VERSION ""

NS_ :

BS_:

BU_: ETH

BO_ 1298 TRCM_alertLog: 8 Vector__XXX
 SG_ TRCM_alertID M : 0|10@1+ (1,0) [0|0] "" Vector__XXX
 SG_ TRCM_alertState : 15|1@1+ (1,0) [0|0] "" Vector__XXX
 SG_ TRCM_a003_AssertID m3 : 16|16@1+ (1,0) [0|0] "" Vector__XXX
 SG_ TRCM_a005_busID0 m5 : 16|4@1+ (1,0) [0|0] "" Vector__XXX
 SG_ TRCM_a006_busID m6 : 16|4@1+ (1,0) [0|0] "" Vector__XXX
 SG_ TRCM_a007_messageId m7 : 16|16@1+ (1,0) [0|0] "" Vector__XXX
 SG_ TRCM_a008_messageId m8 : 16|16@1+ (1,0) [0|0] "" Vector__XXX
 SG_ TRCM_a009_messageId m9 : 16|16@1+ (1,0) [0|0] "" Vector__XXX
 SG_ TRCM_a010_messageId m10 : 16|16@1+ (1,0) [0|0] "" Vector__XXX
 SG_ TRCM_a011_lockedEdrLogCount m11 : 16|8@1+ (1,0) [0|0] "" Vector__XXX
 SG_ TRCM_a012_tempData m12 : 16|16@1- (0.06897,25) [0|0] "" Vector__XXX
 SG_ TRCM_a013_LogQueueFull m13 : 16|1@1+ (1,0) [0|0] "" Vector__XXX
 SG_ TRCM_a014_tempData m14 : 16|16@1- (0.06897,25) [0|0] "" Vector__XXX
 SG_ TRCM_a015_NVMMMemOverflow m15 : 16|1@1+ (1,0) [0|0] "" Vector__XXX
 SG_ TRCM_a016_NVMMRecordID m16 : 16|16@1+ (1,0) [0|0] "" Vector__XXX
 SG_ TRCM_a017_tempData m17 : 16|16@1- (0.06897,25) [0|0] "" Vector__XXX
 SG_ TRCM_a018_tempData m18 : 16|16@1- (0.06897,25) [0|0] "" Vector__XXX
 SG_ TRCM_a019_Task500usLate m19 : 16|1@1+ (1,0) [0|0] "" Vector__XXX
 SG_ TRCM_a020_Ana2_OK m20 : 16|1@1+ (1,0) [0|0] "" Vector__XXX
 SG_ TRCM_a021_Task1msLate m21 : 16|1@1+ (1,0) [0|0] "" Vector__XXX
 SG_ TRCM_a022_TaskInitErrorCount m22 : 16|8@1+ (1,0) [0|0] "" Vector__XXX
 SG_ TRCM_a023_Rate_Ref_OK_X m23 : 16|1@1+ (1,0) [0|0] "" Vector__XXX
 SG_ TRCM_a024_XLSelfTestAuto_OK_Z m24 : 16|1@1+ (1,0) [0|0] "" Vector__XXX
 SG_ TRCM_a025_busStatus m25 : 16|2@1+ (1,0) [0|0] "" Vector__XXX
 SG_ TRCM_a026_diagnosticFaultReason m26 : 16|3@1+ (1,0) [0|0] "" Vector__XXX
 SG_ TRCM_a027_deploymentDiagnosticFaultReason m27 : 16|3@1+ (1,0) [0|0] "" Vector__XXX
 SG_ TRCM_a030_logId m30 : 16|4@1+ (1,0) [0|0] "" Vector__XXX
 SG_ TRCM_a031_uds_bytes_0 m31 : 16|8@1+ (1,0) [0|0] "" Vector__XXX
 SG_ TRCM_a032_logCrc m32 : 16|32@1+ (1,0) [0|0] "" Vector__XXX
 SG_ TRCM_a033_logCrc m33 : 16|32@1+ (1,0) [0|0] "" Vector__XXX
 SG_ TRCM_a036_collisionType m36 : 16|4@1+ (1,0) [0|0] "" Vector__XXX
 SG_ TRCM_a037_nearDeployFront m37 : 16|1@1+ (1,0) [0|0] "" Vector__XXX
 SG_ TRCM_a038_stuckLowOrOpenCircuit m38 : 16|1@1+ (1,0) [0|0] "" Vector__XXX
 SG_ TRCM_a039_stuckLowOrOpenCircuit m39 : 16|1@1+ (1,0) [0|0] "" Vector__XXX
 SG_ TRCM_a040_airbagAsicsFaultReason m40 : 16|3@1+ (1,0) [0|0] "" Vector__XXX
 SG_ TRCM_a041_CPULoadTotal m41 : 16|8@1+ (1,0) [0|0] "" Vector__XXX
 SG_ TRCM_a042_Usage1msTask m42 : 16|8@1+ (1,0) [0|0] "" Vector__XXX
 SG_ TRCM_a043_CallTrace0 m43 : 16|24@1+ (1,0) [0|0] "" Vector__XXX
 SG_ TRCM_a044_CallTrace0 m44 : 16|24@1+ (1,0) [0|0] "" Vector__XXX
 SG_ TRCM_a045_CallTrace0 m45 : 16|24@1+ (1,0) [0|0] "" Vector__XXX
 SG_ TRCM_a046_CallTrace0 m46 : 16|24@1+ (1,0) [0|0] "" Vector__XXX
 SG_ TRCM_a049_retryCount m49 : 16|4@1+ (1,0) [0|0] "" Vector__XXX
 SG_ TRCM_a051_airbagAsicStartupDiagnosticsOngoing m51 : 16|1@1+ (1,0) [0|0] "" Vector__XXX
 SG_ TRCM_a057_VEH_cpControl m57 : 16|1@1+ (1,0) [0|0] "" Vector__XXX
 SG_ TRCM_a058_voltageDrop m58 : 16|12@1+ (0.005443676098,0) [0|0] "" Vector__XXX
 SG_ TRCM_a059_voltageDrop m59 : 16|12@1+ (0.005443676098,0) [0|0] "" Vector__XXX
 SG_ TRCM_a060_lockoutDisabled m60 : 16|1@1+ (1,0) [0|0] "" Vector__XXX
 SG_ TRCM_a063_switchChannel m63 : 16|8@1+ (1,0) [0|0] "" Vector__XXX
 SG_ TRCM_a064_busBitField m64 : 16|8@1+ (1,0) [0|0] "" Vector__XXX
 SG_ TRCM_a065_vsafingFetVoltage m65 : 16|9@1+ (0.05,0) [0|0] "" Vector__XXX
 SG_ TRCM_a066_busVoltage m66 : 16|9@1+ (0.05,0) [0|0] "" Vector__XXX
 SG_ TRCM_a067_busVoltage m67 : 16|9@1+ (0.05,0) [0|0] "" Vector__XXX
 SG_ TRCM_a068_busVoltage m68 : 16|9@1+ (0.05,0) [0|0] "" Vector__XXX
 SG_ TRCM_a069_resetCause m69 : 16|4@1+ (1,0) [0|0] "" Vector__XXX
 SG_ TRCM_a070_crcOkay m70 : 16|1@1+ (1,0) [0|0] "" Vector__XXX
 SG_ TRCM_a072_crcOkay m72 : 16|1@1+ (1,0) [0|0] "" Vector__XXX
 SG_ TRCM_a074_received m74 : 16|16@1- (1,0) [0|0] "" Vector__XXX
 SG_ TRCM_a075_received m75 : 16|16@1- (1,0) [0|0] "" Vector__XXX
 SG_ TRCM_a076_received m76 : 16|16@1- (1,0) [0|0] "" Vector__XXX
 SG_ TRCM_a077_received m77 : 16|16@1- (1,0) [0|0] "" Vector__XXX
 SG_ TRCM_a078_channelIndex m78 : 16|8@1+ (1,0) [0|0] "" Vector__XXX
 SG_ TRCM_a082_RIPC_epbPrivateState m82 : 16|1@1+ (1,0) [0|0] "" Vector__XXX
 SG_ TRCM_a083_LIPC_epbPrivateState m83 : 16|1@1+ (1,0) [0|0] "" Vector__XXX
 SG_ TRCM_a084_CH_StatusC m84 : 16|1@1+ (1,0) [0|0] "" Vector__XXX
 SG_ TRCM_a085_PARTY_buttonStatus m85 : 16|1@1+ (1,0) [0|0] "" Vector__XXX
 SG_ TRCM_a086_VEH_LVBMS_statusHigh m86 : 16|1@1+ (1,0) [0|0] "" Vector__XXX
 SG_ TRCM_a087_VEH_temperature m87 : 16|1@1+ (1,0) [0|0] "" Vector__XXX
 SG_ TRCM_a088_VEH_temperature m88 : 16|1@1+ (1,0) [0|0] "" Vector__XXX
 SG_ TRCM_a089_PARTY_party1 m89 : 16|1@1+ (1,0) [0|0] "" Vector__XXX
 SG_ TRCM_a090_VEH_chNm m90 : 16|1@1+ (1,0) [0|0] "" Vector__XXX
 SG_ TRCM_a091_VEH_faultsAndExtras m91 : 16|1@1+ (1,0) [0|0] "" Vector__XXX
 SG_ TRCM_a092_VEH_restraintStatus m92 : 16|1@1+ (1,0) [0|0] "" Vector__XXX
 SG_ TRCM_a093_VEH_restraintStatus m93 : 16|1@1+ (1,0) [0|0] "" Vector__XXX
 SG_ TRCM_a094_VEH_sysStatus m94 : 16|1@1+ (1,0) [0|0] "" Vector__XXX
 SG_ TRCM_a095_PT_ptNm m95 : 16|1@1+ (1,0) [0|0] "" Vector__XXX
 SG_ TRCM_a096_VEH_status m96 : 16|1@1+ (1,0) [0|0] "" Vector__XXX
 SG_ TRCM_a097_VEH_HVStatus m97 : 16|1@1+ (1,0) [0|0] "" Vector__XXX
 SG_ TRCM_a098_CH_torque m98 : 16|1@1+ (1,0) [0|0] "" Vector__XXX
 SG_ TRCM_a099_VEH_oocStatus m99 : 16|1@1+ (1,0) [0|0] "" Vector__XXX
 SG_ TRCM_a100_VEH m100 : 16|1@1+ (1,0) [0|0] "" Vector__XXX
 SG_ TRCM_a101_VEH_state m101 : 16|1@1+ (1,0) [0|0] "" Vector__XXX
 SG_ TRCM_a102_VEH_faultsAndExtras m102 : 16|1@1+ (1,0) [0|0] "" Vector__XXX
 SG_ TRCM_a103_VEH_hvsNm m103 : 16|1@1+ (1,0) [0|0] "" Vector__XXX
 SG_ TRCM_a104_VEH_chNm m104 : 16|1@1+ (1,0) [0|0] "" Vector__XXX
 SG_ TRCM_a105_VEH_states m105 : 16|1@1+ (1,0) [0|0] "" Vector__XXX
 SG_ TRCM_a106_VEH_dcdcStatus m106 : 16|1@1+ (1,0) [0|0] "" Vector__XXX
 SG_ TRCM_a107_VEH_hvsNm m107 : 16|1@1+ (1,0) [0|0] "" Vector__XXX
 SG_ TRCM_a108_VEH_hvStatus m108 : 16|1@1+ (1,0) [0|0] "" Vector__XXX
 SG_ TRCM_a109_PARTY_status m109 : 16|1@1+ (1,0) [0|0] "" Vector__XXX
 SG_ TRCM_a110_VEH_carState m110 : 16|1@1+ (1,0) [0|0] "" Vector__XXX
 SG_ TRCM_a111_VEH_internalStatus m111 : 16|1@1+ (1,0) [0|0] "" Vector__XXX
 SG_ TRCM_a112_VEH_internalStatus m112 : 16|1@1+ (1,0) [0|0] "" Vector__XXX
 SG_ TRCM_a113_VEH_ethNm m113 : 16|1@1+ (1,0) [0|0] "" Vector__XXX
 SG_ TRCM_a114_PARTY_status m114 : 16|1@1+ (1,0) [0|0] "" Vector__XXX
 SG_ TRCM_a115_VEH_vehNm m115 : 16|1@1+ (1,0) [0|0] "" Vector__XXX
 SG_ TRCM_a116_PARTY_epbmStatus m116 : 16|1@1+ (1,0) [0|0] "" Vector__XXX
 SG_ TRCM_a117_BDY_epbmStatus m117 : 16|1@1+ (1,0) [0|0] "" Vector__XXX
 SG_ TRCM_a118_VEH_vehNm m118 : 16|1@1+ (1,0) [0|0] "" Vector__XXX
 SG_ TRCM_a119_VEH_steerAngle m119 : 16|1@1+ (1,0) [0|0] "" Vector__XXX
 SG_ TRCM_a120_PARTY_chassisCntl m120 : 16|1@1+ (1,0) [0|0] "" Vector__XXX
 SG_ TRCM_a135_crcOkay m135 : 16|1@1+ (1,0) [0|0] "" Vector__XXX
 SG_ TRCM_a137_rxFrame m137 : 16|32@1+ (1,0) [0|0] "" Vector__XXX
 SG_ TRCM_a138_rxFrame m138 : 16|32@1+ (1,0) [0|0] "" Vector__XXX
 SG_ TRCM_a145_noData m145 : 16|1@1+ (1,0) [0|0] "" Vector__XXX
 SG_ TRCM_a146_reason m146 : 16|3@1+ (1,0) [0|0] "" Vector__XXX
 SG_ TRCM_a147_shortToGround m147 : 16|1@1+ (1,0) [0|0] "" Vector__XXX
 SG_ TRCM_a148_customerSensorCode m148 : 16|12@1+ (1,0) [0|0] "" Vector__XXX
 SG_ TRCM_a149_channelIndex m149 : 16|8@1+ (1,0) [0|0] "" Vector__XXX
 SG_ TRCM_a150_noData m150 : 16|1@1+ (1,0) [0|0] "" Vector__XXX
 SG_ TRCM_a151_reason m151 : 16|3@1+ (1,0) [0|0] "" Vector__XXX
 SG_ TRCM_a152_shortToGround m152 : 16|1@1+ (1,0) [0|0] "" Vector__XXX
 SG_ TRCM_a153_customerSensorCode m153 : 16|12@1+ (1,0) [0|0] "" Vector__XXX
 SG_ TRCM_a154_channelIndex m154 : 16|8@1+ (1,0) [0|0] "" Vector__XXX
 SG_ TRCM_a155_noData m155 : 16|1@1+ (1,0) [0|0] "" Vector__XXX
 SG_ TRCM_a156_reason m156 : 16|3@1+ (1,0) [0|0] "" Vector__XXX
 SG_ TRCM_a157_shortToGround m157 : 16|1@1+ (1,0) [0|0] "" Vector__XXX
 SG_ TRCM_a158_customerSensorCode m158 : 16|12@1+ (1,0) [0|0] "" Vector__XXX
 SG_ TRCM_a159_channelIndex m159 : 16|8@1+ (1,0) [0|0] "" Vector__XXX
 SG_ TRCM_a160_noData m160 : 16|1@1+ (1,0) [0|0] "" Vector__XXX
 SG_ TRCM_a161_reason m161 : 16|3@1+ (1,0) [0|0] "" Vector__XXX
 SG_ TRCM_a162_shortToGround m162 : 16|1@1+ (1,0) [0|0] "" Vector__XXX
 SG_ TRCM_a163_customerSensorCode m163 : 16|12@1+ (1,0) [0|0] "" Vector__XXX
 SG_ TRCM_a164_channelIndex m164 : 16|8@1+ (1,0) [0|0] "" Vector__XXX
 SG_ TRCM_a165_noData m165 : 16|1@1+ (1,0) [0|0] "" Vector__XXX
 SG_ TRCM_a166_reason m166 : 16|3@1+ (1,0) [0|0] "" Vector__XXX
 SG_ TRCM_a167_shortToGround m167 : 16|1@1+ (1,0) [0|0] "" Vector__XXX
 SG_ TRCM_a168_customerSensorCode m168 : 16|12@1+ (1,0) [0|0] "" Vector__XXX
 SG_ TRCM_a169_channelIndex m169 : 16|8@1+ (1,0) [0|0] "" Vector__XXX
 SG_ TRCM_a170_noData m170 : 16|1@1+ (1,0) [0|0] "" Vector__XXX
 SG_ TRCM_a171_reason m171 : 16|3@1+ (1,0) [0|0] "" Vector__XXX
 SG_ TRCM_a172_shortToGround m172 : 16|1@1+ (1,0) [0|0] "" Vector__XXX
 SG_ TRCM_a173_customerSensorCode m173 : 16|12@1+ (1,0) [0|0] "" Vector__XXX
 SG_ TRCM_a174_channelIndex m174 : 16|8@1+ (1,0) [0|0] "" Vector__XXX
 SG_ TRCM_a175_noData m175 : 16|1@1+ (1,0) [0|0] "" Vector__XXX
 SG_ TRCM_a176_reason m176 : 16|3@1+ (1,0) [0|0] "" Vector__XXX
 SG_ TRCM_a177_shortToGround m177 : 16|1@1+ (1,0) [0|0] "" Vector__XXX
 SG_ TRCM_a178_customerSensorCode m178 : 16|12@1+ (1,0) [0|0] "" Vector__XXX
 SG_ TRCM_a179_channelIndex m179 : 16|8@1+ (1,0) [0|0] "" Vector__XXX
 SG_ TRCM_a200_noData m200 : 16|1@1+ (1,0) [0|0] "" Vector__XXX
 SG_ TRCM_a201_reason m201 : 16|3@1+ (1,0) [0|0] "" Vector__XXX
 SG_ TRCM_a202_shortToGround m202 : 16|1@1+ (1,0) [0|0] "" Vector__XXX
 SG_ TRCM_a203_customerSensorCode m203 : 16|12@1+ (1,0) [0|0] "" Vector__XXX
 SG_ TRCM_a204_channelIndex m204 : 16|8@1+ (1,0) [0|0] "" Vector__XXX
 SG_ TRCM_a205_noData m205 : 16|1@1+ (1,0) [0|0] "" Vector__XXX
 SG_ TRCM_a206_reason m206 : 16|3@1+ (1,0) [0|0] "" Vector__XXX
 SG_ TRCM_a207_shortToGround m207 : 16|1@1+ (1,0) [0|0] "" Vector__XXX
 SG_ TRCM_a208_customerSensorCode m208 : 16|12@1+ (1,0) [0|0] "" Vector__XXX
 SG_ TRCM_a209_channelIndex m209 : 16|8@1+ (1,0) [0|0] "" Vector__XXX
 SG_ TRCM_a272_Ana2_OK m272 : 16|1@1+ (1,0) [0|0] "" Vector__XXX
 SG_ TRCM_a273_Rate_Ref_OK_X m273 : 16|1@1+ (1,0) [0|0] "" Vector__XXX
 SG_ TRCM_a274_Rate_Ref_OK_Z m274 : 16|1@1+ (1,0) [0|0] "" Vector__XXX
 SG_ TRCM_a275_XLSelfTestAuto_OK_Z m275 : 16|1@1+ (1,0) [0|0] "" Vector__XXX
 SG_ TRCM_a276_watchdogBiteCount m276 : 16|8@1+ (1,0) [0|0] "" Vector__XXX
 SG_ TRCM_a332_groundLossError m332 : 16|1@1+ (1,0) [0|0] "" Vector__XXX
 SG_ TRCM_a333_groundLossError m333 : 16|1@1+ (1,0) [0|0] "" Vector__XXX
 SG_ TRCM_a334_groundLossError m334 : 16|1@1+ (1,0) [0|0] "" Vector__XXX
 SG_ TRCM_a335_groundLossError m335 : 16|1@1+ (1,0) [0|0] "" Vector__XXX
 SG_ TRCM_a336_groundLossError m336 : 16|1@1+ (1,0) [0|0] "" Vector__XXX
 SG_ TRCM_a337_groundLossError m337 : 16|1@1+ (1,0) [0|0] "" Vector__XXX
 SG_ TRCM_a340_groundLossError m340 : 16|1@1+ (1,0) [0|0] "" Vector__XXX
 SG_ TRCM_a341_groundLossError m341 : 16|1@1+ (1,0) [0|0] "" Vector__XXX
 SG_ TRCM_a342_groundLossError m342 : 16|1@1+ (1,0) [0|0] "" Vector__XXX
 SG_ TRCM_a343_groundLossError m343 : 16|1@1+ (1,0) [0|0] "" Vector__XXX
 SG_ TRCM_a344_groundLossError m344 : 16|1@1+ (1,0) [0|0] "" Vector__XXX
 SG_ TRCM_a345_groundLossError m345 : 16|1@1+ (1,0) [0|0] "" Vector__XXX
 SG_ TRCM_a346_groundLossError m346 : 16|1@1+ (1,0) [0|0] "" Vector__XXX
 SG_ TRCM_a347_groundLossError m347 : 16|1@1+ (1,0) [0|0] "" Vector__XXX
 SG_ TRCM_a348_groundLossError m348 : 16|1@1+ (1,0) [0|0] "" Vector__XXX
 SG_ TRCM_a349_groundLossError m349 : 16|1@1+ (1,0) [0|0] "" Vector__XXX
 SG_ TRCM_a350_groundLossError m350 : 16|1@1+ (1,0) [0|0] "" Vector__XXX
 SG_ TRCM_a351_groundLossError m351 : 16|1@1+ (1,0) [0|0] "" Vector__XXX
 SG_ TRCM_a352_groundLossError m352 : 16|1@1+ (1,0) [0|0] "" Vector__XXX
 SG_ TRCM_a353_groundLossError m353 : 16|1@1+ (1,0) [0|0] "" Vector__XXX
 SG_ TRCM_a354_groundLossError m354 : 16|1@1+ (1,0) [0|0] "" Vector__XXX
 SG_ TRCM_a355_groundLossError m355 : 16|1@1+ (1,0) [0|0] "" Vector__XXX
 SG_ TRCM_a387_resetSource m387 : 16|8@1+ (1,0) [0|0] "" Vector__XXX
 SG_ TRCM_a388_cpuLoadPercentage m388 : 16|20@1+ (0.0001,0) [0|0] "" Vector__XXX
 SG_ TRCM_a389_boostGroundLoss m389 : 16|1@1+ (1,0) [0|0] "" Vector__XXX
 SG_ TRCM_a390_clockStuckError m390 : 16|1@1+ (1,0) [0|0] "" Vector__XXX
 SG_ TRCM_a391_clockStuckError m391 : 16|1@1+ (1,0) [0|0] "" Vector__XXX
 SG_ TRCM_a392_clockStuckError m392 : 16|1@1+ (1,0) [0|0] "" Vector__XXX
 SG_ TRCM_a393_measurementRatio m393 : 16|7@1+ (1,0) [0|0] "" Vector__XXX
 SG_ TRCM_a394_parityIncorrect m394 : 16|1@1+ (1,0) [0|0] "" Vector__XXX
 SG_ TRCM_a396_errorType m396 : 16|2@1+ (1,0) [0|0] "" Vector__XXX
 SG_ TRCM_a397_errorType m397 : 16|3@1+ (1,0) [0|0] "" Vector__XXX
 SG_ TRCM_a398_oldAsicNvmValue m398 : 16|16@1+ (1,0) [0|0] "" Vector__XXX
 SG_ TRCM_a400_deploymentLoopNumber m400 : 16|5@1+ (1,0) [0|0] "" Vector__XXX
 SG_ TRCM_a401_deploymentLoopNumber m401 : 16|5@1+ (1,0) [0|0] "" Vector__XXX
 SG_ TRCM_a402_deploymentLoopNumber m402 : 16|5@1+ (1,0) [0|0] "" Vector__XXX
 SG_ TRCM_a403_deploymentLoopNumber m403 : 16|5@1+ (1,0) [0|0] "" Vector__XXX
 SG_ TRCM_a404_deploymentLoopNumber m404 : 16|5@1+ (1,0) [0|0] "" Vector__XXX
 SG_ TRCM_a405_deploymentLoopNumber m405 : 16|5@1+ (1,0) [0|0] "" Vector__XXX
 SG_ TRCM_a408_deploymentLoopNumber m408 : 16|5@1+ (1,0) [0|0] "" Vector__XXX
 SG_ TRCM_a409_deploymentLoopNumber m409 : 16|5@1+ (1,0) [0|0] "" Vector__XXX
 SG_ TRCM_a410_deploymentLoopNumber m410 : 16|5@1+ (1,0) [0|0] "" Vector__XXX
 SG_ TRCM_a411_deploymentLoopNumber m411 : 16|5@1+ (1,0) [0|0] "" Vector__XXX
 SG_ TRCM_a412_deploymentLoopNumber m412 : 16|5@1+ (1,0) [0|0] "" Vector__XXX
 SG_ TRCM_a413_deploymentLoopNumber m413 : 16|5@1+ (1,0) [0|0] "" Vector__XXX
 SG_ TRCM_a414_deploymentLoopNumber m414 : 16|5@1+ (1,0) [0|0] "" Vector__XXX
 SG_ TRCM_a415_deploymentLoopNumber m415 : 16|5@1+ (1,0) [0|0] "" Vector__XXX
 SG_ TRCM_a416_deploymentLoopNumber m416 : 16|5@1+ (1,0) [0|0] "" Vector__XXX
 SG_ TRCM_a417_deploymentLoopNumber m417 : 16|5@1+ (1,0) [0|0] "" Vector__XXX
 SG_ TRCM_a418_deploymentLoopNumber m418 : 16|5@1+ (1,0) [0|0] "" Vector__XXX
 SG_ TRCM_a419_deploymentLoopNumber m419 : 16|5@1+ (1,0) [0|0] "" Vector__XXX
 SG_ TRCM_a420_deploymentLoopNumber m420 : 16|5@1+ (1,0) [0|0] "" Vector__XXX
 SG_ TRCM_a421_deploymentLoopNumber m421 : 16|5@1+ (1,0) [0|0] "" Vector__XXX
 SG_ TRCM_a422_deploymentLoopNumber m422 : 16|5@1+ (1,0) [0|0] "" Vector__XXX
 SG_ TRCM_a423_deploymentLoopNumber m423 : 16|5@1+ (1,0) [0|0] "" Vector__XXX
 SG_ TRCM_a544_diodeCheck1DischargeTimeout m544 : 16|1@1+ (1,0) [0|0] "" Vector__XXX
 SG_ TRCM_a546_newChannelsFaulted m546 : 16|32@1+ (1,0) [0|0] "" Vector__XXX
 SG_ TRCM_a576_wakeDuration m576 : 16|32@1+ (0.5,0) [0|0] "" Vector__XXX
 SG_ TRCM_a577_wakeDuration m577 : 16|32@1+ (0.5,0) [0|0] "" Vector__XXX
 SG_ TRCM_a578_wakeDuration m578 : 16|32@1+ (0.5,0) [0|0] "" Vector__XXX
 SG_ TRCM_a600_powerStatusError m600 : 16|1@1+ (1,0) [0|0] "" Vector__XXX
 SG_ TRCM_a601_deploymentCounterAutoSafeVal m601 : 16|1@1+ (1,0) [0|0] "" Vector__XXX
 SG_ TRCM_a602_deploymentCounterAutoSafeVal m602 : 16|1@1+ (1,0) [0|0] "" Vector__XXX
 SG_ TRCM_a603_deploymentCounterAutoSafeVal m603 : 16|1@1+ (1,0) [0|0] "" Vector__XXX
 SG_ TRCM_a604_deploymentCounterAutoSafeVal m604 : 16|1@1+ (1,0) [0|0] "" Vector__XXX
 SG_ TRCM_a605_deploymentCounterAutoSafeVal m605 : 16|1@1+ (1,0) [0|0] "" Vector__XXX
 SG_ TRCM_a606_deploymentCounterAutoSafeVal m606 : 16|1@1+ (1,0) [0|0] "" Vector__XXX
 SG_ TRCM_a607_deploymentCounterAutoSafeVal m607 : 16|1@1+ (1,0) [0|0] "" Vector__XXX
 SG_ TRCM_a608_deploymentCounterAutoSafeVal m608 : 16|1@1+ (1,0) [0|0] "" Vector__XXX
 SG_ TRCM_a609_deploymentCounterAutoSafeVal m609 : 16|1@1+ (1,0) [0|0] "" Vector__XXX
 SG_ TRCM_a610_deploymentCounterAutoSafeVal m610 : 16|1@1+ (1,0) [0|0] "" Vector__XXX
 SG_ TRCM_a611_deploymentCounterAutoSafeVal m611 : 16|1@1+ (1,0) [0|0] "" Vector__XXX
 SG_ TRCM_a612_deploymentCounterAutoSafeVal m612 : 16|1@1+ (1,0) [0|0] "" Vector__XXX
 SG_ TRCM_a613_deploymentCounterAutoSafeVal m613 : 16|1@1+ (1,0) [0|0] "" Vector__XXX
 SG_ TRCM_a614_deploymentCounterAutoSafeVal m614 : 16|1@1+ (1,0) [0|0] "" Vector__XXX
 SG_ TRCM_a615_deploymentCounterAutoSafeVal m615 : 16|1@1+ (1,0) [0|0] "" Vector__XXX
 SG_ TRCM_a616_deploymentCounterAutoSafeVal m616 : 16|1@1+ (1,0) [0|0] "" Vector__XXX
 SG_ TRCM_a617_deploymentCounterAutoSafeVal m617 : 16|1@1+ (1,0) [0|0] "" Vector__XXX
 SG_ TRCM_a618_deploymentCounterAutoSafeVal m618 : 16|1@1+ (1,0) [0|0] "" Vector__XXX
 SG_ TRCM_a619_deploymentCounterAutoSafeVal m619 : 16|1@1+ (1,0) [0|0] "" Vector__XXX
 SG_ TRCM_a620_deploymentCounterAutoSafeVal m620 : 16|1@1+ (1,0) [0|0] "" Vector__XXX
 SG_ TRCM_a621_deploymentCounterAutoSafeVal m621 : 16|1@1+ (1,0) [0|0] "" Vector__XXX
 SG_ TRCM_a622_deploymentCounterAutoSafeVal m622 : 16|1@1+ (1,0) [0|0] "" Vector__XXX
 SG_ TRCM_a623_deploymentCounterAutoSafeVal m623 : 16|1@1+ (1,0) [0|0] "" Vector__XXX
 SG_ TRCM_a624_deploymentCounterAutoSafeVal m624 : 16|1@1+ (1,0) [0|0] "" Vector__XXX
 SG_ TRCM_a625_deploymentCounterAutoSafeVal m625 : 16|1@1+ (1,0) [0|0] "" Vector__XXX
 SG_ TRCM_a626_deploymentCounterAutoSafeVal m626 : 16|1@1+ (1,0) [0|0] "" Vector__XXX
 SG_ TRCM_a627_deploymentCounterAutoSafeVal m627 : 16|1@1+ (1,0) [0|0] "" Vector__XXX
 SG_ TRCM_a628_deploymentCounterAutoSafeVal m628 : 16|1@1+ (1,0) [0|0] "" Vector__XXX
 SG_ TRCM_a629_deploymentCounterAutoSafeVal m629 : 16|1@1+ (1,0) [0|0] "" Vector__XXX
 SG_ TRCM_a630_deploymentCounterAutoSafeVal m630 : 16|1@1+ (1,0) [0|0] "" Vector__XXX
 SG_ TRCM_a631_deploymentCounterAutoSafeVal m631 : 16|1@1+ (1,0) [0|0] "" Vector__XXX
 SG_ TRCM_a632_deploymentCounterAutoSafeVal m632 : 16|1@1+ (1,0) [0|0] "" Vector__XXX
 SG_ TRCM_a633_failureSource m633 : 16|3@1+ (1,0) [0|0] "" Vector__XXX
 SG_ TRCM_a634_failureSource m634 : 16|3@1+ (1,0) [0|0] "" Vector__XXX
 SG_ TRCM_a635_failureSource m635 : 16|2@1+ (1,0) [0|0] "" Vector__XXX
 SG_ TRCM_a636_obtainedRegisterValue m636 : 16|16@1+ (1,0) [0|0] "" Vector__XXX
 SG_ TRCM_a637_failedRegisterNumber m637 : 16|8@1+ (1,0) [0|0] "" Vector__XXX
 SG_ TRCM_a638_failureSource m638 : 16|3@1+ (1,0) [0|0] "" Vector__XXX
 SG_ TRCM_a639_failureSource m639 : 16|3@1+ (1,0) [0|0] "" Vector__XXX
 SG_ TRCM_a640_failureSource m640 : 16|3@1+ (1,0) [0|0] "" Vector__XXX
 SG_ TRCM_a641_observedOscillatorCounts m641 : 16|8@1+ (1,0) [0|0] "" Vector__XXX
 SG_ TRCM_a642_failureSource m642 : 16|3@1+ (1,0) [0|0] "" Vector__XXX
 SG_ TRCM_a643_stage m643 : 16|2@1+ (1,0) [0|0] "" Vector__XXX
 SG_ TRCM_a644_devstatCrcError m644 : 16|1@1+ (1,0) [0|0] "" Vector__XXX
 SG_ TRCM_a645_resetRetryCount m645 : 16|8@1+ (1,0) [0|0] "" Vector__XXX
 SG_ TRCM_a013_ClearQueueFull m13 : 17|1@1+ (1,0) [0|0] "" Vector__XXX
 SG_ TRCM_a015_NVMMFilesystemError m15 : 17|1@1+ (1,0) [0|0] "" Vector__XXX
 SG_ TRCM_a019_Task500usStarved m19 : 17|1@1+ (1,0) [0|0] "" Vector__XXX
 SG_ TRCM_a020_Ana1_OK m20 : 17|1@1+ (1,0) [0|0] "" Vector__XXX
 SG_ TRCM_a021_Task1msStarved m21 : 17|1@1+ (1,0) [0|0] "" Vector__XXX
 SG_ TRCM_a023_CP_OK_X m23 : 17|1@1+ (1,0) [0|0] "" Vector__XXX
 SG_ TRCM_a024_XLSelfTestAuto_OK_Y m24 : 17|1@1+ (1,0) [0|0] "" Vector__XXX
 SG_ TRCM_a037_nearDeployRear m37 : 17|1@1+ (1,0) [0|0] "" Vector__XXX
 SG_ TRCM_a038_stuckHigh m38 : 17|1@1+ (1,0) [0|0] "" Vector__XXX
 SG_ TRCM_a039_stuckHigh m39 : 17|1@1+ (1,0) [0|0] "" Vector__XXX
 SG_ TRCM_a051_erCapsCharging m51 : 17|1@1+ (1,0) [0|0] "" Vector__XXX
 SG_ TRCM_a060_resetUnlocked m60 : 17|1@1+ (1,0) [0|0] "" Vector__XXX
 SG_ TRCM_a070_S_OK_C m70 : 17|1@1+ (1,0) [0|0] "" Vector__XXX
 SG_ TRCM_a072_parityOkay m72 : 17|1@1+ (1,0) [0|0] "" Vector__XXX
 SG_ TRCM_a082_RIPC_remoteHSD m82 : 17|1@1+ (1,0) [0|0] "" Vector__XXX
 SG_ TRCM_a083_LIPC_remoteHSD m83 : 17|1@1+ (1,0) [0|0] "" Vector__XXX
 SG_ TRCM_a086_VEH_LVBMS_statusLow m86 : 17|1@1+ (1,0) [0|0] "" Vector__XXX
 SG_ TRCM_a087_VEH_thermalControl m87 : 17|1@1+ (1,0) [0|0] "" Vector__XXX
 SG_ TRCM_a088_VEH_thermalControl m88 : 17|1@1+ (1,0) [0|0] "" Vector__XXX
 SG_ TRCM_a089_PARTY_status m89 : 17|1@1+ (1,0) [0|0] "" Vector__XXX
 SG_ TRCM_a090_VEH_state m90 : 17|1@1+ (1,0) [0|0] "" Vector__XXX
 SG_ TRCM_a091_VEH_info m91 : 17|1@1+ (1,0) [0|0] "" Vector__XXX
 SG_ TRCM_a092_VEH_switchStatus m92 : 17|1@1+ (1,0) [0|0] "" Vector__XXX
 SG_ TRCM_a093_VEH_switchStatus m93 : 17|1@1+ (1,0) [0|0] "" Vector__XXX
 SG_ TRCM_a094_PARTY_sysStatus m94 : 17|1@1+ (1,0) [0|0] "" Vector__XXX
 SG_ TRCM_a095_PT_status m95 : 17|1@1+ (1,0) [0|0] "" Vector__XXX
 SG_ TRCM_a096_CH_status m96 : 17|1@1+ (1,0) [0|0] "" Vector__XXX
 SG_ TRCM_a097_VEH_state m97 : 17|1@1+ (1,0) [0|0] "" Vector__XXX
 SG_ TRCM_a098_VEH_hvStatus m98 : 17|1@1+ (1,0) [0|0] "" Vector__XXX
 SG_ TRCM_a100_PARTY m100 : 17|1@1+ (1,0) [0|0] "" Vector__XXX
 SG_ TRCM_a101_PARTY_locState m101 : 17|1@1+ (1,0) [0|0] "" Vector__XXX
 SG_ TRCM_a102_VEH_feedbackStatus m102 : 17|1@1+ (1,0) [0|0] "" Vector__XXX
 SG_ TRCM_a103_VEH_vehNm m103 : 17|1@1+ (1,0) [0|0] "" Vector__XXX
 SG_ TRCM_a104_VEH_bodyControls m104 : 17|1@1+ (1,0) [0|0] "" Vector__XXX
 SG_ TRCM_a105_VEH_chNm m105 : 17|1@1+ (1,0) [0|0] "" Vector__XXX
 SG_ TRCM_a106_VEH_thermalControl m106 : 17|1@1+ (1,0) [0|0] "" Vector__XXX
 SG_ TRCM_a107_VEH_vehNm m107 : 17|1@1+ (1,0) [0|0] "" Vector__XXX
 SG_ TRCM_a108_VEH_temperature m108 : 17|1@1+ (1,0) [0|0] "" Vector__XXX
 SG_ TRCM_a109_PARTY_inertial2 m109 : 17|1@1+ (1,0) [0|0] "" Vector__XXX
 SG_ TRCM_a110_VEH_carConfig m110 : 17|1@1+ (1,0) [0|0] "" Vector__XXX
 SG_ TRCM_a111_VEH_status m111 : 17|1@1+ (1,0) [0|0] "" Vector__XXX
 SG_ TRCM_a112_VEH_status m112 : 17|1@1+ (1,0) [0|0] "" Vector__XXX
 SG_ TRCM_a113_VEH_hvacRequest m113 : 17|1@1+ (1,0) [0|0] "" Vector__XXX
 SG_ TRCM_a114_PARTY_wheelSpeeds m114 : 17|1@1+ (1,0) [0|0] "" Vector__XXX
 SG_ TRCM_a115_VEH_authentication m115 : 17|1@1+ (1,0) [0|0] "" Vector__XXX
 SG_ TRCM_a116_VEH_vehNm m116 : 17|1@1+ (1,0) [0|0] "" Vector__XXX
 SG_ TRCM_a117_BDY_restraintStatus m117 : 17|1@1+ (1,0) [0|0] "" Vector__XXX
 SG_ TRCM_a118_VEH_lighting m118 : 17|1@1+ (1,0) [0|0] "" Vector__XXX
 SG_ TRCM_a119_VEH_leftStalk m119 : 17|1@1+ (1,0) [0|0] "" Vector__XXX
 SG_ TRCM_a120_VEH_systemStatus m120 : 17|1@1+ (1,0) [0|0] "" Vector__XXX
 SG_ TRCM_a135_S_OK_C m135 : 17|1@1+ (1,0) [0|0] "" Vector__XXX
 SG_ TRCM_a145_wrongTimeSlot m145 : 17|1@1+ (1,0) [0|0] "" Vector__XXX
 SG_ TRCM_a147_shortToBattery m147 : 17|1@1+ (1,0) [0|0] "" Vector__XXX
 SG_ TRCM_a150_wrongTimeSlot m150 : 17|1@1+ (1,0) [0|0] "" Vector__XXX
 SG_ TRCM_a152_shortToBattery m152 : 17|1@1+ (1,0) [0|0] "" Vector__XXX
 SG_ TRCM_a155_wrongTimeSlot m155 : 17|1@1+ (1,0) [0|0] "" Vector__XXX
 SG_ TRCM_a157_shortToBattery m157 : 17|1@1+ (1,0) [0|0] "" Vector__XXX
 SG_ TRCM_a160_wrongTimeSlot m160 : 17|1@1+ (1,0) [0|0] "" Vector__XXX
 SG_ TRCM_a162_shortToBattery m162 : 17|1@1+ (1,0) [0|0] "" Vector__XXX
 SG_ TRCM_a165_wrongTimeSlot m165 : 17|1@1+ (1,0) [0|0] "" Vector__XXX
 SG_ TRCM_a167_shortToBattery m167 : 17|1@1+ (1,0) [0|0] "" Vector__XXX
 SG_ TRCM_a170_wrongTimeSlot m170 : 17|1@1+ (1,0) [0|0] "" Vector__XXX
 SG_ TRCM_a172_shortToBattery m172 : 17|1@1+ (1,0) [0|0] "" Vector__XXX
 SG_ TRCM_a175_wrongTimeSlot m175 : 17|1@1+ (1,0) [0|0] "" Vector__XXX
 SG_ TRCM_a177_shortToBattery m177 : 17|1@1+ (1,0) [0|0] "" Vector__XXX
 SG_ TRCM_a200_wrongTimeSlot m200 : 17|1@1+ (1,0) [0|0] "" Vector__XXX
 SG_ TRCM_a202_shortToBattery m202 : 17|1@1+ (1,0) [0|0] "" Vector__XXX
 SG_ TRCM_a205_wrongTimeSlot m205 : 17|1@1+ (1,0) [0|0] "" Vector__XXX
 SG_ TRCM_a207_shortToBattery m207 : 17|1@1+ (1,0) [0|0] "" Vector__XXX
 SG_ TRCM_a272_Ana1_OK m272 : 17|1@1+ (1,0) [0|0] "" Vector__XXX
 SG_ TRCM_a273_CP_OK_X m273 : 17|1@1+ (1,0) [0|0] "" Vector__XXX
 SG_ TRCM_a274_CP_OK_Z m274 : 17|1@1+ (1,0) [0|0] "" Vector__XXX
 SG_ TRCM_a275_XLSelfTestAuto_OK_Y m275 : 17|1@1+ (1,0) [0|0] "" Vector__XXX
 SG_ TRCM_a332_overcurrentError m332 : 17|1@1+ (1,0) [0|0] "" Vector__XXX
 SG_ TRCM_a333_overcurrentError m333 : 17|1@1+ (1,0) [0|0] "" Vector__XXX
 SG_ TRCM_a334_overcurrentError m334 : 17|1@1+ (1,0) [0|0] "" Vector__XXX
 SG_ TRCM_a335_overcurrentError m335 : 17|1@1+ (1,0) [0|0] "" Vector__XXX
 SG_ TRCM_a336_overcurrentError m336 : 17|1@1+ (1,0) [0|0] "" Vector__XXX
 SG_ TRCM_a337_overcurrentError m337 : 17|1@1+ (1,0) [0|0] "" Vector__XXX
 SG_ TRCM_a340_overcurrentError m340 : 17|1@1+ (1,0) [0|0] "" Vector__XXX
 SG_ TRCM_a341_overcurrentError m341 : 17|1@1+ (1,0) [0|0] "" Vector__XXX
 SG_ TRCM_a342_overcurrentError m342 : 17|1@1+ (1,0) [0|0] "" Vector__XXX
 SG_ TRCM_a343_overcurrentError m343 : 17|1@1+ (1,0) [0|0] "" Vector__XXX
 SG_ TRCM_a344_overcurrentError m344 : 17|1@1+ (1,0) [0|0] "" Vector__XXX
 SG_ TRCM_a345_overcurrentError m345 : 17|1@1+ (1,0) [0|0] "" Vector__XXX
 SG_ TRCM_a346_overcurrentError m346 : 17|1@1+ (1,0) [0|0] "" Vector__XXX
 SG_ TRCM_a347_overcurrentError m347 : 17|1@1+ (1,0) [0|0] "" Vector__XXX
 SG_ TRCM_a348_overcurrentError m348 : 17|1@1+ (1,0) [0|0] "" Vector__XXX
 SG_ TRCM_a349_overcurrentError m349 : 17|1@1+ (1,0) [0|0] "" Vector__XXX
 SG_ TRCM_a350_overcurrentError m350 : 17|1@1+ (1,0) [0|0] "" Vector__XXX
 SG_ TRCM_a351_overcurrentError m351 : 17|1@1+ (1,0) [0|0] "" Vector__XXX
 SG_ TRCM_a352_overcurrentError m352 : 17|1@1+ (1,0) [0|0] "" Vector__XXX
 SG_ TRCM_a353_overcurrentError m353 : 17|1@1+ (1,0) [0|0] "" Vector__XXX
 SG_ TRCM_a354_overcurrentError m354 : 17|1@1+ (1,0) [0|0] "" Vector__XXX
 SG_ TRCM_a355_overcurrentError m355 : 17|1@1+ (1,0) [0|0] "" Vector__XXX
 SG_ TRCM_a389_sysBoostOverTemperature m389 : 17|1@1+ (1,0) [0|0] "" Vector__XXX
 SG_ TRCM_a390_frequencyErrorCode m390 : 17|2@1+ (1,0) [0|0] "" Vector__XXX
 SG_ TRCM_a391_frequencyErrorCode m391 : 17|2@1+ (1,0) [0|0] "" Vector__XXX
 SG_ TRCM_a392_FrequencyErrorCode m392 : 17|2@1+ (1,0) [0|0] "" Vector__XXX
 SG_ TRCM_a394_ERR_RID m394 : 17|1@1+ (1,0) [0|0] "" Vector__XXX
 SG_ TRCM_a544_diodeCheck1Failed m544 : 17|1@1+ (1,0) [0|0] "" Vector__XXX
 SG_ TRCM_a600_nvmDownloadError m600 : 17|1@1+ (1,0) [0|0] "" Vector__XXX
 SG_ TRCM_a601_deploymentCounterDwellTimeVal m601 : 17|1@1+ (1,0) [0|0] "" Vector__XXX
 SG_ TRCM_a602_deploymentCounterDwellTimeVal m602 : 17|1@1+ (1,0) [0|0] "" Vector__XXX
 SG_ TRCM_a603_deploymentCounterDwellTimeVal m603 : 17|1@1+ (1,0) [0|0] "" Vector__XXX
 SG_ TRCM_a604_deploymentCounterDwellTimeVal m604 : 17|1@1+ (1,0) [0|0] "" Vector__XXX
 SG_ TRCM_a605_deploymentCounterDwellTimeVal m605 : 17|1@1+ (1,0) [0|0] "" Vector__XXX
 SG_ TRCM_a606_deploymentCounterDwellTimeVal m606 : 17|1@1+ (1,0) [0|0] "" Vector__XXX
 SG_ TRCM_a607_deploymentCounterDwellTimeVal m607 : 17|1@1+ (1,0) [0|0] "" Vector__XXX
 SG_ TRCM_a608_deploymentCounterDwellTimeVal m608 : 17|1@1+ (1,0) [0|0] "" Vector__XXX
 SG_ TRCM_a609_deploymentCounterDwellTimeVal m609 : 17|1@1+ (1,0) [0|0] "" Vector__XXX
 SG_ TRCM_a610_deploymentCounterDwellTimeVal m610 : 17|1@1+ (1,0) [0|0] "" Vector__XXX
 SG_ TRCM_a611_deploymentCounterDwellTimeVal m611 : 17|1@1+ (1,0) [0|0] "" Vector__XXX
 SG_ TRCM_a612_deploymentCounterDwellTimeVal m612 : 17|1@1+ (1,0) [0|0] "" Vector__XXX
 SG_ TRCM_a613_deploymentCounterDwellTimeVal m613 : 17|1@1+ (1,0) [0|0] "" Vector__XXX
 SG_ TRCM_a614_deploymentCounterDwellTimeVal m614 : 17|1@1+ (1,0) [0|0] "" Vector__XXX
 SG_ TRCM_a615_deploymentCounterDwellTimeVal m615 : 17|1@1+ (1,0) [0|0] "" Vector__XXX
 SG_ TRCM_a616_deploymentCounterDwellTimeVal m616 : 17|1@1+ (1,0) [0|0] "" Vector__XXX
 SG_ TRCM_a617_deploymentCounterDwellTimeVal m617 : 17|1@1+ (1,0) [0|0] "" Vector__XXX
 SG_ TRCM_a618_deploymentCounterDwellTimeVal m618 : 17|1@1+ (1,0) [0|0] "" Vector__XXX
 SG_ TRCM_a619_deploymentCounterDwellTimeVal m619 : 17|1@1+ (1,0) [0|0] "" Vector__XXX
 SG_ TRCM_a620_deploymentCounterDwellTimeVal m620 : 17|1@1+ (1,0) [0|0] "" Vector__XXX
 SG_ TRCM_a621_deploymentCounterDwellTimeVal m621 : 17|1@1+ (1,0) [0|0] "" Vector__XXX
 SG_ TRCM_a622_deploymentCounterDwellTimeVal m622 : 17|1@1+ (1,0) [0|0] "" Vector__XXX
 SG_ TRCM_a623_deploymentCounterDwellTimeVal m623 : 17|1@1+ (1,0) [0|0] "" Vector__XXX
 SG_ TRCM_a624_deploymentCounterDwellTimeVal m624 : 17|1@1+ (1,0) [0|0] "" Vector__XXX
 SG_ TRCM_a625_deploymentCounterDwellTimeVal m625 : 17|1@1+ (1,0) [0|0] "" Vector__XXX
 SG_ TRCM_a626_deploymentCounterDwellTimeVal m626 : 17|1@1+ (1,0) [0|0] "" Vector__XXX
 SG_ TRCM_a627_deploymentCounterDwellTimeVal m627 : 17|1@1+ (1,0) [0|0] "" Vector__XXX
 SG_ TRCM_a628_deploymentCounterDwellTimeVal m628 : 17|1@1+ (1,0) [0|0] "" Vector__XXX
 SG_ TRCM_a629_deploymentCounterDwellTimeVal m629 : 17|1@1+ (1,0) [0|0] "" Vector__XXX
 SG_ TRCM_a630_deploymentCounterDwellTimeVal m630 : 17|1@1+ (1,0) [0|0] "" Vector__XXX
 SG_ TRCM_a631_deploymentCounterDwellTimeVal m631 : 17|1@1+ (1,0) [0|0] "" Vector__XXX
 SG_ TRCM_a632_deploymentCounterDwellTimeVal m632 : 17|1@1+ (1,0) [0|0] "" Vector__XXX
 SG_ TRCM_a644_devstatValueError m644 : 17|1@1+ (1,0) [0|0] "" Vector__XXX
 SG_ TRCM_a015_NVMMRecordIDError m15 : 18|1@1+ (1,0) [0|0] "" Vector__XXX
 SG_ TRCM_a019_Task500usMissed m19 : 18|1@1+ (1,0) [0|0] "" Vector__XXX
 SG_ TRCM_a020_NVM_FLIP_NO_ERR m20 : 18|1@1+ (1,0) [0|0] "" Vector__XXX
 SG_ TRCM_a021_Task1msMissed m21 : 18|1@1+ (1,0) [0|0] "" Vector__XXX
 SG_ TRCM_a023_DDSDistOK_X m23 : 18|1@1+ (1,0) [0|0] "" Vector__XXX
 SG_ TRCM_a024_XLSelfTestAuto_OK_X m24 : 18|1@1+ (1,0) [0|0] "" Vector__XXX
 SG_ TRCM_a037_nearDeployLeft m37 : 18|1@1+ (1,0) [0|0] "" Vector__XXX
 SG_ TRCM_a038_overCurrent m38 : 18|1@1+ (1,0) [0|0] "" Vector__XXX
 SG_ TRCM_a039_overCurrent m39 : 18|1@1+ (1,0) [0|0] "" Vector__XXX
 SG_ TRCM_a051_deploymentLoopDiagnosticsNotRun m51 : 18|1@1+ (1,0) [0|0] "" Vector__XXX
 SG_ TRCM_a070_S_OK_AZ m70 : 18|1@1+ (1,0) [0|0] "" Vector__XXX
 SG_ TRCM_a072_statusDataOkay m72 : 18|1@1+ (1,0) [0|0] "" Vector__XXX
 SG_ TRCM_a082_RIPC_railStatus m82 : 18|1@1+ (1,0) [0|0] "" Vector__XXX
 SG_ TRCM_a083_LIPC_railStatus m83 : 18|1@1+ (1,0) [0|0] "" Vector__XXX
 SG_ TRCM_a086_VEH_status m86 : 18|1@1+ (1,0) [0|0] "" Vector__XXX
 SG_ TRCM_a087_VEH_torque m87 : 18|1@1+ (1,0) [0|0] "" Vector__XXX
 SG_ TRCM_a088_VEH_torque m88 : 18|1@1+ (1,0) [0|0] "" Vector__XXX
 SG_ TRCM_a089_VEH_status m89 : 18|1@1+ (1,0) [0|0] "" Vector__XXX
 SG_ TRCM_a090_PARTY_eacMonitor m90 : 18|1@1+ (1,0) [0|0] "" Vector__XXX
 SG_ TRCM_a091_VEH_state m91 : 18|1@1+ (1,0) [0|0] "" Vector__XXX
 SG_ TRCM_a092_VEH_seatStatus2 m92 : 18|1@1+ (1,0) [0|0] "" Vector__XXX
 SG_ TRCM_a093_VEH_seatStatus2 m93 : 18|1@1+ (1,0) [0|0] "" Vector__XXX
 SG_ TRCM_a098_VEH_status m98 : 18|1@1+ (1,0) [0|0] "" Vector__XXX
 SG_ TRCM_a100_PT m100 : 18|1@1+ (1,0) [0|0] "" Vector__XXX
 SG_ TRCM_a101_LIPC_externalWatchdogHeartBeat m101 : 18|1@1+ (1,0) [0|0] "" Vector__XXX
 SG_ TRCM_a102_VEH_sensorStatus m102 : 18|1@1+ (1,0) [0|0] "" Vector__XXX
 SG_ TRCM_a103_VEH_status m103 : 18|1@1+ (1,0) [0|0] "" Vector__XXX
 SG_ TRCM_a104_VEH_bodyControls3 m104 : 18|1@1+ (1,0) [0|0] "" Vector__XXX
 SG_ TRCM_a105_VEH_dampingStates m105 : 18|1@1+ (1,0) [0|0] "" Vector__XXX
 SG_ TRCM_a106_VEH_dcdcRailStatus m106 : 18|1@1+ (1,0) [0|0] "" Vector__XXX
 SG_ TRCM_a107_VEH_status m107 : 18|1@1+ (1,0) [0|0] "" Vector__XXX
 SG_ TRCM_a108_VEH_thermalControl m108 : 18|1@1+ (1,0) [0|0] "" Vector__XXX
 SG_ TRCM_a109_PARTY_nearDeploy m109 : 18|1@1+ (1,0) [0|0] "" Vector__XXX
 SG_ TRCM_a110_VEH_time m110 : 18|1@1+ (1,0) [0|0] "" Vector__XXX
 SG_ TRCM_a111_VEH_vehNm m111 : 18|1@1+ (1,0) [0|0] "" Vector__XXX
 SG_ TRCM_a112_VEH_vehNm m112 : 18|1@1+ (1,0) [0|0] "" Vector__XXX
 SG_ TRCM_a113_VEH_chargeRequest m113 : 18|1@1+ (1,0) [0|0] "" Vector__XXX
 SG_ TRCM_a114_VEH_wheelSpeeds m114 : 18|1@1+ (1,0) [0|0] "" Vector__XXX
 SG_ TRCM_a115_VEH_BLEResetRequest m115 : 18|1@1+ (1,0) [0|0] "" Vector__XXX
 SG_ TRCM_a116_VEH_hvacRequest m116 : 18|1@1+ (1,0) [0|0] "" Vector__XXX
 SG_ TRCM_a117_VEH_prndStatus m117 : 18|1@1+ (1,0) [0|0] "" Vector__XXX
 SG_ TRCM_a118_VEH_sensors m118 : 18|1@1+ (1,0) [0|0] "" Vector__XXX
 SG_ TRCM_a119_VEH_rightStalk m119 : 18|1@1+ (1,0) [0|0] "" Vector__XXX
 SG_ TRCM_a120_CH_chassisCntl m120 : 18|1@1+ (1,0) [0|0] "" Vector__XXX
 SG_ TRCM_a135_S_OK_AZ m135 : 18|1@1+ (1,0) [0|0] "" Vector__XXX
 SG_ TRCM_a145_invalidData m145 : 18|1@1+ (1,0) [0|0] "" Vector__XXX
 SG_ TRCM_a147_openCircuit m147 : 18|1@1+ (1,0) [0|0] "" Vector__XXX
 SG_ TRCM_a150_invalidData m150 : 18|1@1+ (1,0) [0|0] "" Vector__XXX
 SG_ TRCM_a152_openCircuit m152 : 18|1@1+ (1,0) [0|0] "" Vector__XXX
 SG_ TRCM_a155_invalidData m155 : 18|1@1+ (1,0) [0|0] "" Vector__XXX
 SG_ TRCM_a157_openCircuit m157 : 18|1@1+ (1,0) [0|0] "" Vector__XXX
 SG_ TRCM_a160_invalidData m160 : 18|1@1+ (1,0) [0|0] "" Vector__XXX
 SG_ TRCM_a162_openCircuit m162 : 18|1@1+ (1,0) [0|0] "" Vector__XXX
 SG_ TRCM_a165_invalidData m165 : 18|1@1+ (1,0) [0|0] "" Vector__XXX
 SG_ TRCM_a167_openCircuit m167 : 18|1@1+ (1,0) [0|0] "" Vector__XXX
 SG_ TRCM_a170_invalidData m170 : 18|1@1+ (1,0) [0|0] "" Vector__XXX
 SG_ TRCM_a172_openCircuit m172 : 18|1@1+ (1,0) [0|0] "" Vector__XXX
 SG_ TRCM_a175_invalidData m175 : 18|1@1+ (1,0) [0|0] "" Vector__XXX
 SG_ TRCM_a177_openCircuit m177 : 18|1@1+ (1,0) [0|0] "" Vector__XXX
 SG_ TRCM_a200_invalidData m200 : 18|1@1+ (1,0) [0|0] "" Vector__XXX
 SG_ TRCM_a202_openCircuit m202 : 18|1@1+ (1,0) [0|0] "" Vector__XXX
 SG_ TRCM_a205_invalidData m205 : 18|1@1+ (1,0) [0|0] "" Vector__XXX
 SG_ TRCM_a207_openCircuit m207 : 18|1@1+ (1,0) [0|0] "" Vector__XXX
 SG_ TRCM_a272_NVM_FLIP_NO_ERR m272 : 18|1@1+ (1,0) [0|0] "" Vector__XXX
 SG_ TRCM_a273_DDSDistOK_X m273 : 18|1@1+ (1,0) [0|0] "" Vector__XXX
 SG_ TRCM_a274_DDSDistOK_Z m274 : 18|1@1+ (1,0) [0|0] "" Vector__XXX
 SG_ TRCM_a275_XLSelfTestAuto_OK_X m275 : 18|1@1+ (1,0) [0|0] "" Vector__XXX
 SG_ TRCM_a332_overvoltageError m332 : 18|1@1+ (1,0) [0|0] "" Vector__XXX
 SG_ TRCM_a333_overvoltageError m333 : 18|1@1+ (1,0) [0|0] "" Vector__XXX
 SG_ TRCM_a334_overvoltageError m334 : 18|1@1+ (1,0) [0|0] "" Vector__XXX
 SG_ TRCM_a335_overvoltageError m335 : 18|1@1+ (1,0) [0|0] "" Vector__XXX
 SG_ TRCM_a336_overvoltageError m336 : 18|1@1+ (1,0) [0|0] "" Vector__XXX
 SG_ TRCM_a337_overvoltageError m337 : 18|1@1+ (1,0) [0|0] "" Vector__XXX
 SG_ TRCM_a340_overvoltageError m340 : 18|1@1+ (1,0) [0|0] "" Vector__XXX
 SG_ TRCM_a341_overvoltageError m341 : 18|1@1+ (1,0) [0|0] "" Vector__XXX
 SG_ TRCM_a342_overvoltageError m342 : 18|1@1+ (1,0) [0|0] "" Vector__XXX
 SG_ TRCM_a343_overvoltageError m343 : 18|1@1+ (1,0) [0|0] "" Vector__XXX
 SG_ TRCM_a344_overvoltageError m344 : 18|1@1+ (1,0) [0|0] "" Vector__XXX
 SG_ TRCM_a345_overvoltageError m345 : 18|1@1+ (1,0) [0|0] "" Vector__XXX
 SG_ TRCM_a346_overvoltageError m346 : 18|1@1+ (1,0) [0|0] "" Vector__XXX
 SG_ TRCM_a347_overvoltageError m347 : 18|1@1+ (1,0) [0|0] "" Vector__XXX
 SG_ TRCM_a348_overvoltageError m348 : 18|1@1+ (1,0) [0|0] "" Vector__XXX
 SG_ TRCM_a349_overvoltageError m349 : 18|1@1+ (1,0) [0|0] "" Vector__XXX
 SG_ TRCM_a350_overvoltageError m350 : 18|1@1+ (1,0) [0|0] "" Vector__XXX
 SG_ TRCM_a351_overvoltageError m351 : 18|1@1+ (1,0) [0|0] "" Vector__XXX
 SG_ TRCM_a352_overvoltageError m352 : 18|1@1+ (1,0) [0|0] "" Vector__XXX
 SG_ TRCM_a353_overvoltageError m353 : 18|1@1+ (1,0) [0|0] "" Vector__XXX
 SG_ TRCM_a354_overvoltageError m354 : 18|1@1+ (1,0) [0|0] "" Vector__XXX
 SG_ TRCM_a355_overvoltageError m355 : 18|1@1+ (1,0) [0|0] "" Vector__XXX
 SG_ TRCM_a389_sysBoostUnderVoltage m389 : 18|1@1+ (1,0) [0|0] "" Vector__XXX
 SG_ TRCM_a394_ERR_WID m394 : 18|1@1+ (1,0) [0|0] "" Vector__XXX
 SG_ TRCM_a396_mailboxIndex m396 : 18|4@1+ (1,0) [0|0] "" Vector__XXX
 SG_ TRCM_a544_diodeCheck2SwitchChargingTimeout m544 : 18|1@1+ (1,0) [0|0] "" Vector__XXX
 SG_ TRCM_a600_nvmOutOfWritesError m600 : 18|1@1+ (1,0) [0|0] "" Vector__XXX
 SG_ TRCM_a601_deploymentCounterHighCurrentReset m601 : 18|1@1+ (1,0) [0|0] "" Vector__XXX
 SG_ TRCM_a602_deploymentCounterHighCurrentReset m602 : 18|1@1+ (1,0) [0|0] "" Vector__XXX
 SG_ TRCM_a603_deploymentCounterHighCurrentReset m603 : 18|1@1+ (1,0) [0|0] "" Vector__XXX
 SG_ TRCM_a604_deploymentCounterHighCurrentReset m604 : 18|1@1+ (1,0) [0|0] "" Vector__XXX
 SG_ TRCM_a605_deploymentCounterHighCurrentReset m605 : 18|1@1+ (1,0) [0|0] "" Vector__XXX
 SG_ TRCM_a606_deploymentCounterHighCurrentReset m606 : 18|1@1+ (1,0) [0|0] "" Vector__XXX
 SG_ TRCM_a607_deploymentCounterHighCurrentReset m607 : 18|1@1+ (1,0) [0|0] "" Vector__XXX
 SG_ TRCM_a608_deploymentCounterHighCurrentReset m608 : 18|1@1+ (1,0) [0|0] "" Vector__XXX
 SG_ TRCM_a609_deploymentCounterHighCurrentReset m609 : 18|1@1+ (1,0) [0|0] "" Vector__XXX
 SG_ TRCM_a610_deploymentCounterHighCurrentReset m610 : 18|1@1+ (1,0) [0|0] "" Vector__XXX
 SG_ TRCM_a611_deploymentCounterHighCurrentReset m611 : 18|1@1+ (1,0) [0|0] "" Vector__XXX
 SG_ TRCM_a612_deploymentCounterHighCurrentReset m612 : 18|1@1+ (1,0) [0|0] "" Vector__XXX
 SG_ TRCM_a613_deploymentCounterHighCurrentReset m613 : 18|1@1+ (1,0) [0|0] "" Vector__XXX
 SG_ TRCM_a614_deploymentCounterHighCurrentReset m614 : 18|1@1+ (1,0) [0|0] "" Vector__XXX
 SG_ TRCM_a615_deploymentCounterHighCurrentReset m615 : 18|1@1+ (1,0) [0|0] "" Vector__XXX
 SG_ TRCM_a616_deploymentCounterHighCurrentReset m616 : 18|1@1+ (1,0) [0|0] "" Vector__XXX
 SG_ TRCM_a617_deploymentCounterHighCurrentReset m617 : 18|1@1+ (1,0) [0|0] "" Vector__XXX
 SG_ TRCM_a618_deploymentCounterHighCurrentReset m618 : 18|1@1+ (1,0) [0|0] "" Vector__XXX
 SG_ TRCM_a619_deploymentCounterHighCurrentReset m619 : 18|1@1+ (1,0) [0|0] "" Vector__XXX
 SG_ TRCM_a620_deploymentCounterHighCurrentReset m620 : 18|1@1+ (1,0) [0|0] "" Vector__XXX
 SG_ TRCM_a621_deploymentCounterHighCurrentReset m621 : 18|1@1+ (1,0) [0|0] "" Vector__XXX
 SG_ TRCM_a622_deploymentCounterHighCurrentReset m622 : 18|1@1+ (1,0) [0|0] "" Vector__XXX
 SG_ TRCM_a623_deploymentCounterHighCurrentReset m623 : 18|1@1+ (1,0) [0|0] "" Vector__XXX
 SG_ TRCM_a624_deploymentCounterHighCurrentReset m624 : 18|1@1+ (1,0) [0|0] "" Vector__XXX
 SG_ TRCM_a625_deploymentCounterHighCurrentReset m625 : 18|1@1+ (1,0) [0|0] "" Vector__XXX
 SG_ TRCM_a626_deploymentCounterHighCurrentReset m626 : 18|1@1+ (1,0) [0|0] "" Vector__XXX
 SG_ TRCM_a627_deploymentCounterHighCurrentReset m627 : 18|1@1+ (1,0) [0|0] "" Vector__XXX
 SG_ TRCM_a628_deploymentCounterHighCurrentReset m628 : 18|1@1+ (1,0) [0|0] "" Vector__XXX
 SG_ TRCM_a629_deploymentCounterHighCurrentReset m629 : 18|1@1+ (1,0) [0|0] "" Vector__XXX
 SG_ TRCM_a630_deploymentCounterHighCurrentReset m630 : 18|1@1+ (1,0) [0|0] "" Vector__XXX
 SG_ TRCM_a631_deploymentCounterHighCurrentReset m631 : 18|1@1+ (1,0) [0|0] "" Vector__XXX
 SG_ TRCM_a632_deploymentCounterHighCurrentReset m632 : 18|1@1+ (1,0) [0|0] "" Vector__XXX
 SG_ TRCM_a643_failureSource m643 : 18|3@1+ (1,0) [0|0] "" Vector__XXX
 SG_ TRCM_a644_oscillatorError m644 : 18|1@1+ (1,0) [0|0] "" Vector__XXX
 SG_ TRCM_a020_REG_FLIP_NO_ERR m20 : 19|1@1+ (1,0) [0|0] "" Vector__XXX
 SG_ TRCM_a021_Task10msLate m21 : 19|1@1+ (1,0) [0|0] "" Vector__XXX
 SG_ TRCM_a023_DDSOK_X m23 : 19|1@1+ (1,0) [0|0] "" Vector__XXX
 SG_ TRCM_a024_XL_REF_OK_CHZ m24 : 19|1@1+ (1,0) [0|0] "" Vector__XXX
 SG_ TRCM_a037_nearDeployRight m37 : 19|1@1+ (1,0) [0|0] "" Vector__XXX
 SG_ TRCM_a038_driverOverTemperature m38 : 19|1@1+ (1,0) [0|0] "" Vector__XXX
 SG_ TRCM_a039_driverOverTemperature m39 : 19|1@1+ (1,0) [0|0] "" Vector__XXX
 SG_ TRCM_a040_airbagAsicsDiagnosticState m40 : 19|6@1+ (1,0) [0|0] "" Vector__XXX
 SG_ TRCM_a051_sensorsInitializing m51 : 19|1@1+ (1,0) [0|0] "" Vector__XXX
 SG_ TRCM_a070_S_OK_AY m70 : 19|1@1+ (1,0) [0|0] "" Vector__XXX
 SG_ TRCM_a082_RIPC_remoteMux m82 : 19|1@1+ (1,0) [0|0] "" Vector__XXX
 SG_ TRCM_a083_LIPC_HSDFaults m83 : 19|1@1+ (1,0) [0|0] "" Vector__XXX
 SG_ TRCM_a086_VEH_12VBatteryStatus m86 : 19|1@1+ (1,0) [0|0] "" Vector__XXX
 SG_ TRCM_a087_VEH_status m87 : 19|1@1+ (1,0) [0|0] "" Vector__XXX
 SG_ TRCM_a088_VEH_status m88 : 19|1@1+ (1,0) [0|0] "" Vector__XXX
 SG_ TRCM_a089_BDY_party1 m89 : 19|1@1+ (1,0) [0|0] "" Vector__XXX
 SG_ TRCM_a090_CH_eacMonitor m90 : 19|1@1+ (1,0) [0|0] "" Vector__XXX
 SG_ TRCM_a092_VEH_vehNm m92 : 19|1@1+ (1,0) [0|0] "" Vector__XXX
 SG_ TRCM_a093_VEH_vehNm m93 : 19|1@1+ (1,0) [0|0] "" Vector__XXX
 SG_ TRCM_a098_VEH_thermalControl m98 : 19|1@1+ (1,0) [0|0] "" Vector__XXX
 SG_ TRCM_a100_CH m100 : 19|1@1+ (1,0) [0|0] "" Vector__XXX
 SG_ TRCM_a101_VEH_locState m101 : 19|1@1+ (1,0) [0|0] "" Vector__XXX
 SG_ TRCM_a102_VEH_rods m102 : 19|1@1+ (1,0) [0|0] "" Vector__XXX
 SG_ TRCM_a103_PT_ptNm m103 : 19|1@1+ (1,0) [0|0] "" Vector__XXX
 SG_ TRCM_a104_BDY_bodyControls3 m104 : 19|1@1+ (1,0) [0|0] "" Vector__XXX
 SG_ TRCM_a106_CH_dcdcRailStatus m106 : 19|1@1+ (1,0) [0|0] "" Vector__XXX
 SG_ TRCM_a107_VEH_thermalStatus m107 : 19|1@1+ (1,0) [0|0] "" Vector__XXX
 SG_ TRCM_a108_VEH_torque m108 : 19|1@1+ (1,0) [0|0] "" Vector__XXX
 SG_ TRCM_a109_PARTY_collision m109 : 19|1@1+ (1,0) [0|0] "" Vector__XXX
 SG_ TRCM_a110_VEH_updateStatus m110 : 19|1@1+ (1,0) [0|0] "" Vector__XXX
 SG_ TRCM_a111_RIPC_LVPowerState m111 : 19|1@1+ (1,0) [0|0] "" Vector__XXX
 SG_ TRCM_a112_LIPC_LVPowerState m112 : 19|1@1+ (1,0) [0|0] "" Vector__XXX
 SG_ TRCM_a113_VEH_vehicleControl m113 : 19|1@1+ (1,0) [0|0] "" Vector__XXX
 SG_ TRCM_a114_CH_wheelSpeeds m114 : 19|1@1+ (1,0) [0|0] "" Vector__XXX
 SG_ TRCM_a115_VEH_requests m115 : 19|1@1+ (1,0) [0|0] "" Vector__XXX
 SG_ TRCM_a116_VEH_hvacStatus m116 : 19|1@1+ (1,0) [0|0] "" Vector__XXX
 SG_ TRCM_a117_PARTY_epbmStatus m117 : 19|1@1+ (1,0) [0|0] "" Vector__XXX
 SG_ TRCM_a118_VEH_status m118 : 19|1@1+ (1,0) [0|0] "" Vector__XXX
 SG_ TRCM_a119_PARTY_rightStalk m119 : 19|1@1+ (1,0) [0|0] "" Vector__XXX
 SG_ TRCM_a120_PARTY_systemStatus m120 : 19|1@1+ (1,0) [0|0] "" Vector__XXX
 SG_ TRCM_a135_S_OK_AY m135 : 19|1@1+ (1,0) [0|0] "" Vector__XXX
 SG_ TRCM_a145_overTemperature m145 : 19|1@1+ (1,0) [0|0] "" Vector__XXX
 SG_ TRCM_a150_overTemperature m150 : 19|1@1+ (1,0) [0|0] "" Vector__XXX
 SG_ TRCM_a155_overTemperature m155 : 19|1@1+ (1,0) [0|0] "" Vector__XXX
 SG_ TRCM_a160_overTemperature m160 : 19|1@1+ (1,0) [0|0] "" Vector__XXX
 SG_ TRCM_a165_overTemperature m165 : 19|1@1+ (1,0) [0|0] "" Vector__XXX
 SG_ TRCM_a170_overTemperature m170 : 19|1@1+ (1,0) [0|0] "" Vector__XXX
 SG_ TRCM_a175_overTemperature m175 : 19|1@1+ (1,0) [0|0] "" Vector__XXX
 SG_ TRCM_a200_overTemperature m200 : 19|1@1+ (1,0) [0|0] "" Vector__XXX
 SG_ TRCM_a205_overTemperature m205 : 19|1@1+ (1,0) [0|0] "" Vector__XXX
 SG_ TRCM_a272_REG_FLIP_NO_ERR m272 : 19|1@1+ (1,0) [0|0] "" Vector__XXX
 SG_ TRCM_a273_DDSOK_X m273 : 19|1@1+ (1,0) [0|0] "" Vector__XXX
 SG_ TRCM_a274_DDSOK_Z m274 : 19|1@1+ (1,0) [0|0] "" Vector__XXX
 SG_ TRCM_a275_XL_REF_OK_CHZ m275 : 19|1@1+ (1,0) [0|0] "" Vector__XXX
 SG_ TRCM_a389_sysBoostOverVoltage m389 : 19|1@1+ (1,0) [0|0] "" Vector__XXX
 SG_ TRCM_a390_fllLoopClosedBit m390 : 19|1@1+ (1,0) [0|0] "" Vector__XXX
 SG_ TRCM_a391_fllLoopClosedBit m391 : 19|1@1+ (1,0) [0|0] "" Vector__XXX
 SG_ TRCM_a392_fllLoopClosedBit m392 : 19|1@1+ (1,0) [0|0] "" Vector__XXX
 SG_ TRCM_a394_ERBST_DLOSS m394 : 19|1@1+ (1,0) [0|0] "" Vector__XXX
 SG_ TRCM_a544_diodeCheck2ChargeSwitchChargingTimeout m544 : 19|1@1+ (1,0) [0|0] "" Vector__XXX
 SG_ TRCM_a600_bistsNotCompleted m600 : 19|1@1+ (1,0) [0|0] "" Vector__XXX
 SG_ TRCM_a601_deploymentCounterLowCurrentReset m601 : 19|1@1+ (1,0) [0|0] "" Vector__XXX
 SG_ TRCM_a602_deploymentCounterLowCurrentReset m602 : 19|1@1+ (1,0) [0|0] "" Vector__XXX
 SG_ TRCM_a603_deploymentCounterLowCurrentReset m603 : 19|1@1+ (1,0) [0|0] "" Vector__XXX
 SG_ TRCM_a604_deploymentCounterLowCurrentReset m604 : 19|1@1+ (1,0) [0|0] "" Vector__XXX
 SG_ TRCM_a605_deploymentCounterLowCurrentReset m605 : 19|1@1+ (1,0) [0|0] "" Vector__XXX
 SG_ TRCM_a606_deploymentCounterLowCurrentReset m606 : 19|1@1+ (1,0) [0|0] "" Vector__XXX
 SG_ TRCM_a607_deploymentCounterLowCurrentReset m607 : 19|1@1+ (1,0) [0|0] "" Vector__XXX
 SG_ TRCM_a608_deploymentCounterLowCurrentReset m608 : 19|1@1+ (1,0) [0|0] "" Vector__XXX
 SG_ TRCM_a609_deploymentCounterLowCurrentReset m609 : 19|1@1+ (1,0) [0|0] "" Vector__XXX
 SG_ TRCM_a610_deploymentCounterLowCurrentReset m610 : 19|1@1+ (1,0) [0|0] "" Vector__XXX
 SG_ TRCM_a611_deploymentCounterLowCurrentReset m611 : 19|1@1+ (1,0) [0|0] "" Vector__XXX
 SG_ TRCM_a612_deploymentCounterLowCurrentReset m612 : 19|1@1+ (1,0) [0|0] "" Vector__XXX
 SG_ TRCM_a613_deploymentCounterLowCurrentReset m613 : 19|1@1+ (1,0) [0|0] "" Vector__XXX
 SG_ TRCM_a614_deploymentCounterLowCurrentReset m614 : 19|1@1+ (1,0) [0|0] "" Vector__XXX
 SG_ TRCM_a615_deploymentCounterLowCurrentReset m615 : 19|1@1+ (1,0) [0|0] "" Vector__XXX
 SG_ TRCM_a616_deploymentCounterLowCurrentReset m616 : 19|1@1+ (1,0) [0|0] "" Vector__XXX
 SG_ TRCM_a617_deploymentCounterLowCurrentReset m617 : 19|1@1+ (1,0) [0|0] "" Vector__XXX
 SG_ TRCM_a618_deploymentCounterLowCurrentReset m618 : 19|1@1+ (1,0) [0|0] "" Vector__XXX
 SG_ TRCM_a619_deploymentCounterLowCurrentReset m619 : 19|1@1+ (1,0) [0|0] "" Vector__XXX
 SG_ TRCM_a620_deploymentCounterLowCurrentReset m620 : 19|1@1+ (1,0) [0|0] "" Vector__XXX
 SG_ TRCM_a621_deploymentCounterLowCurrentReset m621 : 19|1@1+ (1,0) [0|0] "" Vector__XXX
 SG_ TRCM_a622_deploymentCounterLowCurrentReset m622 : 19|1@1+ (1,0) [0|0] "" Vector__XXX
 SG_ TRCM_a623_deploymentCounterLowCurrentReset m623 : 19|1@1+ (1,0) [0|0] "" Vector__XXX
 SG_ TRCM_a624_deploymentCounterLowCurrentReset m624 : 19|1@1+ (1,0) [0|0] "" Vector__XXX
 SG_ TRCM_a625_deploymentCounterLowCurrentReset m625 : 19|1@1+ (1,0) [0|0] "" Vector__XXX
 SG_ TRCM_a626_deploymentCounterLowCurrentReset m626 : 19|1@1+ (1,0) [0|0] "" Vector__XXX
 SG_ TRCM_a627_deploymentCounterLowCurrentReset m627 : 19|1@1+ (1,0) [0|0] "" Vector__XXX
 SG_ TRCM_a628_deploymentCounterLowCurrentReset m628 : 19|1@1+ (1,0) [0|0] "" Vector__XXX
 SG_ TRCM_a629_deploymentCounterLowCurrentReset m629 : 19|1@1+ (1,0) [0|0] "" Vector__XXX
 SG_ TRCM_a630_deploymentCounterLowCurrentReset m630 : 19|1@1+ (1,0) [0|0] "" Vector__XXX
 SG_ TRCM_a631_deploymentCounterLowCurrentReset m631 : 19|1@1+ (1,0) [0|0] "" Vector__XXX
 SG_ TRCM_a632_deploymentCounterLowCurrentReset m632 : 19|1@1+ (1,0) [0|0] "" Vector__XXX
 SG_ TRCM_a005_faults0 m5 : 20|12@1+ (1,0) [0|0] "" Vector__XXX
 SG_ TRCM_a006_fault m6 : 20|4@1+ (1,0) [0|0] "" Vector__XXX
 SG_ TRCM_a020_OSC_OK m20 : 20|1@1+ (1,0) [0|0] "" Vector__XXX
 SG_ TRCM_a021_Task10msStarved m21 : 20|1@1+ (1,0) [0|0] "" Vector__XXX
 SG_ TRCM_a023_Drive_Disp_OK_X m23 : 20|1@1+ (1,0) [0|0] "" Vector__XXX
 SG_ TRCM_a024_XL_REF_OK_CHY m24 : 20|1@1+ (1,0) [0|0] "" Vector__XXX
 SG_ TRCM_a036_collisionSeverity m36 : 20|2@1+ (1,0) [0|0] "" Vector__XXX
 SG_ TRCM_a037_nearDeployRoll m37 : 20|1@1+ (1,0) [0|0] "" Vector__XXX
 SG_ TRCM_a049_nvmArmState m49 : 20|1@1+ (1,0) [0|0] "" Vector__XXX
 SG_ TRCM_a069_warmResetCause m69 : 20|4@1+ (1,0) [0|0] "" Vector__XXX
 SG_ TRCM_a070_S_OK_RX m70 : 20|1@1+ (1,0) [0|0] "" Vector__XXX
 SG_ TRCM_a086_VEH_LVPowerState m86 : 20|1@1+ (1,0) [0|0] "" Vector__XXX
 SG_ TRCM_a087_PARTY_torque m87 : 20|1@1+ (1,0) [0|0] "" Vector__XXX
 SG_ TRCM_a088_PARTY_torque m88 : 20|1@1+ (1,0) [0|0] "" Vector__XXX
 SG_ TRCM_a089_BDY_status m89 : 20|1@1+ (1,0) [0|0] "" Vector__XXX
 SG_ TRCM_a098_VEH_temperature m98 : 20|1@1+ (1,0) [0|0] "" Vector__XXX
 SG_ TRCM_a100_OBD m100 : 20|1@1+ (1,0) [0|0] "" Vector__XXX
 SG_ TRCM_a101_BDY_locState m101 : 20|1@1+ (1,0) [0|0] "" Vector__XXX
 SG_ TRCM_a103_PT_status m103 : 20|1@1+ (1,0) [0|0] "" Vector__XXX
 SG_ TRCM_a104_VEH_thermalStatus m104 : 20|1@1+ (1,0) [0|0] "" Vector__XXX
 SG_ TRCM_a106_CH_alertMatrix m106 : 20|1@1+ (1,0) [0|0] "" Vector__XXX
 SG_ TRCM_a107_VEH_bmbMinMax m107 : 20|1@1+ (1,0) [0|0] "" Vector__XXX
 SG_ TRCM_a108_VEH_status m108 : 20|1@1+ (1,0) [0|0] "" Vector__XXX
 SG_ TRCM_a109_VEH_status m109 : 20|1@1+ (1,0) [0|0] "" Vector__XXX
 SG_ TRCM_a110_VEH_vehNm m110 : 20|1@1+ (1,0) [0|0] "" Vector__XXX
 SG_ TRCM_a111_RIPC_epbPrivateState m111 : 20|1@1+ (1,0) [0|0] "" Vector__XXX
 SG_ TRCM_a112_LIPC_epbPrivateState m112 : 20|1@1+ (1,0) [0|0] "" Vector__XXX
 SG_ TRCM_a113_VEH_vehicleControl2 m113 : 20|1@1+ (1,0) [0|0] "" Vector__XXX
 SG_ TRCM_a114_PARTY_party3 m114 : 20|1@1+ (1,0) [0|0] "" Vector__XXX
 SG_ TRCM_a115_VEH_requests2 m115 : 20|1@1+ (1,0) [0|0] "" Vector__XXX
 SG_ TRCM_a116_VEH_LVPowerState m116 : 20|1@1+ (1,0) [0|0] "" Vector__XXX
 SG_ TRCM_a117_VEH_vehNm m117 : 20|1@1+ (1,0) [0|0] "" Vector__XXX
 SG_ TRCM_a118_VEH_okToUseHighPwr m118 : 20|1@1+ (1,0) [0|0] "" Vector__XXX
 SG_ TRCM_a119_CH_steerAngle m119 : 20|1@1+ (1,0) [0|0] "" Vector__XXX
 SG_ TRCM_a120_PARTY_torque m120 : 20|1@1+ (1,0) [0|0] "" Vector__XXX
 SG_ TRCM_a135_S_OK_AX m135 : 20|1@1+ (1,0) [0|0] "" Vector__XXX
 SG_ TRCM_a145_currentHigh m145 : 20|1@1+ (1,0) [0|0] "" Vector__XXX
 SG_ TRCM_a150_currentHigh m150 : 20|1@1+ (1,0) [0|0] "" Vector__XXX
 SG_ TRCM_a155_currentHigh m155 : 20|1@1+ (1,0) [0|0] "" Vector__XXX
 SG_ TRCM_a160_currentHigh m160 : 20|1@1+ (1,0) [0|0] "" Vector__XXX
 SG_ TRCM_a165_currentHigh m165 : 20|1@1+ (1,0) [0|0] "" Vector__XXX
 SG_ TRCM_a170_currentHigh m170 : 20|1@1+ (1,0) [0|0] "" Vector__XXX
 SG_ TRCM_a175_currentHigh m175 : 20|1@1+ (1,0) [0|0] "" Vector__XXX
 SG_ TRCM_a200_currentHigh m200 : 20|1@1+ (1,0) [0|0] "" Vector__XXX
 SG_ TRCM_a205_currentHigh m205 : 20|1@1+ (1,0) [0|0] "" Vector__XXX
 SG_ TRCM_a272_OSC_OK m272 : 20|1@1+ (1,0) [0|0] "" Vector__XXX
 SG_ TRCM_a273_Drive_Disp_OK_X m273 : 20|1@1+ (1,0) [0|0] "" Vector__XXX
 SG_ TRCM_a274_Drive_Disp_OK_Z m274 : 20|1@1+ (1,0) [0|0] "" Vector__XXX
 SG_ TRCM_a275_XL_REF_OK_CHY m275 : 20|1@1+ (1,0) [0|0] "" Vector__XXX
 SG_ TRCM_a389_erBoostUnderVoltage m389 : 20|1@1+ (1,0) [0|0] "" Vector__XXX
 SG_ TRCM_a390_fllEnabledBit m390 : 20|1@1+ (1,0) [0|0] "" Vector__XXX
 SG_ TRCM_a391_fllEnabledBit m391 : 20|1@1+ (1,0) [0|0] "" Vector__XXX
 SG_ TRCM_a392_fllEnabledBit m392 : 20|1@1+ (1,0) [0|0] "" Vector__XXX
 SG_ TRCM_a394_SYSBST_DLOSS m394 : 20|1@1+ (1,0) [0|0] "" Vector__XXX
 SG_ TRCM_a544_diodeCheck2Failed m544 : 20|1@1+ (1,0) [0|0] "" Vector__XXX
 SG_ TRCM_a600_safetyEchoFailed m600 : 20|1@1+ (1,0) [0|0] "" Vector__XXX
 SG_ TRCM_a601_deploymentCounterHighCurrentVal m601 : 20|1@1+ (1,0) [0|0] "" Vector__XXX
 SG_ TRCM_a602_deploymentCounterHighCurrentVal m602 : 20|1@1+ (1,0) [0|0] "" Vector__XXX
 SG_ TRCM_a603_deploymentCounterHighCurrentVal m603 : 20|1@1+ (1,0) [0|0] "" Vector__XXX
 SG_ TRCM_a604_deploymentCounterHighCurrentVal m604 : 20|1@1+ (1,0) [0|0] "" Vector__XXX
 SG_ TRCM_a605_deploymentCounterHighCurrentVal m605 : 20|1@1+ (1,0) [0|0] "" Vector__XXX
 SG_ TRCM_a606_deploymentCounterHighCurrentVal m606 : 20|1@1+ (1,0) [0|0] "" Vector__XXX
 SG_ TRCM_a607_deploymentCounterHighCurrentVal m607 : 20|1@1+ (1,0) [0|0] "" Vector__XXX
 SG_ TRCM_a608_deploymentCounterHighCurrentVal m608 : 20|1@1+ (1,0) [0|0] "" Vector__XXX
 SG_ TRCM_a609_deploymentCounterHighCurrentVal m609 : 20|1@1+ (1,0) [0|0] "" Vector__XXX
 SG_ TRCM_a610_deploymentCounterHighCurrentVal m610 : 20|1@1+ (1,0) [0|0] "" Vector__XXX
 SG_ TRCM_a611_deploymentCounterHighCurrentVal m611 : 20|1@1+ (1,0) [0|0] "" Vector__XXX
 SG_ TRCM_a612_deploymentCounterHighCurrentVal m612 : 20|1@1+ (1,0) [0|0] "" Vector__XXX
 SG_ TRCM_a613_deploymentCounterHighCurrentVal m613 : 20|1@1+ (1,0) [0|0] "" Vector__XXX
 SG_ TRCM_a614_deploymentCounterHighCurrentVal m614 : 20|1@1+ (1,0) [0|0] "" Vector__XXX
 SG_ TRCM_a615_deploymentCounterHighCurrentVal m615 : 20|1@1+ (1,0) [0|0] "" Vector__XXX
 SG_ TRCM_a616_deploymentCounterHighCurrentVal m616 : 20|1@1+ (1,0) [0|0] "" Vector__XXX
 SG_ TRCM_a617_deploymentCounterHighCurrentVal m617 : 20|1@1+ (1,0) [0|0] "" Vector__XXX
 SG_ TRCM_a618_deploymentCounterHighCurrentVal m618 : 20|1@1+ (1,0) [0|0] "" Vector__XXX
 SG_ TRCM_a619_deploymentCounterHighCurrentVal m619 : 20|1@1+ (1,0) [0|0] "" Vector__XXX
 SG_ TRCM_a620_deploymentCounterHighCurrentVal m620 : 20|1@1+ (1,0) [0|0] "" Vector__XXX
 SG_ TRCM_a621_deploymentCounterHighCurrentVal m621 : 20|1@1+ (1,0) [0|0] "" Vector__XXX
 SG_ TRCM_a622_deploymentCounterHighCurrentVal m622 : 20|1@1+ (1,0) [0|0] "" Vector__XXX
 SG_ TRCM_a623_deploymentCounterHighCurrentVal m623 : 20|1@1+ (1,0) [0|0] "" Vector__XXX
 SG_ TRCM_a624_deploymentCounterHighCurrentVal m624 : 20|1@1+ (1,0) [0|0] "" Vector__XXX
 SG_ TRCM_a625_deploymentCounterHighCurrentVal m625 : 20|1@1+ (1,0) [0|0] "" Vector__XXX
 SG_ TRCM_a626_deploymentCounterHighCurrentVal m626 : 20|1@1+ (1,0) [0|0] "" Vector__XXX
 SG_ TRCM_a627_deploymentCounterHighCurrentVal m627 : 20|1@1+ (1,0) [0|0] "" Vector__XXX
 SG_ TRCM_a628_deploymentCounterHighCurrentVal m628 : 20|1@1+ (1,0) [0|0] "" Vector__XXX
 SG_ TRCM_a629_deploymentCounterHighCurrentVal m629 : 20|1@1+ (1,0) [0|0] "" Vector__XXX
 SG_ TRCM_a630_deploymentCounterHighCurrentVal m630 : 20|1@1+ (1,0) [0|0] "" Vector__XXX
 SG_ TRCM_a631_deploymentCounterHighCurrentVal m631 : 20|1@1+ (1,0) [0|0] "" Vector__XXX
 SG_ TRCM_a632_deploymentCounterHighCurrentVal m632 : 20|1@1+ (1,0) [0|0] "" Vector__XXX
 SG_ TRCM_a020_AVDD_HEADROOM_OK m20 : 21|1@1+ (1,0) [0|0] "" Vector__XXX
 SG_ TRCM_a021_Task10msMissed m21 : 21|1@1+ (1,0) [0|0] "" Vector__XXX
 SG_ TRCM_a023_Drive_Control_OK_X m23 : 21|1@1+ (1,0) [0|0] "" Vector__XXX
 SG_ TRCM_a024_SelfTestAuto_TC_OK_CHZ m24 : 21|1@1+ (1,0) [0|0] "" Vector__XXX
 SG_ TRCM_a086_VEH_lightStatus m86 : 21|1@1+ (1,0) [0|0] "" Vector__XXX
 SG_ TRCM_a087_PARTY_status m87 : 21|1@1+ (1,0) [0|0] "" Vector__XXX
 SG_ TRCM_a088_PARTY_status m88 : 21|1@1+ (1,0) [0|0] "" Vector__XXX
 SG_ TRCM_a089_CH_status m89 : 21|1@1+ (1,0) [0|0] "" Vector__XXX
 SG_ TRCM_a098_VEH_torque m98 : 21|1@1+ (1,0) [0|0] "" Vector__XXX
 SG_ TRCM_a103_VEH_evseStatus m103 : 21|1@1+ (1,0) [0|0] "" Vector__XXX
 SG_ TRCM_a104_CH_control m104 : 21|1@1+ (1,0) [0|0] "" Vector__XXX
 SG_ TRCM_a107_VEH_powerAvailable m107 : 21|1@1+ (1,0) [0|0] "" Vector__XXX
 SG_ TRCM_a108_PARTY_torque m108 : 21|1@1+ (1,0) [0|0] "" Vector__XXX
 SG_ TRCM_a109_VEH_imuOffsets m109 : 21|1@1+ (1,0) [0|0] "" Vector__XXX
 SG_ TRCM_a110_VEH_mismatchFault m110 : 21|1@1+ (1,0) [0|0] "" Vector__XXX
 SG_ TRCM_a111_RIPC_railStatus m111 : 21|1@1+ (1,0) [0|0] "" Vector__XXX
 SG_ TRCM_a112_LIPC_railStatus m112 : 21|1@1+ (1,0) [0|0] "" Vector__XXX
 SG_ TRCM_a113_VEH_peripheralPowerRequests m113 : 21|1@1+ (1,0) [0|0] "" Vector__XXX
 SG_ TRCM_a114_VEH_party3 m114 : 21|1@1+ (1,0) [0|0] "" Vector__XXX
 SG_ TRCM_a115_REM_authentication m115 : 21|1@1+ (1,0) [0|0] "" Vector__XXX
 SG_ TRCM_a116_VEH_lightStatus m116 : 21|1@1+ (1,0) [0|0] "" Vector__XXX
 SG_ TRCM_a117_VEH_hvacBlowerFdb m117 : 21|1@1+ (1,0) [0|0] "" Vector__XXX
 SG_ TRCM_a118_VEH_LVPowerState m118 : 21|1@1+ (1,0) [0|0] "" Vector__XXX
 SG_ TRCM_a119_PARTY_steerAngle m119 : 21|1@1+ (1,0) [0|0] "" Vector__XXX
 SG_ TRCM_a120_VEH_torque m120 : 21|1@1+ (1,0) [0|0] "" Vector__XXX
 SG_ TRCM_a135_S_OK_RZ m135 : 21|1@1+ (1,0) [0|0] "" Vector__XXX
 SG_ TRCM_a145_channelOff m145 : 21|1@1+ (1,0) [0|0] "" Vector__XXX
 SG_ TRCM_a150_channelOff m150 : 21|1@1+ (1,0) [0|0] "" Vector__XXX
 SG_ TRCM_a155_channelOff m155 : 21|1@1+ (1,0) [0|0] "" Vector__XXX
 SG_ TRCM_a160_channelOff m160 : 21|1@1+ (1,0) [0|0] "" Vector__XXX
 SG_ TRCM_a165_channelOff m165 : 21|1@1+ (1,0) [0|0] "" Vector__XXX
 SG_ TRCM_a170_channelOff m170 : 21|1@1+ (1,0) [0|0] "" Vector__XXX
 SG_ TRCM_a175_channelOff m175 : 21|1@1+ (1,0) [0|0] "" Vector__XXX
 SG_ TRCM_a200_channelOff m200 : 21|1@1+ (1,0) [0|0] "" Vector__XXX
 SG_ TRCM_a205_channelOff m205 : 21|1@1+ (1,0) [0|0] "" Vector__XXX
 SG_ TRCM_a272_AVDD_HEADROOM_OK m272 : 21|1@1+ (1,0) [0|0] "" Vector__XXX
 SG_ TRCM_a273_Drive_Control_OK_X m273 : 21|1@1+ (1,0) [0|0] "" Vector__XXX
 SG_ TRCM_a274_Drive_Control_OK_Z m274 : 21|1@1+ (1,0) [0|0] "" Vector__XXX
 SG_ TRCM_a275_XL_REF_OK_CHX m275 : 21|1@1+ (1,0) [0|0] "" Vector__XXX
 SG_ TRCM_a389_erBoostOverVoltage m389 : 21|1@1+ (1,0) [0|0] "" Vector__XXX
 SG_ TRCM_a390_operatingState m390 : 21|3@1+ (1,0) [0|0] "" Vector__XXX
 SG_ TRCM_a391_operatingState m391 : 21|3@1+ (1,0) [0|0] "" Vector__XXX
 SG_ TRCM_a392_operatingState m392 : 21|3@1+ (1,0) [0|0] "" Vector__XXX
 SG_ TRCM_a394_ADC_DEP_BUSY m394 : 21|1@1+ (1,0) [0|0] "" Vector__XXX
 SG_ TRCM_a544_capacitanceCheckRoutineFailed m544 : 21|1@1+ (1,0) [0|0] "" Vector__XXX
 SG_ TRCM_a600_mbistFailed m600 : 21|1@1+ (1,0) [0|0] "" Vector__XXX
 SG_ TRCM_a601_deploymentCounterLowCurrentVal m601 : 21|1@1+ (1,0) [0|0] "" Vector__XXX
 SG_ TRCM_a602_deploymentCounterLowCurrentVal m602 : 21|1@1+ (1,0) [0|0] "" Vector__XXX
 SG_ TRCM_a603_deploymentCounterLowCurrentVal m603 : 21|1@1+ (1,0) [0|0] "" Vector__XXX
 SG_ TRCM_a604_deploymentCounterLowCurrentVal m604 : 21|1@1+ (1,0) [0|0] "" Vector__XXX
 SG_ TRCM_a605_deploymentCounterLowCurrentVal m605 : 21|1@1+ (1,0) [0|0] "" Vector__XXX
 SG_ TRCM_a606_deploymentCounterLowCurrentVal m606 : 21|1@1+ (1,0) [0|0] "" Vector__XXX
 SG_ TRCM_a607_deploymentCounterLowCurrentVal m607 : 21|1@1+ (1,0) [0|0] "" Vector__XXX
 SG_ TRCM_a608_deploymentCounterLowCurrentVal m608 : 21|1@1+ (1,0) [0|0] "" Vector__XXX
 SG_ TRCM_a609_deploymentCounterLowCurrentVal m609 : 21|1@1+ (1,0) [0|0] "" Vector__XXX
 SG_ TRCM_a610_deploymentCounterLowCurrentVal m610 : 21|1@1+ (1,0) [0|0] "" Vector__XXX
 SG_ TRCM_a611_deploymentCounterLowCurrentVal m611 : 21|1@1+ (1,0) [0|0] "" Vector__XXX
 SG_ TRCM_a612_deploymentCounterLowCurrentVal m612 : 21|1@1+ (1,0) [0|0] "" Vector__XXX
 SG_ TRCM_a613_deploymentCounterLowCurrentVal m613 : 21|1@1+ (1,0) [0|0] "" Vector__XXX
 SG_ TRCM_a614_deploymentCounterLowCurrentVal m614 : 21|1@1+ (1,0) [0|0] "" Vector__XXX
 SG_ TRCM_a615_deploymentCounterLowCurrentVal m615 : 21|1@1+ (1,0) [0|0] "" Vector__XXX
 SG_ TRCM_a616_deploymentCounterLowCurrentVal m616 : 21|1@1+ (1,0) [0|0] "" Vector__XXX
 SG_ TRCM_a617_deploymentCounterLowCurrentVal m617 : 21|1@1+ (1,0) [0|0] "" Vector__XXX
 SG_ TRCM_a618_deploymentCounterLowCurrentVal m618 : 21|1@1+ (1,0) [0|0] "" Vector__XXX
 SG_ TRCM_a619_deploymentCounterLowCurrentVal m619 : 21|1@1+ (1,0) [0|0] "" Vector__XXX
 SG_ TRCM_a620_deploymentCounterLowCurrentVal m620 : 21|1@1+ (1,0) [0|0] "" Vector__XXX
 SG_ TRCM_a621_deploymentCounterLowCurrentVal m621 : 21|1@1+ (1,0) [0|0] "" Vector__XXX
 SG_ TRCM_a622_deploymentCounterLowCurrentVal m622 : 21|1@1+ (1,0) [0|0] "" Vector__XXX
 SG_ TRCM_a623_deploymentCounterLowCurrentVal m623 : 21|1@1+ (1,0) [0|0] "" Vector__XXX
 SG_ TRCM_a624_deploymentCounterLowCurrentVal m624 : 21|1@1+ (1,0) [0|0] "" Vector__XXX
 SG_ TRCM_a625_deploymentCounterLowCurrentVal m625 : 21|1@1+ (1,0) [0|0] "" Vector__XXX
 SG_ TRCM_a626_deploymentCounterLowCurrentVal m626 : 21|1@1+ (1,0) [0|0] "" Vector__XXX
 SG_ TRCM_a627_deploymentCounterLowCurrentVal m627 : 21|1@1+ (1,0) [0|0] "" Vector__XXX
 SG_ TRCM_a628_deploymentCounterLowCurrentVal m628 : 21|1@1+ (1,0) [0|0] "" Vector__XXX
 SG_ TRCM_a629_deploymentCounterLowCurrentVal m629 : 21|1@1+ (1,0) [0|0] "" Vector__XXX
 SG_ TRCM_a630_deploymentCounterLowCurrentVal m630 : 21|1@1+ (1,0) [0|0] "" Vector__XXX
 SG_ TRCM_a631_deploymentCounterLowCurrentVal m631 : 21|1@1+ (1,0) [0|0] "" Vector__XXX
 SG_ TRCM_a632_deploymentCounterLowCurrentVal m632 : 21|1@1+ (1,0) [0|0] "" Vector__XXX
 SG_ TRCM_a020_DGND_OK m20 : 22|1@1+ (1,0) [0|0] "" Vector__XXX
 SG_ TRCM_a021_Task100msLate m21 : 22|1@1+ (1,0) [0|0] "" Vector__XXX
 SG_ TRCM_a023_QCCtrlOk_X m23 : 22|1@1+ (1,0) [0|0] "" Vector__XXX
 SG_ TRCM_a024_SelfTestAuto_TC_OK_CHY m24 : 22|1@1+ (1,0) [0|0] "" Vector__XXX
 SG_ TRCM_a086_VEH_systemStatus m86 : 22|1@1+ (1,0) [0|0] "" Vector__XXX
 SG_ TRCM_a087_PARTY_temperature m87 : 22|1@1+ (1,0) [0|0] "" Vector__XXX
 SG_ TRCM_a088_PARTY_temperature m88 : 22|1@1+ (1,0) [0|0] "" Vector__XXX
 SG_ TRCM_a089_CH_party1 m89 : 22|1@1+ (1,0) [0|0] "" Vector__XXX
 SG_ TRCM_a098_PARTY_status m98 : 22|1@1+ (1,0) [0|0] "" Vector__XXX
 SG_ TRCM_a104_PARTY_control m104 : 22|1@1+ (1,0) [0|0] "" Vector__XXX
 SG_ TRCM_a107_PT_ptNm m107 : 22|1@1+ (1,0) [0|0] "" Vector__XXX
 SG_ TRCM_a108_PARTY_status m108 : 22|1@1+ (1,0) [0|0] "" Vector__XXX
 SG_ TRCM_a109_PARTY_inertial1 m109 : 22|1@1+ (1,0) [0|0] "" Vector__XXX
 SG_ TRCM_a110_VEH_vin m110 : 22|1@1+ (1,0) [0|0] "" Vector__XXX
 SG_ TRCM_a111_RIPC_remoteADC m111 : 22|1@1+ (1,0) [0|0] "" Vector__XXX
 SG_ TRCM_a112_LIPC_remoteADC m112 : 22|1@1+ (1,0) [0|0] "" Vector__XXX
 SG_ TRCM_a113_VEH_corianderVehicleControl m113 : 22|1@1+ (1,0) [0|0] "" Vector__XXX
 SG_ TRCM_a114_VEH_status m114 : 22|1@1+ (1,0) [0|0] "" Vector__XXX
 SG_ TRCM_a115_UI_corianderVehicleControl m115 : 22|1@1+ (1,0) [0|0] "" Vector__XXX
 SG_ TRCM_a116_VEH_seatStatus m116 : 22|1@1+ (1,0) [0|0] "" Vector__XXX
 SG_ TRCM_a117_VEH_LVPowerState m117 : 22|1@1+ (1,0) [0|0] "" Vector__XXX
 SG_ TRCM_a118_VEH_coolant m118 : 22|1@1+ (1,0) [0|0] "" Vector__XXX
 SG_ TRCM_a120_PARTY_locStatus m120 : 22|1@1+ (1,0) [0|0] "" Vector__XXX
 SG_ TRCM_a135_S_OK_RX m135 : 22|1@1+ (1,0) [0|0] "" Vector__XXX
 SG_ TRCM_a272_DGND_OK m272 : 22|1@1+ (1,0) [0|0] "" Vector__XXX
 SG_ TRCM_a273_QCCtrlOk_X m273 : 22|1@1+ (1,0) [0|0] "" Vector__XXX
 SG_ TRCM_a274_QCCtrlOk_Z m274 : 22|1@1+ (1,0) [0|0] "" Vector__XXX
 SG_ TRCM_a275_SelfTestAuto_TC_OK_CHZ m275 : 22|1@1+ (1,0) [0|0] "" Vector__XXX
 SG_ TRCM_a389_erBoostOverTemperature m389 : 22|1@1+ (1,0) [0|0] "" Vector__XXX
 SG_ TRCM_a394_ER_DIAG_RUNNING m394 : 22|1@1+ (1,0) [0|0] "" Vector__XXX
 SG_ TRCM_a544_capacitanceLow m544 : 22|1@1+ (1,0) [0|0] "" Vector__XXX
 SG_ TRCM_a600_lbistFailed m600 : 22|1@1+ (1,0) [0|0] "" Vector__XXX
 SG_ TRCM_a601_deploymentCounterHighCurrentCleanup m601 : 22|1@1+ (1,0) [0|0] "" Vector__XXX
 SG_ TRCM_a602_deploymentCounterHighCurrentCleanup m602 : 22|1@1+ (1,0) [0|0] "" Vector__XXX
 SG_ TRCM_a603_deploymentCounterHighCurrentCleanup m603 : 22|1@1+ (1,0) [0|0] "" Vector__XXX
 SG_ TRCM_a604_deploymentCounterHighCurrentCleanup m604 : 22|1@1+ (1,0) [0|0] "" Vector__XXX
 SG_ TRCM_a605_deploymentCounterHighCurrentCleanup m605 : 22|1@1+ (1,0) [0|0] "" Vector__XXX
 SG_ TRCM_a606_deploymentCounterHighCurrentCleanup m606 : 22|1@1+ (1,0) [0|0] "" Vector__XXX
 SG_ TRCM_a607_deploymentCounterHighCurrentCleanup m607 : 22|1@1+ (1,0) [0|0] "" Vector__XXX
 SG_ TRCM_a608_deploymentCounterHighCurrentCleanup m608 : 22|1@1+ (1,0) [0|0] "" Vector__XXX
 SG_ TRCM_a609_deploymentCounterHighCurrentCleanup m609 : 22|1@1+ (1,0) [0|0] "" Vector__XXX
 SG_ TRCM_a610_deploymentCounterHighCurrentCleanup m610 : 22|1@1+ (1,0) [0|0] "" Vector__XXX
 SG_ TRCM_a611_deploymentCounterHighCurrentCleanup m611 : 22|1@1+ (1,0) [0|0] "" Vector__XXX
 SG_ TRCM_a612_deploymentCounterHighCurrentCleanup m612 : 22|1@1+ (1,0) [0|0] "" Vector__XXX
 SG_ TRCM_a613_deploymentCounterHighCurrentCleanup m613 : 22|1@1+ (1,0) [0|0] "" Vector__XXX
 SG_ TRCM_a614_deploymentCounterHighCurrentCleanup m614 : 22|1@1+ (1,0) [0|0] "" Vector__XXX
 SG_ TRCM_a615_deploymentCounterHighCurrentCleanup m615 : 22|1@1+ (1,0) [0|0] "" Vector__XXX
 SG_ TRCM_a616_deploymentCounterHighCurrentCleanup m616 : 22|1@1+ (1,0) [0|0] "" Vector__XXX
 SG_ TRCM_a617_deploymentCounterHighCurrentCleanup m617 : 22|1@1+ (1,0) [0|0] "" Vector__XXX
 SG_ TRCM_a618_deploymentCounterHighCurrentCleanup m618 : 22|1@1+ (1,0) [0|0] "" Vector__XXX
 SG_ TRCM_a619_deploymentCounterHighCurrentCleanup m619 : 22|1@1+ (1,0) [0|0] "" Vector__XXX
 SG_ TRCM_a620_deploymentCounterHighCurrentCleanup m620 : 22|1@1+ (1,0) [0|0] "" Vector__XXX
 SG_ TRCM_a621_deploymentCounterHighCurrentCleanup m621 : 22|1@1+ (1,0) [0|0] "" Vector__XXX
 SG_ TRCM_a622_deploymentCounterHighCurrentCleanup m622 : 22|1@1+ (1,0) [0|0] "" Vector__XXX
 SG_ TRCM_a623_deploymentCounterHighCurrentCleanup m623 : 22|1@1+ (1,0) [0|0] "" Vector__XXX
 SG_ TRCM_a624_deploymentCounterHighCurrentCleanup m624 : 22|1@1+ (1,0) [0|0] "" Vector__XXX
 SG_ TRCM_a625_deploymentCounterHighCurrentCleanup m625 : 22|1@1+ (1,0) [0|0] "" Vector__XXX
 SG_ TRCM_a626_deploymentCounterHighCurrentCleanup m626 : 22|1@1+ (1,0) [0|0] "" Vector__XXX
 SG_ TRCM_a627_deploymentCounterHighCurrentCleanup m627 : 22|1@1+ (1,0) [0|0] "" Vector__XXX
 SG_ TRCM_a628_deploymentCounterHighCurrentCleanup m628 : 22|1@1+ (1,0) [0|0] "" Vector__XXX
 SG_ TRCM_a629_deploymentCounterHighCurrentCleanup m629 : 22|1@1+ (1,0) [0|0] "" Vector__XXX
 SG_ TRCM_a630_deploymentCounterHighCurrentCleanup m630 : 22|1@1+ (1,0) [0|0] "" Vector__XXX
 SG_ TRCM_a631_deploymentCounterHighCurrentCleanup m631 : 22|1@1+ (1,0) [0|0] "" Vector__XXX
 SG_ TRCM_a632_deploymentCounterHighCurrentCleanup m632 : 22|1@1+ (1,0) [0|0] "" Vector__XXX
 SG_ TRCM_a020_REG_CTRL_WR_OK_LATCH m20 : 23|1@1+ (1,0) [0|0] "" Vector__XXX
 SG_ TRCM_a021_Task100msStarved m21 : 23|1@1+ (1,0) [0|0] "" Vector__XXX
 SG_ TRCM_a023_ADC_Not_SAT_X m23 : 23|1@1+ (1,0) [0|0] "" Vector__XXX
 SG_ TRCM_a024_A2D_NSAT_OK_CHZ m24 : 23|1@1+ (1,0) [0|0] "" Vector__XXX
 SG_ TRCM_a086_VEH_thermalStatus m86 : 23|1@1+ (1,0) [0|0] "" Vector__XXX
 SG_ TRCM_a087_PARTY_thermalControl m87 : 23|1@1+ (1,0) [0|0] "" Vector__XXX
 SG_ TRCM_a088_PARTY_thermalControl m88 : 23|1@1+ (1,0) [0|0] "" Vector__XXX
 SG_ TRCM_a089_CH_party3 m89 : 23|1@1+ (1,0) [0|0] "" Vector__XXX
 SG_ TRCM_a098_PARTY_temperature m98 : 23|1@1+ (1,0) [0|0] "" Vector__XXX
 SG_ TRCM_a104_PARTY_bodyControls m104 : 23|1@1+ (1,0) [0|0] "" Vector__XXX
 SG_ TRCM_a107_PT_status m107 : 23|1@1+ (1,0) [0|0] "" Vector__XXX
 SG_ TRCM_a108_PARTY_temperature m108 : 23|1@1+ (1,0) [0|0] "" Vector__XXX
 SG_ TRCM_a109_BDY_imuOffsets m109 : 23|1@1+ (1,0) [0|0] "" Vector__XXX
 SG_ TRCM_a110_VEH_bmpDebug m110 : 23|1@1+ (1,0) [0|0] "" Vector__XXX
 SG_ TRCM_a111_RIPC_switchStatus m111 : 23|1@1+ (1,0) [0|0] "" Vector__XXX
 SG_ TRCM_a112_LIPC_switchStatus m112 : 23|1@1+ (1,0) [0|0] "" Vector__XXX
 SG_ TRCM_a113_VEH_solarData m113 : 23|1@1+ (1,0) [0|0] "" Vector__XXX
 SG_ TRCM_a114_PARTY_wheelRotation m114 : 23|1@1+ (1,0) [0|0] "" Vector__XXX
 SG_ TRCM_a115_CH_TPMSDisplay m115 : 23|1@1+ (1,0) [0|0] "" Vector__XXX
 SG_ TRCM_a116_VEH_thsStatus m116 : 23|1@1+ (1,0) [0|0] "" Vector__XXX
 SG_ TRCM_a117_VEH_restraintStatus m117 : 23|1@1+ (1,0) [0|0] "" Vector__XXX
 SG_ TRCM_a118_VEH_vehicleStatus m118 : 23|1@1+ (1,0) [0|0] "" Vector__XXX
 SG_ TRCM_a120_PARTY_speed m120 : 23|1@1+ (1,0) [0|0] "" Vector__XXX
 SG_ TRCM_a272_REG_CTRL_WR_OK_LATCH m272 : 23|1@1+ (1,0) [0|0] "" Vector__XXX
 SG_ TRCM_a273_ADC_Not_SAT_X m273 : 23|1@1+ (1,0) [0|0] "" Vector__XXX
 SG_ TRCM_a274_ADC_Not_SAT_Z m274 : 23|1@1+ (1,0) [0|0] "" Vector__XXX
 SG_ TRCM_a275_SelfTestAuto_TC_OK_CHY m275 : 23|1@1+ (1,0) [0|0] "" Vector__XXX
 SG_ TRCM_a389_erChargeSwitchOverTemperature m389 : 23|1@1+ (1,0) [0|0] "" Vector__XXX
 SG_ TRCM_a393_sf0Voltage m393 : 23|9@1+ (0.05,0) [0|0] "" Vector__XXX
 SG_ TRCM_a394_RAM_CRC_ERR m394 : 23|1@1+ (1,0) [0|0] "" Vector__XXX
 SG_ TRCM_a544_capacitanceIrrational m544 : 23|1@1+ (1,0) [0|0] "" Vector__XXX
 SG_ TRCM_a600_abistFailed m600 : 23|1@1+ (1,0) [0|0] "" Vector__XXX
 SG_ TRCM_a601_deploymentCounterLowCurrentCleanup m601 : 23|1@1+ (1,0) [0|0] "" Vector__XXX
 SG_ TRCM_a602_deploymentCounterLowCurrentCleanup m602 : 23|1@1+ (1,0) [0|0] "" Vector__XXX
 SG_ TRCM_a603_deploymentCounterLowCurrentCleanup m603 : 23|1@1+ (1,0) [0|0] "" Vector__XXX
 SG_ TRCM_a604_deploymentCounterLowCurrentCleanup m604 : 23|1@1+ (1,0) [0|0] "" Vector__XXX
 SG_ TRCM_a605_deploymentCounterLowCurrentCleanup m605 : 23|1@1+ (1,0) [0|0] "" Vector__XXX
 SG_ TRCM_a606_deploymentCounterLowCurrentCleanup m606 : 23|1@1+ (1,0) [0|0] "" Vector__XXX
 SG_ TRCM_a607_deploymentCounterLowCurrentCleanup m607 : 23|1@1+ (1,0) [0|0] "" Vector__XXX
 SG_ TRCM_a608_deploymentCounterLowCurrentCleanup m608 : 23|1@1+ (1,0) [0|0] "" Vector__XXX
 SG_ TRCM_a609_deploymentCounterLowCurrentCleanup m609 : 23|1@1+ (1,0) [0|0] "" Vector__XXX
 SG_ TRCM_a610_deploymentCounterLowCurrentCleanup m610 : 23|1@1+ (1,0) [0|0] "" Vector__XXX
 SG_ TRCM_a611_deploymentCounterLowCurrentCleanup m611 : 23|1@1+ (1,0) [0|0] "" Vector__XXX
 SG_ TRCM_a612_deploymentCounterLowCurrentCleanup m612 : 23|1@1+ (1,0) [0|0] "" Vector__XXX
 SG_ TRCM_a613_deploymentCounterLowCurrentCleanup m613 : 23|1@1+ (1,0) [0|0] "" Vector__XXX
 SG_ TRCM_a614_deploymentCounterLowCurrentCleanup m614 : 23|1@1+ (1,0) [0|0] "" Vector__XXX
 SG_ TRCM_a615_deploymentCounterLowCurrentCleanup m615 : 23|1@1+ (1,0) [0|0] "" Vector__XXX
 SG_ TRCM_a616_deploymentCounterLowCurrentCleanup m616 : 23|1@1+ (1,0) [0|0] "" Vector__XXX
 SG_ TRCM_a617_deploymentCounterLowCurrentCleanup m617 : 23|1@1+ (1,0) [0|0] "" Vector__XXX
 SG_ TRCM_a618_deploymentCounterLowCurrentCleanup m618 : 23|1@1+ (1,0) [0|0] "" Vector__XXX
 SG_ TRCM_a619_deploymentCounterLowCurrentCleanup m619 : 23|1@1+ (1,0) [0|0] "" Vector__XXX
 SG_ TRCM_a620_deploymentCounterLowCurrentCleanup m620 : 23|1@1+ (1,0) [0|0] "" Vector__XXX
 SG_ TRCM_a621_deploymentCounterLowCurrentCleanup m621 : 23|1@1+ (1,0) [0|0] "" Vector__XXX
 SG_ TRCM_a622_deploymentCounterLowCurrentCleanup m622 : 23|1@1+ (1,0) [0|0] "" Vector__XXX
 SG_ TRCM_a623_deploymentCounterLowCurrentCleanup m623 : 23|1@1+ (1,0) [0|0] "" Vector__XXX
 SG_ TRCM_a624_deploymentCounterLowCurrentCleanup m624 : 23|1@1+ (1,0) [0|0] "" Vector__XXX
 SG_ TRCM_a625_deploymentCounterLowCurrentCleanup m625 : 23|1@1+ (1,0) [0|0] "" Vector__XXX
 SG_ TRCM_a626_deploymentCounterLowCurrentCleanup m626 : 23|1@1+ (1,0) [0|0] "" Vector__XXX
 SG_ TRCM_a627_deploymentCounterLowCurrentCleanup m627 : 23|1@1+ (1,0) [0|0] "" Vector__XXX
 SG_ TRCM_a628_deploymentCounterLowCurrentCleanup m628 : 23|1@1+ (1,0) [0|0] "" Vector__XXX
 SG_ TRCM_a629_deploymentCounterLowCurrentCleanup m629 : 23|1@1+ (1,0) [0|0] "" Vector__XXX
 SG_ TRCM_a630_deploymentCounterLowCurrentCleanup m630 : 23|1@1+ (1,0) [0|0] "" Vector__XXX
 SG_ TRCM_a631_deploymentCounterLowCurrentCleanup m631 : 23|1@1+ (1,0) [0|0] "" Vector__XXX
 SG_ TRCM_a632_deploymentCounterLowCurrentCleanup m632 : 23|1@1+ (1,0) [0|0] "" Vector__XXX
 SG_ TRCM_a006_mailboxID m6 : 24|8@1+ (1,0) [0|0] "" Vector__XXX
 SG_ TRCM_a020_SelfTestAuto_EEPROM_OK_LATCH m20 : 24|1@1+ (1,0) [0|0] "" Vector__XXX
 SG_ TRCM_a021_Task100msMissed m21 : 24|1@1+ (1,0) [0|0] "" Vector__XXX
 SG_ TRCM_a022_TaskInitError0 m22 : 24|8@1+ (1,0) [0|0] "" Vector__XXX
 SG_ TRCM_a023_GyroSelfTestAuto_OK_X m23 : 24|1@1+ (1,0) [0|0] "" Vector__XXX
 SG_ TRCM_a024_A2D_NSAT_OK_CHY m24 : 24|1@1+ (1,0) [0|0] "" Vector__XXX
 SG_ TRCM_a025_rxErrCount m25 : 24|8@1+ (1,0) [0|0] "" Vector__XXX
 SG_ TRCM_a031_uds_bytes_1 m31 : 24|8@1+ (1,0) [0|0] "" Vector__XXX
 SG_ TRCM_a041_CPULoad1msTask m41 : 24|8@1+ (1,0) [0|0] "" Vector__XXX
 SG_ TRCM_a042_Usage10msTask m42 : 24|8@1+ (1,0) [0|0] "" Vector__XXX
 SG_ TRCM_a063_switchType m63 : 24|8@1+ (1,0) [0|0] "" Vector__XXX
 SG_ TRCM_a070_resetRetryCount m70 : 24|8@1+ (1,0) [0|0] "" Vector__XXX
 SG_ TRCM_a072_status0 m72 : 24|8@1+ (1,0) [0|0] "" Vector__XXX
 SG_ TRCM_a078_value m78 : 24|16@1- (1,0) [0|0] "" Vector__XXX
 SG_ TRCM_a086_VEH_vehNm m86 : 24|1@1+ (1,0) [0|0] "" Vector__XXX
 SG_ TRCM_a087_VEH_motorStatus m87 : 24|1@1+ (1,0) [0|0] "" Vector__XXX
 SG_ TRCM_a088_VEH_motorStatus m88 : 24|1@1+ (1,0) [0|0] "" Vector__XXX
 SG_ TRCM_a089_VEH_party1 m89 : 24|1@1+ (1,0) [0|0] "" Vector__XXX
 SG_ TRCM_a098_PARTY_thermalControl m98 : 24|1@1+ (1,0) [0|0] "" Vector__XXX
 SG_ TRCM_a104_PARTY_gpsAccuracies m104 : 24|1@1+ (1,0) [0|0] "" Vector__XXX
 SG_ TRCM_a107_PT_thermalStatus m107 : 24|1@1+ (1,0) [0|0] "" Vector__XXX
 SG_ TRCM_a108_PARTY_thermalControl m108 : 24|1@1+ (1,0) [0|0] "" Vector__XXX
 SG_ TRCM_a109_BDY_inertial1 m109 : 24|1@1+ (1,0) [0|0] "" Vector__XXX
 SG_ TRCM_a110_VEH_gearControl m110 : 24|1@1+ (1,0) [0|0] "" Vector__XXX
 SG_ TRCM_a111_VEH_LVPowerState m111 : 24|1@1+ (1,0) [0|0] "" Vector__XXX
 SG_ TRCM_a112_VEH_LVPowerState m112 : 24|1@1+ (1,0) [0|0] "" Vector__XXX
 SG_ TRCM_a113_VEH_ventCntlReq m113 : 24|1@1+ (1,0) [0|0] "" Vector__XXX
 SG_ TRCM_a114_CH_wheelRotation m114 : 24|1@1+ (1,0) [0|0] "" Vector__XXX
 SG_ TRCM_a116_VEH_doorStatus m116 : 24|1@1+ (1,0) [0|0] "" Vector__XXX
 SG_ TRCM_a117_VEH_lightStatus m117 : 24|1@1+ (1,0) [0|0] "" Vector__XXX
 SG_ TRCM_a118_VEH_12VBatteryStatus m118 : 24|1@1+ (1,0) [0|0] "" Vector__XXX
 SG_ TRCM_a120_VEH_speed m120 : 24|1@1+ (1,0) [0|0] "" Vector__XXX
 SG_ TRCM_a135_resetRetryCount m135 : 24|8@1+ (1,0) [0|0] "" Vector__XXX
 SG_ TRCM_a146_frameIndex m146 : 24|16@1+ (1,0) [0|0] "" Vector__XXX
 SG_ TRCM_a149_value m149 : 24|16@1- (1,0) [0|0] "" Vector__XXX
 SG_ TRCM_a151_frameIndex m151 : 24|16@1+ (1,0) [0|0] "" Vector__XXX
 SG_ TRCM_a154_value m154 : 24|16@1- (1,0) [0|0] "" Vector__XXX
 SG_ TRCM_a156_frameIndex m156 : 24|16@1+ (1,0) [0|0] "" Vector__XXX
 SG_ TRCM_a159_value m159 : 24|16@1- (1,0) [0|0] "" Vector__XXX
 SG_ TRCM_a161_frameIndex m161 : 24|16@1+ (1,0) [0|0] "" Vector__XXX
 SG_ TRCM_a164_value m164 : 24|16@1- (1,0) [0|0] "" Vector__XXX
 SG_ TRCM_a166_frameIndex m166 : 24|16@1+ (1,0) [0|0] "" Vector__XXX
 SG_ TRCM_a169_value m169 : 24|16@1- (1,0) [0|0] "" Vector__XXX
 SG_ TRCM_a171_frameIndex m171 : 24|16@1+ (1,0) [0|0] "" Vector__XXX
 SG_ TRCM_a174_value m174 : 24|16@1- (1,0) [0|0] "" Vector__XXX
 SG_ TRCM_a176_frameIndex m176 : 24|16@1+ (1,0) [0|0] "" Vector__XXX
 SG_ TRCM_a179_value m179 : 24|16@1- (1,0) [0|0] "" Vector__XXX
 SG_ TRCM_a201_frameIndex m201 : 24|16@1+ (1,0) [0|0] "" Vector__XXX
 SG_ TRCM_a204_value m204 : 24|16@1- (1,0) [0|0] "" Vector__XXX
 SG_ TRCM_a206_frameIndex m206 : 24|16@1+ (1,0) [0|0] "" Vector__XXX
 SG_ TRCM_a209_value m209 : 24|16@1- (1,0) [0|0] "" Vector__XXX
 SG_ TRCM_a272_SelfTestAuto_EEPROM_OK_LATCH m272 : 24|1@1+ (1,0) [0|0] "" Vector__XXX
 SG_ TRCM_a273_GyroSelfTestAuto_OK_X m273 : 24|1@1+ (1,0) [0|0] "" Vector__XXX
 SG_ TRCM_a274_GyroSelfTestAuto_OK_Z m274 : 24|1@1+ (1,0) [0|0] "" Vector__XXX
 SG_ TRCM_a275_SelfTestAuto_TC_OK_CHX m275 : 24|1@1+ (1,0) [0|0] "" Vector__XXX
 SG_ TRCM_a276_watchdogState m276 : 24|3@1+ (1,0) [0|0] "" Vector__XXX
 SG_ TRCM_a332_currentMonitorTimer m332 : 24|8@1+ (16,0) [0|0] "" Vector__XXX
 SG_ TRCM_a333_currentMonitorTimer m333 : 24|8@1+ (16,0) [0|0] "" Vector__XXX
 SG_ TRCM_a334_currentMonitorTimer m334 : 24|8@1+ (16,0) [0|0] "" Vector__XXX
 SG_ TRCM_a335_currentMonitorTimer m335 : 24|8@1+ (16,0) [0|0] "" Vector__XXX
 SG_ TRCM_a336_currentMonitorTimer m336 : 24|8@1+ (16,0) [0|0] "" Vector__XXX
 SG_ TRCM_a337_currentMonitorTimer m337 : 24|8@1+ (16,0) [0|0] "" Vector__XXX
 SG_ TRCM_a340_currentMonitorTimer m340 : 24|8@1+ (16,0) [0|0] "" Vector__XXX
 SG_ TRCM_a341_currentMonitorTimer m341 : 24|8@1+ (16,0) [0|0] "" Vector__XXX
 SG_ TRCM_a342_currentMonitorTimer m342 : 24|8@1+ (16,0) [0|0] "" Vector__XXX
 SG_ TRCM_a343_currentMonitorTimer m343 : 24|8@1+ (16,0) [0|0] "" Vector__XXX
 SG_ TRCM_a344_currentMonitorTimer m344 : 24|8@1+ (16,0) [0|0] "" Vector__XXX
 SG_ TRCM_a345_currentMonitorTimer m345 : 24|8@1+ (16,0) [0|0] "" Vector__XXX
 SG_ TRCM_a346_currentMonitorTimer m346 : 24|8@1+ (16,0) [0|0] "" Vector__XXX
 SG_ TRCM_a347_currentMonitorTimer m347 : 24|8@1+ (16,0) [0|0] "" Vector__XXX
 SG_ TRCM_a348_currentMonitorTimer m348 : 24|8@1+ (16,0) [0|0] "" Vector__XXX
 SG_ TRCM_a349_currentMonitorTimer m349 : 24|8@1+ (16,0) [0|0] "" Vector__XXX
 SG_ TRCM_a350_currentMonitorTimer m350 : 24|8@1+ (16,0) [0|0] "" Vector__XXX
 SG_ TRCM_a351_currentMonitorTimer m351 : 24|8@1+ (16,0) [0|0] "" Vector__XXX
 SG_ TRCM_a352_currentMonitorTimer m352 : 24|8@1+ (16,0) [0|0] "" Vector__XXX
 SG_ TRCM_a353_currentMonitorTimer m353 : 24|8@1+ (16,0) [0|0] "" Vector__XXX
 SG_ TRCM_a354_currentMonitorTimer m354 : 24|8@1+ (16,0) [0|0] "" Vector__XXX
 SG_ TRCM_a355_currentMonitorTimer m355 : 24|8@1+ (16,0) [0|0] "" Vector__XXX
 SG_ TRCM_a387_analogPorFlag m387 : 24|1@1+ (1,0) [0|0] "" Vector__XXX
 SG_ TRCM_a389_erDischargeSwitchOverCurrent m389 : 24|1@1+ (1,0) [0|0] "" Vector__XXX
 SG_ TRCM_a390_operatingStateExpected m390 : 24|3@1+ (1,0) [0|0] "" Vector__XXX
 SG_ TRCM_a391_operatingStateExpected m391 : 24|3@1+ (1,0) [0|0] "" Vector__XXX
 SG_ TRCM_a392_operatingStateExpected m392 : 24|3@1+ (1,0) [0|0] "" Vector__XXX
 SG_ TRCM_a394_MBIST_FLT m394 : 24|1@1+ (1,0) [0|0] "" Vector__XXX
 SG_ TRCM_a396_transferCount m396 : 24|8@1+ (1,0) [0|0] "" Vector__XXX
 SG_ TRCM_a400_resistance m400 : 24|8@1+ (0.05,0) [0|0] "" Vector__XXX
 SG_ TRCM_a401_resistance m401 : 24|8@1+ (0.05,0) [0|0] "" Vector__XXX
 SG_ TRCM_a402_resistance m402 : 24|8@1+ (0.05,0) [0|0] "" Vector__XXX
 SG_ TRCM_a403_resistance m403 : 24|8@1+ (0.05,0) [0|0] "" Vector__XXX
 SG_ TRCM_a404_resistance m404 : 24|8@1+ (0.05,0) [0|0] "" Vector__XXX
 SG_ TRCM_a405_resistance m405 : 24|8@1+ (0.05,0) [0|0] "" Vector__XXX
 SG_ TRCM_a408_resistance m408 : 24|8@1+ (0.05,0) [0|0] "" Vector__XXX
 SG_ TRCM_a409_resistance m409 : 24|8@1+ (0.05,0) [0|0] "" Vector__XXX
 SG_ TRCM_a410_resistance m410 : 24|8@1+ (0.05,0) [0|0] "" Vector__XXX
 SG_ TRCM_a411_resistance m411 : 24|8@1+ (0.05,0) [0|0] "" Vector__XXX
 SG_ TRCM_a412_resistance m412 : 24|8@1+ (0.05,0) [0|0] "" Vector__XXX
 SG_ TRCM_a413_resistance m413 : 24|8@1+ (0.05,0) [0|0] "" Vector__XXX
 SG_ TRCM_a414_resistance m414 : 24|8@1+ (0.05,0) [0|0] "" Vector__XXX
 SG_ TRCM_a415_resistance m415 : 24|8@1+ (0.05,0) [0|0] "" Vector__XXX
 SG_ TRCM_a416_resistance m416 : 24|8@1+ (0.05,0) [0|0] "" Vector__XXX
 SG_ TRCM_a417_resistance m417 : 24|8@1+ (0.05,0) [0|0] "" Vector__XXX
 SG_ TRCM_a418_resistance m418 : 24|8@1+ (0.05,0) [0|0] "" Vector__XXX
 SG_ TRCM_a419_resistance m419 : 24|8@1+ (0.05,0) [0|0] "" Vector__XXX
 SG_ TRCM_a420_resistance m420 : 24|8@1+ (0.05,0) [0|0] "" Vector__XXX
 SG_ TRCM_a421_resistance m421 : 24|8@1+ (0.05,0) [0|0] "" Vector__XXX
 SG_ TRCM_a422_resistance m422 : 24|8@1+ (0.05,0) [0|0] "" Vector__XXX
 SG_ TRCM_a423_resistance m423 : 24|8@1+ (0.05,0) [0|0] "" Vector__XXX
 SG_ TRCM_a544_esrHigh m544 : 24|1@1+ (1,0) [0|0] "" Vector__XXX
 SG_ TRCM_a600_depAbistFailedNoSsOv m600 : 24|1@1+ (1,0) [0|0] "" Vector__XXX
 SG_ TRCM_a601_leakageToGnd m601 : 24|1@1+ (1,0) [0|0] "" Vector__XXX
 SG_ TRCM_a602_leakageToGnd m602 : 24|1@1+ (1,0) [0|0] "" Vector__XXX
 SG_ TRCM_a603_leakageToGnd m603 : 24|1@1+ (1,0) [0|0] "" Vector__XXX
 SG_ TRCM_a604_leakageToGnd m604 : 24|1@1+ (1,0) [0|0] "" Vector__XXX
 SG_ TRCM_a605_leakageToGnd m605 : 24|1@1+ (1,0) [0|0] "" Vector__XXX
 SG_ TRCM_a606_leakageToGnd m606 : 24|1@1+ (1,0) [0|0] "" Vector__XXX
 SG_ TRCM_a607_leakageToGnd m607 : 24|1@1+ (1,0) [0|0] "" Vector__XXX
 SG_ TRCM_a608_leakageToGnd m608 : 24|1@1+ (1,0) [0|0] "" Vector__XXX
 SG_ TRCM_a609_leakageToGnd m609 : 24|1@1+ (1,0) [0|0] "" Vector__XXX
 SG_ TRCM_a610_leakageToGnd m610 : 24|1@1+ (1,0) [0|0] "" Vector__XXX
 SG_ TRCM_a611_leakageToGnd m611 : 24|1@1+ (1,0) [0|0] "" Vector__XXX
 SG_ TRCM_a612_leakageToGnd m612 : 24|1@1+ (1,0) [0|0] "" Vector__XXX
 SG_ TRCM_a613_leakageToGnd m613 : 24|1@1+ (1,0) [0|0] "" Vector__XXX
 SG_ TRCM_a614_leakageToGnd m614 : 24|1@1+ (1,0) [0|0] "" Vector__XXX
 SG_ TRCM_a615_leakageToGnd m615 : 24|1@1+ (1,0) [0|0] "" Vector__XXX
 SG_ TRCM_a616_leakageToGnd m616 : 24|1@1+ (1,0) [0|0] "" Vector__XXX
 SG_ TRCM_a617_leakageToGnd m617 : 24|1@1+ (1,0) [0|0] "" Vector__XXX
 SG_ TRCM_a618_leakageToGnd m618 : 24|1@1+ (1,0) [0|0] "" Vector__XXX
 SG_ TRCM_a619_leakageToGnd m619 : 24|1@1+ (1,0) [0|0] "" Vector__XXX
 SG_ TRCM_a620_leakageToGnd m620 : 24|1@1+ (1,0) [0|0] "" Vector__XXX
 SG_ TRCM_a621_leakageToGnd m621 : 24|1@1+ (1,0) [0|0] "" Vector__XXX
 SG_ TRCM_a622_leakageToGnd m622 : 24|1@1+ (1,0) [0|0] "" Vector__XXX
 SG_ TRCM_a623_leakageToGnd m623 : 24|1@1+ (1,0) [0|0] "" Vector__XXX
 SG_ TRCM_a624_leakageToGnd m624 : 24|1@1+ (1,0) [0|0] "" Vector__XXX
 SG_ TRCM_a625_leakageToGnd m625 : 24|1@1+ (1,0) [0|0] "" Vector__XXX
 SG_ TRCM_a626_leakageToGnd m626 : 24|1@1+ (1,0) [0|0] "" Vector__XXX
 SG_ TRCM_a627_leakageToGnd m627 : 24|1@1+ (1,0) [0|0] "" Vector__XXX
 SG_ TRCM_a628_leakageToGnd m628 : 24|1@1+ (1,0) [0|0] "" Vector__XXX
 SG_ TRCM_a629_leakageToGnd m629 : 24|1@1+ (1,0) [0|0] "" Vector__XXX
 SG_ TRCM_a630_leakageToGnd m630 : 24|1@1+ (1,0) [0|0] "" Vector__XXX
 SG_ TRCM_a631_leakageToGnd m631 : 24|1@1+ (1,0) [0|0] "" Vector__XXX
 SG_ TRCM_a632_leakageToGnd m632 : 24|1@1+ (1,0) [0|0] "" Vector__XXX
 SG_ TRCM_a633_obtainedRegisterValue m633 : 24|16@1+ (1,0) [0|0] "" Vector__XXX
 SG_ TRCM_a634_obtainedRegisterValueUnsigned m634 : 24|16@1+ (1,0) [0|0] "" Vector__XXX
 SG_ TRCM_a635_obtainedRegisterValueUnsigned m635 : 24|16@1+ (1,0) [0|0] "" Vector__XXX
 SG_ TRCM_a637_obtainedRegisterValue m637 : 24|16@1+ (1,0) [0|0] "" Vector__XXX
 SG_ TRCM_a638_obtainedValue m638 : 24|16@1- (1,0) [0|0] "" Vector__XXX
 SG_ TRCM_a639_obtainedValue m639 : 24|16@1- (1,0) [0|0] "" Vector__XXX
 SG_ TRCM_a640_obtainedValue m640 : 24|16@1- (1,0) [0|0] "" Vector__XXX
 SG_ TRCM_a641_expectedRangeMin m641 : 24|8@1+ (1,0) [0|0] "" Vector__XXX
 SG_ TRCM_a642_obtainedRegisterValue m642 : 24|16@1+ (1,0) [0|0] "" Vector__XXX
 SG_ TRCM_a643_obtainedValue m643 : 24|16@1- (1,0) [0|0] "" Vector__XXX
 SG_ TRCM_a020_SelfTestAuto_LOSSCAP2_OK_LATCH m20 : 25|1@1+ (1,0) [0|0] "" Vector__XXX
 SG_ TRCM_a021_Task1000msLate m21 : 25|1@1+ (1,0) [0|0] "" Vector__XXX
 SG_ TRCM_a023_SNS_Amp_OK_X m23 : 25|1@1+ (1,0) [0|0] "" Vector__XXX
 SG_ TRCM_a024_RotorBond_OK_ChZ m24 : 25|1@1+ (1,0) [0|0] "" Vector__XXX
 SG_ TRCM_a035_eventArmStatus m35 : 25|1@1+ (1,0) [0|0] "" Vector__XXX
 SG_ TRCM_a036_eventArmStatus m36 : 25|1@1+ (1,0) [0|0] "" Vector__XXX
 SG_ TRCM_a037_eventArmStatus m37 : 25|1@1+ (1,0) [0|0] "" Vector__XXX
 SG_ TRCM_a040_airbagAsicsRsspiState m40 : 25|4@1+ (1,0) [0|0] "" Vector__XXX
 SG_ TRCM_a081_eventArmStatus m81 : 25|1@1+ (1,0) [0|0] "" Vector__XXX
 SG_ TRCM_a089_VEH_party3 m89 : 25|1@1+ (1,0) [0|0] "" Vector__XXX
 SG_ TRCM_a098_PARTY_torque m98 : 25|1@1+ (1,0) [0|0] "" Vector__XXX
 SG_ TRCM_a104_CH_status m104 : 25|1@1+ (1,0) [0|0] "" Vector__XXX
 SG_ TRCM_a107_PT_socStatus m107 : 25|1@1+ (1,0) [0|0] "" Vector__XXX
 SG_ TRCM_a108_PT_temperature m108 : 25|1@1+ (1,0) [0|0] "" Vector__XXX
 SG_ TRCM_a109_BDY_inertial2 m109 : 25|1@1+ (1,0) [0|0] "" Vector__XXX
 SG_ TRCM_a110_VEH_canLogAvailability m110 : 25|1@1+ (1,0) [0|0] "" Vector__XXX
 SG_ TRCM_a111_VEH_seatStatus m111 : 25|1@1+ (1,0) [0|0] "" Vector__XXX
 SG_ TRCM_a112_PARTY_status m112 : 25|1@1+ (1,0) [0|0] "" Vector__XXX
 SG_ TRCM_a113_VEH_chassisControl m113 : 25|1@1+ (1,0) [0|0] "" Vector__XXX
 SG_ TRCM_a114_VEH_wheelRotation m114 : 25|1@1+ (1,0) [0|0] "" Vector__XXX
 SG_ TRCM_a116_VEH_seatHeatStatus m116 : 25|1@1+ (1,0) [0|0] "" Vector__XXX
 SG_ TRCM_a117_VEH_seatStatus m117 : 25|1@1+ (1,0) [0|0] "" Vector__XXX
 SG_ TRCM_a118_VEH_systemStatus m118 : 25|1@1+ (1,0) [0|0] "" Vector__XXX
 SG_ TRCM_a120_PARTY_status m120 : 25|1@1+ (1,0) [0|0] "" Vector__XXX
 SG_ TRCM_a272_SelfTestAuto_LOSSCAP2_OK_LATCH m272 : 25|1@1+ (1,0) [0|0] "" Vector__XXX
 SG_ TRCM_a273_SNS_Amp_OK_X m273 : 25|1@1+ (1,0) [0|0] "" Vector__XXX
 SG_ TRCM_a274_SNS_Amp_OK_Z m274 : 25|1@1+ (1,0) [0|0] "" Vector__XXX
 SG_ TRCM_a275_A2D_NSAT_OK_CHZ m275 : 25|1@1+ (1,0) [0|0] "" Vector__XXX
 SG_ TRCM_a387_wdReset m387 : 25|1@1+ (1,0) [0|0] "" Vector__XXX
 SG_ TRCM_a389_erSwitchOverTemperature m389 : 25|1@1+ (1,0) [0|0] "" Vector__XXX
 SG_ TRCM_a394_LBIST_FLT m394 : 25|1@1+ (1,0) [0|0] "" Vector__XXX
 SG_ TRCM_a544_esrIrrational m544 : 25|1@1+ (1,0) [0|0] "" Vector__XXX
 SG_ TRCM_a600_depAbistFailedNoSgLoss m600 : 25|1@1+ (1,0) [0|0] "" Vector__XXX
 SG_ TRCM_a601_leakageToBat m601 : 25|1@1+ (1,0) [0|0] "" Vector__XXX
 SG_ TRCM_a602_leakageToBat m602 : 25|1@1+ (1,0) [0|0] "" Vector__XXX
 SG_ TRCM_a603_leakageToBat m603 : 25|1@1+ (1,0) [0|0] "" Vector__XXX
 SG_ TRCM_a604_leakageToBat m604 : 25|1@1+ (1,0) [0|0] "" Vector__XXX
 SG_ TRCM_a605_leakageToBat m605 : 25|1@1+ (1,0) [0|0] "" Vector__XXX
 SG_ TRCM_a606_leakageToBat m606 : 25|1@1+ (1,0) [0|0] "" Vector__XXX
 SG_ TRCM_a607_leakageToBat m607 : 25|1@1+ (1,0) [0|0] "" Vector__XXX
 SG_ TRCM_a608_leakageToBat m608 : 25|1@1+ (1,0) [0|0] "" Vector__XXX
 SG_ TRCM_a609_leakageToBat m609 : 25|1@1+ (1,0) [0|0] "" Vector__XXX
 SG_ TRCM_a610_leakageToBat m610 : 25|1@1+ (1,0) [0|0] "" Vector__XXX
 SG_ TRCM_a611_leakageToBat m611 : 25|1@1+ (1,0) [0|0] "" Vector__XXX
 SG_ TRCM_a612_leakageToBat m612 : 25|1@1+ (1,0) [0|0] "" Vector__XXX
 SG_ TRCM_a613_leakageToBat m613 : 25|1@1+ (1,0) [0|0] "" Vector__XXX
 SG_ TRCM_a614_leakageToBat m614 : 25|1@1+ (1,0) [0|0] "" Vector__XXX
 SG_ TRCM_a615_leakageToBat m615 : 25|1@1+ (1,0) [0|0] "" Vector__XXX
 SG_ TRCM_a616_leakageToBat m616 : 25|1@1+ (1,0) [0|0] "" Vector__XXX
 SG_ TRCM_a617_leakageToBat m617 : 25|1@1+ (1,0) [0|0] "" Vector__XXX
 SG_ TRCM_a618_leakageToBat m618 : 25|1@1+ (1,0) [0|0] "" Vector__XXX
 SG_ TRCM_a619_leakageToBat m619 : 25|1@1+ (1,0) [0|0] "" Vector__XXX
 SG_ TRCM_a620_leakageToBat m620 : 25|1@1+ (1,0) [0|0] "" Vector__XXX
 SG_ TRCM_a621_leakageToBat m621 : 25|1@1+ (1,0) [0|0] "" Vector__XXX
 SG_ TRCM_a622_leakageToBat m622 : 25|1@1+ (1,0) [0|0] "" Vector__XXX
 SG_ TRCM_a623_leakageToBat m623 : 25|1@1+ (1,0) [0|0] "" Vector__XXX
 SG_ TRCM_a624_leakageToBat m624 : 25|1@1+ (1,0) [0|0] "" Vector__XXX
 SG_ TRCM_a625_leakageToBat m625 : 25|1@1+ (1,0) [0|0] "" Vector__XXX
 SG_ TRCM_a626_leakageToBat m626 : 25|1@1+ (1,0) [0|0] "" Vector__XXX
 SG_ TRCM_a627_leakageToBat m627 : 25|1@1+ (1,0) [0|0] "" Vector__XXX
 SG_ TRCM_a628_leakageToBat m628 : 25|1@1+ (1,0) [0|0] "" Vector__XXX
 SG_ TRCM_a629_leakageToBat m629 : 25|1@1+ (1,0) [0|0] "" Vector__XXX
 SG_ TRCM_a630_leakageToBat m630 : 25|1@1+ (1,0) [0|0] "" Vector__XXX
 SG_ TRCM_a631_leakageToBat m631 : 25|1@1+ (1,0) [0|0] "" Vector__XXX
 SG_ TRCM_a632_leakageToBat m632 : 25|1@1+ (1,0) [0|0] "" Vector__XXX
 SG_ TRCM_a020_SelfTestAuto_LOSSCAP1_OK_LATCH m20 : 26|1@1+ (1,0) [0|0] "" Vector__XXX
 SG_ TRCM_a021_Task1000msStarved m21 : 26|1@1+ (1,0) [0|0] "" Vector__XXX
 SG_ TRCM_a023_QC_Amp_OK_X m23 : 26|1@1+ (1,0) [0|0] "" Vector__XXX
 SG_ TRCM_a024_RotorBond_OK_ChY m24 : 26|1@1+ (1,0) [0|0] "" Vector__XXX
 SG_ TRCM_a098_PT_thermalControl m98 : 26|1@1+ (1,0) [0|0] "" Vector__XXX
 SG_ TRCM_a104_PARTY_status m104 : 26|1@1+ (1,0) [0|0] "" Vector__XXX
 SG_ TRCM_a107_VEH_socStatus m107 : 26|1@1+ (1,0) [0|0] "" Vector__XXX
 SG_ TRCM_a108_PT_thermalControl m108 : 26|1@1+ (1,0) [0|0] "" Vector__XXX
 SG_ TRCM_a109_BDY_status m109 : 26|1@1+ (1,0) [0|0] "" Vector__XXX
 SG_ TRCM_a110_CH_airbagCutoffStatus m110 : 26|1@1+ (1,0) [0|0] "" Vector__XXX
 SG_ TRCM_a111_PARTY_status m111 : 26|1@1+ (1,0) [0|0] "" Vector__XXX
 SG_ TRCM_a112_CH_status m112 : 26|1@1+ (1,0) [0|0] "" Vector__XXX
 SG_ TRCM_a113_VEH_trackModeSettings m113 : 26|1@1+ (1,0) [0|0] "" Vector__XXX
 SG_ TRCM_a114_PARTY_brakeTorque m114 : 26|1@1+ (1,0) [0|0] "" Vector__XXX
 SG_ TRCM_a116_VEH_restraintStatus m116 : 26|1@1+ (1,0) [0|0] "" Vector__XXX
 SG_ TRCM_a117_BDY_falconSwitchStatus m117 : 26|1@1+ (1,0) [0|0] "" Vector__XXX
 SG_ TRCM_a118_PARTY_LVPowerState m118 : 26|1@1+ (1,0) [0|0] "" Vector__XXX
 SG_ TRCM_a120_PT_speed m120 : 26|1@1+ (1,0) [0|0] "" Vector__XXX
 SG_ TRCM_a272_SelfTestAuto_LOSSCAP1_OK_LATCH m272 : 26|1@1+ (1,0) [0|0] "" Vector__XXX
 SG_ TRCM_a273_QC_Amp_OK_X m273 : 26|1@1+ (1,0) [0|0] "" Vector__XXX
 SG_ TRCM_a274_QC_Amp_OK_Z m274 : 26|1@1+ (1,0) [0|0] "" Vector__XXX
 SG_ TRCM_a275_A2D_NSAT_OK_CHY m275 : 26|1@1+ (1,0) [0|0] "" Vector__XXX
 SG_ TRCM_a387_mcuRstFlag m387 : 26|1@1+ (1,0) [0|0] "" Vector__XXX
 SG_ TRCM_a389_erBoostPulseSkipping m389 : 26|1@1+ (1,0) [0|0] "" Vector__XXX
 SG_ TRCM_a394_POWERFLT m394 : 26|1@1+ (1,0) [0|0] "" Vector__XXX
 SG_ TRCM_a544_runtimeEstimateLow m544 : 26|1@1+ (1,0) [0|0] "" Vector__XXX
 SG_ TRCM_a600_depAbistFailedNoError m600 : 26|1@1+ (1,0) [0|0] "" Vector__XXX
 SG_ TRCM_a601_currentSourceTestFailed m601 : 26|1@1+ (1,0) [0|0] "" Vector__XXX
 SG_ TRCM_a602_currentSourceTestFailed m602 : 26|1@1+ (1,0) [0|0] "" Vector__XXX
 SG_ TRCM_a603_currentSourceTestFailed m603 : 26|1@1+ (1,0) [0|0] "" Vector__XXX
 SG_ TRCM_a604_currentSourceTestFailed m604 : 26|1@1+ (1,0) [0|0] "" Vector__XXX
 SG_ TRCM_a605_currentSourceTestFailed m605 : 26|1@1+ (1,0) [0|0] "" Vector__XXX
 SG_ TRCM_a606_currentSourceTestFailed m606 : 26|1@1+ (1,0) [0|0] "" Vector__XXX
 SG_ TRCM_a607_currentSourceTestFailed m607 : 26|1@1+ (1,0) [0|0] "" Vector__XXX
 SG_ TRCM_a608_currentSourceTestFailed m608 : 26|1@1+ (1,0) [0|0] "" Vector__XXX
 SG_ TRCM_a609_currentSourceTestFailed m609 : 26|1@1+ (1,0) [0|0] "" Vector__XXX
 SG_ TRCM_a610_currentSourceTestFailed m610 : 26|1@1+ (1,0) [0|0] "" Vector__XXX
 SG_ TRCM_a611_currentSourceTestFailed m611 : 26|1@1+ (1,0) [0|0] "" Vector__XXX
 SG_ TRCM_a612_currentSourceTestFailed m612 : 26|1@1+ (1,0) [0|0] "" Vector__XXX
 SG_ TRCM_a613_currentSourceTestFailed m613 : 26|1@1+ (1,0) [0|0] "" Vector__XXX
 SG_ TRCM_a614_currentSourceTestFailed m614 : 26|1@1+ (1,0) [0|0] "" Vector__XXX
 SG_ TRCM_a615_currentSourceTestFailed m615 : 26|1@1+ (1,0) [0|0] "" Vector__XXX
 SG_ TRCM_a616_currentSourceTestFailed m616 : 26|1@1+ (1,0) [0|0] "" Vector__XXX
 SG_ TRCM_a617_currentSourceTestFailed m617 : 26|1@1+ (1,0) [0|0] "" Vector__XXX
 SG_ TRCM_a618_currentSourceTestFailed m618 : 26|1@1+ (1,0) [0|0] "" Vector__XXX
 SG_ TRCM_a619_currentSourceTestFailed m619 : 26|1@1+ (1,0) [0|0] "" Vector__XXX
 SG_ TRCM_a620_currentSourceTestFailed m620 : 26|1@1+ (1,0) [0|0] "" Vector__XXX
 SG_ TRCM_a621_currentSourceTestFailed m621 : 26|1@1+ (1,0) [0|0] "" Vector__XXX
 SG_ TRCM_a622_currentSourceTestFailed m622 : 26|1@1+ (1,0) [0|0] "" Vector__XXX
 SG_ TRCM_a623_currentSourceTestFailed m623 : 26|1@1+ (1,0) [0|0] "" Vector__XXX
 SG_ TRCM_a624_currentSourceTestFailed m624 : 26|1@1+ (1,0) [0|0] "" Vector__XXX
 SG_ TRCM_a625_currentSourceTestFailed m625 : 26|1@1+ (1,0) [0|0] "" Vector__XXX
 SG_ TRCM_a626_currentSourceTestFailed m626 : 26|1@1+ (1,0) [0|0] "" Vector__XXX
 SG_ TRCM_a627_currentSourceTestFailed m627 : 26|1@1+ (1,0) [0|0] "" Vector__XXX
 SG_ TRCM_a628_currentSourceTestFailed m628 : 26|1@1+ (1,0) [0|0] "" Vector__XXX
 SG_ TRCM_a629_currentSourceTestFailed m629 : 26|1@1+ (1,0) [0|0] "" Vector__XXX
 SG_ TRCM_a630_currentSourceTestFailed m630 : 26|1@1+ (1,0) [0|0] "" Vector__XXX
 SG_ TRCM_a631_currentSourceTestFailed m631 : 26|1@1+ (1,0) [0|0] "" Vector__XXX
 SG_ TRCM_a632_currentSourceTestFailed m632 : 26|1@1+ (1,0) [0|0] "" Vector__XXX
 SG_ TRCM_a020_SPI_No_Err m20 : 27|1@1+ (1,0) [0|0] "" Vector__XXX
 SG_ TRCM_a021_Task1000msMissed m21 : 27|1@1+ (1,0) [0|0] "" Vector__XXX
 SG_ TRCM_a023_Rate_Not_Sat_X m23 : 27|1@1+ (1,0) [0|0] "" Vector__XXX
 SG_ TRCM_a098_PT_temperature m98 : 27|1@1+ (1,0) [0|0] "" Vector__XXX
 SG_ TRCM_a104_PARTY_steeringControl m104 : 27|1@1+ (1,0) [0|0] "" Vector__XXX
 SG_ TRCM_a107_VEH_packConfig m107 : 27|1@1+ (1,0) [0|0] "" Vector__XXX
 SG_ TRCM_a108_PARTY_motorStatus m108 : 27|1@1+ (1,0) [0|0] "" Vector__XXX
 SG_ TRCM_a109_VEH_inertial1 m109 : 27|1@1+ (1,0) [0|0] "" Vector__XXX
 SG_ TRCM_a110_CH_carConfig m110 : 27|1@1+ (1,0) [0|0] "" Vector__XXX
 SG_ TRCM_a111_CH_status m111 : 27|1@1+ (1,0) [0|0] "" Vector__XXX
 SG_ TRCM_a113_VEH_powertrainControl m113 : 27|1@1+ (1,0) [0|0] "" Vector__XXX
 SG_ TRCM_a114_PARTY_offsets m114 : 27|1@1+ (1,0) [0|0] "" Vector__XXX
 SG_ TRCM_a116_VEH_switchStatus m116 : 27|1@1+ (1,0) [0|0] "" Vector__XXX
 SG_ TRCM_a117_VEH_doorStatus m117 : 27|1@1+ (1,0) [0|0] "" Vector__XXX
 SG_ TRCM_a118_PARTY_outputPowerStatus m118 : 27|1@1+ (1,0) [0|0] "" Vector__XXX
 SG_ TRCM_a120_PT_systemStatus m120 : 27|1@1+ (1,0) [0|0] "" Vector__XXX
 SG_ TRCM_a272_SPI_No_Err m272 : 27|1@1+ (1,0) [0|0] "" Vector__XXX
 SG_ TRCM_a273_Rate_Not_Sat_X m273 : 27|1@1+ (1,0) [0|0] "" Vector__XXX
 SG_ TRCM_a274_Rate_Not_Sat_Z m274 : 27|1@1+ (1,0) [0|0] "" Vector__XXX
 SG_ TRCM_a275_A2D_NSAT_OK_CHX m275 : 27|1@1+ (1,0) [0|0] "" Vector__XXX
 SG_ TRCM_a276_watchdogLockoutLatched m276 : 27|1@1+ (1,0) [0|0] "" Vector__XXX
 SG_ TRCM_a387_clockStuckError m387 : 27|1@1+ (1,0) [0|0] "" Vector__XXX
 SG_ TRCM_a389_powerGroundLoss m389 : 27|1@1+ (1,0) [0|0] "" Vector__XXX
 SG_ TRCM_a394_ERSTATE m394 : 27|1@1+ (1,0) [0|0] "" Vector__XXX
 SG_ TRCM_a544_switchChargeTimeout m544 : 27|1@1+ (1,0) [0|0] "" Vector__XXX
 SG_ TRCM_a600_depAbistFailedSsOv m600 : 27|1@1+ (1,0) [0|0] "" Vector__XXX
 SG_ TRCM_a601_vrcmCurrentSourceTestSfxBroken m601 : 27|1@1+ (1,0) [0|0] "" Vector__XXX
 SG_ TRCM_a602_vrcmCurrentSourceTestSfxBroken m602 : 27|1@1+ (1,0) [0|0] "" Vector__XXX
 SG_ TRCM_a603_vrcmCurrentSourceTestSfxBroken m603 : 27|1@1+ (1,0) [0|0] "" Vector__XXX
 SG_ TRCM_a604_vrcmCurrentSourceTestSfxBroken m604 : 27|1@1+ (1,0) [0|0] "" Vector__XXX
 SG_ TRCM_a605_vrcmCurrentSourceTestSfxBroken m605 : 27|1@1+ (1,0) [0|0] "" Vector__XXX
 SG_ TRCM_a606_vrcmCurrentSourceTestSfxBroken m606 : 27|1@1+ (1,0) [0|0] "" Vector__XXX
 SG_ TRCM_a607_vrcmCurrentSourceTestSfxBroken m607 : 27|1@1+ (1,0) [0|0] "" Vector__XXX
 SG_ TRCM_a608_vrcmCurrentSourceTestSfxBroken m608 : 27|1@1+ (1,0) [0|0] "" Vector__XXX
 SG_ TRCM_a609_vrcmCurrentSourceTestSfxBroken m609 : 27|1@1+ (1,0) [0|0] "" Vector__XXX
 SG_ TRCM_a610_vrcmCurrentSourceTestSfxBroken m610 : 27|1@1+ (1,0) [0|0] "" Vector__XXX
 SG_ TRCM_a611_vrcmCurrentSourceTestSfxBroken m611 : 27|1@1+ (1,0) [0|0] "" Vector__XXX
 SG_ TRCM_a612_vrcmCurrentSourceTestSfxBroken m612 : 27|1@1+ (1,0) [0|0] "" Vector__XXX
 SG_ TRCM_a613_vrcmCurrentSourceTestSfxBroken m613 : 27|1@1+ (1,0) [0|0] "" Vector__XXX
 SG_ TRCM_a614_vrcmCurrentSourceTestSfxBroken m614 : 27|1@1+ (1,0) [0|0] "" Vector__XXX
 SG_ TRCM_a615_vrcmCurrentSourceTestSfxBroken m615 : 27|1@1+ (1,0) [0|0] "" Vector__XXX
 SG_ TRCM_a616_vrcmCurrentSourceTestSfxBroken m616 : 27|1@1+ (1,0) [0|0] "" Vector__XXX
 SG_ TRCM_a617_vrcmCurrentSourceTestSfxBroken m617 : 27|1@1+ (1,0) [0|0] "" Vector__XXX
 SG_ TRCM_a618_vrcmCurrentSourceTestSfxBroken m618 : 27|1@1+ (1,0) [0|0] "" Vector__XXX
 SG_ TRCM_a619_vrcmCurrentSourceTestSfxBroken m619 : 27|1@1+ (1,0) [0|0] "" Vector__XXX
 SG_ TRCM_a620_vrcmCurrentSourceTestSfxBroken m620 : 27|1@1+ (1,0) [0|0] "" Vector__XXX
 SG_ TRCM_a621_vrcmCurrentSourceTestSfxBroken m621 : 27|1@1+ (1,0) [0|0] "" Vector__XXX
 SG_ TRCM_a622_vrcmCurrentSourceTestSfxBroken m622 : 27|1@1+ (1,0) [0|0] "" Vector__XXX
 SG_ TRCM_a623_vrcmCurrentSourceTestSfxBroken m623 : 27|1@1+ (1,0) [0|0] "" Vector__XXX
 SG_ TRCM_a624_vrcmCurrentSourceTestSfxBroken m624 : 27|1@1+ (1,0) [0|0] "" Vector__XXX
 SG_ TRCM_a625_vrcmCurrentSourceTestSfxBroken m625 : 27|1@1+ (1,0) [0|0] "" Vector__XXX
 SG_ TRCM_a626_vrcmCurrentSourceTestSfxBroken m626 : 27|1@1+ (1,0) [0|0] "" Vector__XXX
 SG_ TRCM_a627_vrcmCurrentSourceTestSfxBroken m627 : 27|1@1+ (1,0) [0|0] "" Vector__XXX
 SG_ TRCM_a628_vrcmCurrentSourceTestSfxBroken m628 : 27|1@1+ (1,0) [0|0] "" Vector__XXX
 SG_ TRCM_a629_vrcmCurrentSourceTestSfxBroken m629 : 27|1@1+ (1,0) [0|0] "" Vector__XXX
 SG_ TRCM_a630_vrcmCurrentSourceTestSfxBroken m630 : 27|1@1+ (1,0) [0|0] "" Vector__XXX
 SG_ TRCM_a631_vrcmCurrentSourceTestSfxBroken m631 : 27|1@1+ (1,0) [0|0] "" Vector__XXX
 SG_ TRCM_a632_vrcmCurrentSourceTestSfxBroken m632 : 27|1@1+ (1,0) [0|0] "" Vector__XXX
 SG_ TRCM_a020_TS_OK m20 : 28|1@1+ (1,0) [0|0] "" Vector__XXX
 SG_ TRCM_a023_Start_OK_X m23 : 28|1@1+ (1,0) [0|0] "" Vector__XXX
 SG_ TRCM_a058_current m58 : 28|11@1+ (0.1,0) [0|0] "" Vector__XXX
 SG_ TRCM_a059_resistanceEstimate m59 : 28|12@1+ (0.00244,0) [0|0] "" Vector__XXX
 SG_ TRCM_a098_PARTY_motorStatus m98 : 28|1@1+ (1,0) [0|0] "" Vector__XXX
 SG_ TRCM_a104_CH_steeringControl m104 : 28|1@1+ (1,0) [0|0] "" Vector__XXX
 SG_ TRCM_a107_VEH_energyStatus m107 : 28|1@1+ (1,0) [0|0] "" Vector__XXX
 SG_ TRCM_a108_VEH_motorStatus m108 : 28|1@1+ (1,0) [0|0] "" Vector__XXX
 SG_ TRCM_a109_VEH_inertial2 m109 : 28|1@1+ (1,0) [0|0] "" Vector__XXX
 SG_ TRCM_a110_CH_carState m110 : 28|1@1+ (1,0) [0|0] "" Vector__XXX
 SG_ TRCM_a113_VEH_vehicleModes m113 : 28|1@1+ (1,0) [0|0] "" Vector__XXX
 SG_ TRCM_a114_BDY_offsets m114 : 28|1@1+ (1,0) [0|0] "" Vector__XXX
 SG_ TRCM_a116_VEH_logging1Hz m116 : 28|1@1+ (1,0) [0|0] "" Vector__XXX
 SG_ TRCM_a117_VEH_doorStatus2 m117 : 28|1@1+ (1,0) [0|0] "" Vector__XXX
 SG_ TRCM_a118_PARTY_vehicleTime m118 : 28|1@1+ (1,0) [0|0] "" Vector__XXX
 SG_ TRCM_a120_PARTY_vehicleEstimates m120 : 28|1@1+ (1,0) [0|0] "" Vector__XXX
 SG_ TRCM_a148_manufacturerSensorCode m148 : 28|8@1+ (1,0) [0|0] "" Vector__XXX
 SG_ TRCM_a153_manufacturerSensorCode m153 : 28|8@1+ (1,0) [0|0] "" Vector__XXX
 SG_ TRCM_a158_manufacturerSensorCode m158 : 28|8@1+ (1,0) [0|0] "" Vector__XXX
 SG_ TRCM_a163_manufacturerSensorCode m163 : 28|8@1+ (1,0) [0|0] "" Vector__XXX
 SG_ TRCM_a168_manufacturerSensorCode m168 : 28|8@1+ (1,0) [0|0] "" Vector__XXX
 SG_ TRCM_a173_manufacturerSensorCode m173 : 28|8@1+ (1,0) [0|0] "" Vector__XXX
 SG_ TRCM_a178_manufacturerSensorCode m178 : 28|8@1+ (1,0) [0|0] "" Vector__XXX
 SG_ TRCM_a203_manufacturerSensorCode m203 : 28|8@1+ (1,0) [0|0] "" Vector__XXX
 SG_ TRCM_a208_manufacturerSensorCode m208 : 28|8@1+ (1,0) [0|0] "" Vector__XXX
 SG_ TRCM_a272_TS_OK m272 : 28|1@1+ (1,0) [0|0] "" Vector__XXX
 SG_ TRCM_a273_Start_OK_X m273 : 28|1@1+ (1,0) [0|0] "" Vector__XXX
 SG_ TRCM_a274_Start_OK_Z m274 : 28|1@1+ (1,0) [0|0] "" Vector__XXX
 SG_ TRCM_a275_RotorBond_OK_ChZ m275 : 28|1@1+ (1,0) [0|0] "" Vector__XXX
 SG_ TRCM_a276_watchdogResetLatched m276 : 28|1@1+ (1,0) [0|0] "" Vector__XXX
 SG_ TRCM_a387_frequencyErrorCode m387 : 28|2@1+ (1,0) [0|0] "" Vector__XXX
 SG_ TRCM_a389_satBuckGroundLoss m389 : 28|1@1+ (1,0) [0|0] "" Vector__XXX
 SG_ TRCM_a394_TM_PIN m394 : 28|1@1+ (1,0) [0|0] "" Vector__XXX
 SG_ TRCM_a544_chargeSwitchChargingTimeout m544 : 28|1@1+ (1,0) [0|0] "" Vector__XXX
 SG_ TRCM_a600_depAbistFailedSgLoss m600 : 28|1@1+ (1,0) [0|0] "" Vector__XXX
 SG_ TRCM_a601_vrcmCurrentSourceTestSrxBroken m601 : 28|1@1+ (1,0) [0|0] "" Vector__XXX
 SG_ TRCM_a602_vrcmCurrentSourceTestSrxBroken m602 : 28|1@1+ (1,0) [0|0] "" Vector__XXX
 SG_ TRCM_a603_vrcmCurrentSourceTestSrxBroken m603 : 28|1@1+ (1,0) [0|0] "" Vector__XXX
 SG_ TRCM_a604_vrcmCurrentSourceTestSrxBroken m604 : 28|1@1+ (1,0) [0|0] "" Vector__XXX
 SG_ TRCM_a605_vrcmCurrentSourceTestSrxBroken m605 : 28|1@1+ (1,0) [0|0] "" Vector__XXX
 SG_ TRCM_a606_vrcmCurrentSourceTestSrxBroken m606 : 28|1@1+ (1,0) [0|0] "" Vector__XXX
 SG_ TRCM_a607_vrcmCurrentSourceTestSrxBroken m607 : 28|1@1+ (1,0) [0|0] "" Vector__XXX
 SG_ TRCM_a608_vrcmCurrentSourceTestSrxBroken m608 : 28|1@1+ (1,0) [0|0] "" Vector__XXX
 SG_ TRCM_a609_vrcmCurrentSourceTestSrxBroken m609 : 28|1@1+ (1,0) [0|0] "" Vector__XXX
 SG_ TRCM_a610_vrcmCurrentSourceTestSrxBroken m610 : 28|1@1+ (1,0) [0|0] "" Vector__XXX
 SG_ TRCM_a611_vrcmCurrentSourceTestSrxBroken m611 : 28|1@1+ (1,0) [0|0] "" Vector__XXX
 SG_ TRCM_a612_vrcmCurrentSourceTestSrxBroken m612 : 28|1@1+ (1,0) [0|0] "" Vector__XXX
 SG_ TRCM_a613_vrcmCurrentSourceTestSrxBroken m613 : 28|1@1+ (1,0) [0|0] "" Vector__XXX
 SG_ TRCM_a614_vrcmCurrentSourceTestSrxBroken m614 : 28|1@1+ (1,0) [0|0] "" Vector__XXX
 SG_ TRCM_a615_vrcmCurrentSourceTestSrxBroken m615 : 28|1@1+ (1,0) [0|0] "" Vector__XXX
 SG_ TRCM_a616_vrcmCurrentSourceTestSrxBroken m616 : 28|1@1+ (1,0) [0|0] "" Vector__XXX
 SG_ TRCM_a617_vrcmCurrentSourceTestSrxBroken m617 : 28|1@1+ (1,0) [0|0] "" Vector__XXX
 SG_ TRCM_a618_vrcmCurrentSourceTestSrxBroken m618 : 28|1@1+ (1,0) [0|0] "" Vector__XXX
 SG_ TRCM_a619_vrcmCurrentSourceTestSrxBroken m619 : 28|1@1+ (1,0) [0|0] "" Vector__XXX
 SG_ TRCM_a620_vrcmCurrentSourceTestSrxBroken m620 : 28|1@1+ (1,0) [0|0] "" Vector__XXX
 SG_ TRCM_a621_vrcmCurrentSourceTestSrxBroken m621 : 28|1@1+ (1,0) [0|0] "" Vector__XXX
 SG_ TRCM_a622_vrcmCurrentSourceTestSrxBroken m622 : 28|1@1+ (1,0) [0|0] "" Vector__XXX
 SG_ TRCM_a623_vrcmCurrentSourceTestSrxBroken m623 : 28|1@1+ (1,0) [0|0] "" Vector__XXX
 SG_ TRCM_a624_vrcmCurrentSourceTestSrxBroken m624 : 28|1@1+ (1,0) [0|0] "" Vector__XXX
 SG_ TRCM_a625_vrcmCurrentSourceTestSrxBroken m625 : 28|1@1+ (1,0) [0|0] "" Vector__XXX
 SG_ TRCM_a626_vrcmCurrentSourceTestSrxBroken m626 : 28|1@1+ (1,0) [0|0] "" Vector__XXX
 SG_ TRCM_a627_vrcmCurrentSourceTestSrxBroken m627 : 28|1@1+ (1,0) [0|0] "" Vector__XXX
 SG_ TRCM_a628_vrcmCurrentSourceTestSrxBroken m628 : 28|1@1+ (1,0) [0|0] "" Vector__XXX
 SG_ TRCM_a629_vrcmCurrentSourceTestSrxBroken m629 : 28|1@1+ (1,0) [0|0] "" Vector__XXX
 SG_ TRCM_a630_vrcmCurrentSourceTestSrxBroken m630 : 28|1@1+ (1,0) [0|0] "" Vector__XXX
 SG_ TRCM_a631_vrcmCurrentSourceTestSrxBroken m631 : 28|1@1+ (1,0) [0|0] "" Vector__XXX
 SG_ TRCM_a632_vrcmCurrentSourceTestSrxBroken m632 : 28|1@1+ (1,0) [0|0] "" Vector__XXX
 SG_ TRCM_a020_BG2_OK m20 : 29|1@1+ (1,0) [0|0] "" Vector__XXX
 SG_ TRCM_a023_Rotor_OK_X m23 : 29|1@1+ (1,0) [0|0] "" Vector__XXX
 SG_ TRCM_a040_ais2120State m40 : 29|4@1+ (1,0) [0|0] "" Vector__XXX
 SG_ TRCM_a098_VEH_motorStatus m98 : 29|1@1+ (1,0) [0|0] "" Vector__XXX
 SG_ TRCM_a104_VEH_steeringControl m104 : 29|1@1+ (1,0) [0|0] "" Vector__XXX
 SG_ TRCM_a107_VEH_chargeInfo m107 : 29|1@1+ (1,0) [0|0] "" Vector__XXX
 SG_ TRCM_a108_CH_torque m108 : 29|1@1+ (1,0) [0|0] "" Vector__XXX
 SG_ TRCM_a109_CH_inertial1 m109 : 29|1@1+ (1,0) [0|0] "" Vector__XXX
 SG_ TRCM_a110_CH_vin m110 : 29|1@1+ (1,0) [0|0] "" Vector__XXX
 SG_ TRCM_a113_VEH_driverProfileRecall m113 : 29|1@1+ (1,0) [0|0] "" Vector__XXX
 SG_ TRCM_a114_BDY_party3 m114 : 29|1@1+ (1,0) [0|0] "" Vector__XXX
 SG_ TRCM_a116_VEH_seatStatus2 m116 : 29|1@1+ (1,0) [0|0] "" Vector__XXX
 SG_ TRCM_a117_VEH_windowStatus m117 : 29|1@1+ (1,0) [0|0] "" Vector__XXX
 SG_ TRCM_a118_VEH_thermalCommand m118 : 29|1@1+ (1,0) [0|0] "" Vector__XXX
 SG_ TRCM_a120_VEH_aggregatedAxleSpeed m120 : 29|1@1+ (1,0) [0|0] "" Vector__XXX
 SG_ TRCM_a272_BG2_OK m272 : 29|1@1+ (1,0) [0|0] "" Vector__XXX
 SG_ TRCM_a273_Rotor_OK_X m273 : 29|1@1+ (1,0) [0|0] "" Vector__XXX
 SG_ TRCM_a274_Rotor_OK_Z m274 : 29|1@1+ (1,0) [0|0] "" Vector__XXX
 SG_ TRCM_a275_RotorBond_OK_ChY m275 : 29|1@1+ (1,0) [0|0] "" Vector__XXX
 SG_ TRCM_a389_satBuckUnderVoltage m389 : 29|1@1+ (1,0) [0|0] "" Vector__XXX
 SG_ TRCM_a394_BKG_MON_ERR m394 : 29|1@1+ (1,0) [0|0] "" Vector__XXX
 SG_ TRCM_a544_autarkyCurrentPathFailed m544 : 29|1@1+ (1,0) [0|0] "" Vector__XXX
 SG_ TRCM_a600_depAbistFailedError m600 : 29|1@1+ (1,0) [0|0] "" Vector__XXX
 SG_ TRCM_a601_vrcmCurrentSourceTestSfxStg m601 : 29|1@1+ (1,0) [0|0] "" Vector__XXX
 SG_ TRCM_a602_vrcmCurrentSourceTestSfxStg m602 : 29|1@1+ (1,0) [0|0] "" Vector__XXX
 SG_ TRCM_a603_vrcmCurrentSourceTestSfxStg m603 : 29|1@1+ (1,0) [0|0] "" Vector__XXX
 SG_ TRCM_a604_vrcmCurrentSourceTestSfxStg m604 : 29|1@1+ (1,0) [0|0] "" Vector__XXX
 SG_ TRCM_a605_vrcmCurrentSourceTestSfxStg m605 : 29|1@1+ (1,0) [0|0] "" Vector__XXX
 SG_ TRCM_a606_vrcmCurrentSourceTestSfxStg m606 : 29|1@1+ (1,0) [0|0] "" Vector__XXX
 SG_ TRCM_a607_vrcmCurrentSourceTestSfxStg m607 : 29|1@1+ (1,0) [0|0] "" Vector__XXX
 SG_ TRCM_a608_vrcmCurrentSourceTestSfxStg m608 : 29|1@1+ (1,0) [0|0] "" Vector__XXX
 SG_ TRCM_a609_vrcmCurrentSourceTestSfxStg m609 : 29|1@1+ (1,0) [0|0] "" Vector__XXX
 SG_ TRCM_a610_vrcmCurrentSourceTestSfxStg m610 : 29|1@1+ (1,0) [0|0] "" Vector__XXX
 SG_ TRCM_a611_vrcmCurrentSourceTestSfxStg m611 : 29|1@1+ (1,0) [0|0] "" Vector__XXX
 SG_ TRCM_a612_vrcmCurrentSourceTestSfxStg m612 : 29|1@1+ (1,0) [0|0] "" Vector__XXX
 SG_ TRCM_a613_vrcmCurrentSourceTestSfxStg m613 : 29|1@1+ (1,0) [0|0] "" Vector__XXX
 SG_ TRCM_a614_vrcmCurrentSourceTestSfxStg m614 : 29|1@1+ (1,0) [0|0] "" Vector__XXX
 SG_ TRCM_a615_vrcmCurrentSourceTestSfxStg m615 : 29|1@1+ (1,0) [0|0] "" Vector__XXX
 SG_ TRCM_a616_vrcmCurrentSourceTestSfxStg m616 : 29|1@1+ (1,0) [0|0] "" Vector__XXX
 SG_ TRCM_a617_vrcmCurrentSourceTestSfxStg m617 : 29|1@1+ (1,0) [0|0] "" Vector__XXX
 SG_ TRCM_a618_vrcmCurrentSourceTestSfxStg m618 : 29|1@1+ (1,0) [0|0] "" Vector__XXX
 SG_ TRCM_a619_vrcmCurrentSourceTestSfxStg m619 : 29|1@1+ (1,0) [0|0] "" Vector__XXX
 SG_ TRCM_a620_vrcmCurrentSourceTestSfxStg m620 : 29|1@1+ (1,0) [0|0] "" Vector__XXX
 SG_ TRCM_a621_vrcmCurrentSourceTestSfxStg m621 : 29|1@1+ (1,0) [0|0] "" Vector__XXX
 SG_ TRCM_a622_vrcmCurrentSourceTestSfxStg m622 : 29|1@1+ (1,0) [0|0] "" Vector__XXX
 SG_ TRCM_a623_vrcmCurrentSourceTestSfxStg m623 : 29|1@1+ (1,0) [0|0] "" Vector__XXX
 SG_ TRCM_a624_vrcmCurrentSourceTestSfxStg m624 : 29|1@1+ (1,0) [0|0] "" Vector__XXX
 SG_ TRCM_a625_vrcmCurrentSourceTestSfxStg m625 : 29|1@1+ (1,0) [0|0] "" Vector__XXX
 SG_ TRCM_a626_vrcmCurrentSourceTestSfxStg m626 : 29|1@1+ (1,0) [0|0] "" Vector__XXX
 SG_ TRCM_a627_vrcmCurrentSourceTestSfxStg m627 : 29|1@1+ (1,0) [0|0] "" Vector__XXX
 SG_ TRCM_a628_vrcmCurrentSourceTestSfxStg m628 : 29|1@1+ (1,0) [0|0] "" Vector__XXX
 SG_ TRCM_a629_vrcmCurrentSourceTestSfxStg m629 : 29|1@1+ (1,0) [0|0] "" Vector__XXX
 SG_ TRCM_a630_vrcmCurrentSourceTestSfxStg m630 : 29|1@1+ (1,0) [0|0] "" Vector__XXX
 SG_ TRCM_a631_vrcmCurrentSourceTestSfxStg m631 : 29|1@1+ (1,0) [0|0] "" Vector__XXX
 SG_ TRCM_a632_vrcmCurrentSourceTestSfxStg m632 : 29|1@1+ (1,0) [0|0] "" Vector__XXX
 SG_ TRCM_a020_Not_TestMode m20 : 30|1@1+ (1,0) [0|0] "" Vector__XXX
 SG_ TRCM_a023_SelfTestAuto_Rate_TC_OK_X m23 : 30|1@1+ (1,0) [0|0] "" Vector__XXX
 SG_ TRCM_a035_eventFrontLeftSeatbelt m35 : 30|1@1+ (1,0) [0|0] "" Vector__XXX
 SG_ TRCM_a036_eventFrontLeftSeatbelt m36 : 30|1@1+ (1,0) [0|0] "" Vector__XXX
 SG_ TRCM_a037_eventFrontLeftSeatbelt m37 : 30|1@1+ (1,0) [0|0] "" Vector__XXX
 SG_ TRCM_a081_eventFrontLeftSeatbelt m81 : 30|1@1+ (1,0) [0|0] "" Vector__XXX
 SG_ TRCM_a104_PARTY_integratedSafetyFront m104 : 30|1@1+ (1,0) [0|0] "" Vector__XXX
 SG_ TRCM_a109_CH_inertial2 m109 : 30|1@1+ (1,0) [0|0] "" Vector__XXX
 SG_ TRCM_a110_CH_chNm m110 : 30|1@1+ (1,0) [0|0] "" Vector__XXX
 SG_ TRCM_a113_VEH_driverProfileRecall2 m113 : 30|1@1+ (1,0) [0|0] "" Vector__XXX
 SG_ TRCM_a114_BDY_status m114 : 30|1@1+ (1,0) [0|0] "" Vector__XXX
 SG_ TRCM_a116_VEH_status m116 : 30|1@1+ (1,0) [0|0] "" Vector__XXX
 SG_ TRCM_a117_VEH_switchStatus m117 : 30|1@1+ (1,0) [0|0] "" Vector__XXX
 SG_ TRCM_a118_CH_LVPowerState m118 : 30|1@1+ (1,0) [0|0] "" Vector__XXX
 SG_ TRCM_a120_PARTY_aggregatedAxleSpeed m120 : 30|1@1+ (1,0) [0|0] "" Vector__XXX
 SG_ TRCM_a272_Not_TestMode m272 : 30|1@1+ (1,0) [0|0] "" Vector__XXX
 SG_ TRCM_a273_SelfTestAuto_Rate_TC_OK_X m273 : 30|1@1+ (1,0) [0|0] "" Vector__XXX
 SG_ TRCM_a274_SelfTestAuto_Rate_TC_OK_Z m274 : 30|1@1+ (1,0) [0|0] "" Vector__XXX
 SG_ TRCM_a275_RotorBond_OK_ChX m275 : 30|1@1+ (1,0) [0|0] "" Vector__XXX
 SG_ TRCM_a387_vccBuckOverVoltage m387 : 30|1@1+ (1,0) [0|0] "" Vector__XXX
 SG_ TRCM_a389_satBuckOverTemperature m389 : 30|1@1+ (1,0) [0|0] "" Vector__XXX
 SG_ TRCM_a394_NVM_ERR m394 : 30|1@1+ (1,0) [0|0] "" Vector__XXX
 SG_ TRCM_a544_erCapUnableToReachFullyChargedState m544 : 30|1@1+ (1,0) [0|0] "" Vector__XXX
 SG_ TRCM_a600_wdTestFailure m600 : 30|1@1+ (1,0) [0|0] "" Vector__XXX
 SG_ TRCM_a601_vrcmCurrentSourceTestSrxStb m601 : 30|1@1+ (1,0) [0|0] "" Vector__XXX
 SG_ TRCM_a602_vrcmCurrentSourceTestSrxStb m602 : 30|1@1+ (1,0) [0|0] "" Vector__XXX
 SG_ TRCM_a603_vrcmCurrentSourceTestSrxStb m603 : 30|1@1+ (1,0) [0|0] "" Vector__XXX
 SG_ TRCM_a604_vrcmCurrentSourceTestSrxStb m604 : 30|1@1+ (1,0) [0|0] "" Vector__XXX
 SG_ TRCM_a605_vrcmCurrentSourceTestSrxStb m605 : 30|1@1+ (1,0) [0|0] "" Vector__XXX
 SG_ TRCM_a606_vrcmCurrentSourceTestSrxStb m606 : 30|1@1+ (1,0) [0|0] "" Vector__XXX
 SG_ TRCM_a607_vrcmCurrentSourceTestSrxStb m607 : 30|1@1+ (1,0) [0|0] "" Vector__XXX
 SG_ TRCM_a608_vrcmCurrentSourceTestSrxStb m608 : 30|1@1+ (1,0) [0|0] "" Vector__XXX
 SG_ TRCM_a609_vrcmCurrentSourceTestSrxStb m609 : 30|1@1+ (1,0) [0|0] "" Vector__XXX
 SG_ TRCM_a610_vrcmCurrentSourceTestSrxStb m610 : 30|1@1+ (1,0) [0|0] "" Vector__XXX
 SG_ TRCM_a611_vrcmCurrentSourceTestSrxStb m611 : 30|1@1+ (1,0) [0|0] "" Vector__XXX
 SG_ TRCM_a612_vrcmCurrentSourceTestSrxStb m612 : 30|1@1+ (1,0) [0|0] "" Vector__XXX
 SG_ TRCM_a613_vrcmCurrentSourceTestSrxStb m613 : 30|1@1+ (1,0) [0|0] "" Vector__XXX
 SG_ TRCM_a614_vrcmCurrentSourceTestSrxStb m614 : 30|1@1+ (1,0) [0|0] "" Vector__XXX
 SG_ TRCM_a615_vrcmCurrentSourceTestSrxStb m615 : 30|1@1+ (1,0) [0|0] "" Vector__XXX
 SG_ TRCM_a616_vrcmCurrentSourceTestSrxStb m616 : 30|1@1+ (1,0) [0|0] "" Vector__XXX
 SG_ TRCM_a617_vrcmCurrentSourceTestSrxStb m617 : 30|1@1+ (1,0) [0|0] "" Vector__XXX
 SG_ TRCM_a618_vrcmCurrentSourceTestSrxStb m618 : 30|1@1+ (1,0) [0|0] "" Vector__XXX
 SG_ TRCM_a619_vrcmCurrentSourceTestSrxStb m619 : 30|1@1+ (1,0) [0|0] "" Vector__XXX
 SG_ TRCM_a620_vrcmCurrentSourceTestSrxStb m620 : 30|1@1+ (1,0) [0|0] "" Vector__XXX
 SG_ TRCM_a621_vrcmCurrentSourceTestSrxStb m621 : 30|1@1+ (1,0) [0|0] "" Vector__XXX
 SG_ TRCM_a622_vrcmCurrentSourceTestSrxStb m622 : 30|1@1+ (1,0) [0|0] "" Vector__XXX
 SG_ TRCM_a623_vrcmCurrentSourceTestSrxStb m623 : 30|1@1+ (1,0) [0|0] "" Vector__XXX
 SG_ TRCM_a624_vrcmCurrentSourceTestSrxStb m624 : 30|1@1+ (1,0) [0|0] "" Vector__XXX
 SG_ TRCM_a625_vrcmCurrentSourceTestSrxStb m625 : 30|1@1+ (1,0) [0|0] "" Vector__XXX
 SG_ TRCM_a626_vrcmCurrentSourceTestSrxStb m626 : 30|1@1+ (1,0) [0|0] "" Vector__XXX
 SG_ TRCM_a627_vrcmCurrentSourceTestSrxStb m627 : 30|1@1+ (1,0) [0|0] "" Vector__XXX
 SG_ TRCM_a628_vrcmCurrentSourceTestSrxStb m628 : 30|1@1+ (1,0) [0|0] "" Vector__XXX
 SG_ TRCM_a629_vrcmCurrentSourceTestSrxStb m629 : 30|1@1+ (1,0) [0|0] "" Vector__XXX
 SG_ TRCM_a630_vrcmCurrentSourceTestSrxStb m630 : 30|1@1+ (1,0) [0|0] "" Vector__XXX
 SG_ TRCM_a631_vrcmCurrentSourceTestSrxStb m631 : 30|1@1+ (1,0) [0|0] "" Vector__XXX
 SG_ TRCM_a632_vrcmCurrentSourceTestSrxStb m632 : 30|1@1+ (1,0) [0|0] "" Vector__XXX
 SG_ TRCM_a020_SelfTestAuto_SA_RBist_OK m20 : 31|1@1+ (1,0) [0|0] "" Vector__XXX
 SG_ TRCM_a023_Drive_Read_Chain_OK_X m23 : 31|1@1+ (1,0) [0|0] "" Vector__XXX
 SG_ TRCM_a035_eventFrontRightSeatbelt m35 : 31|1@1+ (1,0) [0|0] "" Vector__XXX
 SG_ TRCM_a036_eventFrontRightSeatbelt m36 : 31|1@1+ (1,0) [0|0] "" Vector__XXX
 SG_ TRCM_a037_eventFrontRightSeatbelt m37 : 31|1@1+ (1,0) [0|0] "" Vector__XXX
 SG_ TRCM_a081_eventFrontRightSeatbelt m81 : 31|1@1+ (1,0) [0|0] "" Vector__XXX
 SG_ TRCM_a104_PARTY_matrixBendAngleRequest m104 : 31|1@1+ (1,0) [0|0] "" Vector__XXX
 SG_ TRCM_a109_CH_status m109 : 31|1@1+ (1,0) [0|0] "" Vector__XXX
 SG_ TRCM_a110_CH_epochTimeGtw m110 : 31|1@1+ (1,0) [0|0] "" Vector__XXX
 SG_ TRCM_a113_VEH_ventCntlReg m113 : 31|1@1+ (1,0) [0|0] "" Vector__XXX
 SG_ TRCM_a114_BDY_wheelRotation m114 : 31|1@1+ (1,0) [0|0] "" Vector__XXX
 SG_ TRCM_a116_VEH_thermalCommand m116 : 31|1@1+ (1,0) [0|0] "" Vector__XXX
 SG_ TRCM_a117_VEH_intrusionSensorStatus m117 : 31|1@1+ (1,0) [0|0] "" Vector__XXX
 SG_ TRCM_a118_PARTY_sensors m118 : 31|1@1+ (1,0) [0|0] "" Vector__XXX
 SG_ TRCM_a120_VEH_systemPower m120 : 31|1@1+ (1,0) [0|0] "" Vector__XXX
 SG_ TRCM_a272_TS_Repeat_OK m272 : 31|1@1+ (1,0) [0|0] "" Vector__XXX
 SG_ TRCM_a273_Drive_Read_Chain_OK_X m273 : 31|1@1+ (1,0) [0|0] "" Vector__XXX
 SG_ TRCM_a274_Drive_Read_Chain_OK_Z m274 : 31|1@1+ (1,0) [0|0] "" Vector__XXX
 SG_ TRCM_a387_vccBuckUnderVoltageLow m387 : 31|1@1+ (1,0) [0|0] "" Vector__XXX
 SG_ TRCM_a389_vccBuckOverVoltage m389 : 31|1@1+ (1,0) [0|0] "" Vector__XXX
 SG_ TRCM_a394_SPIFLT m394 : 31|1@1+ (1,0) [0|0] "" Vector__XXX
 SG_ TRCM_a544_sysBoostAbnormalAfterAutarkyTest m544 : 31|1@1+ (1,0) [0|0] "" Vector__XXX
 SG_ TRCM_a600_wdDidNotStart m600 : 31|1@1+ (1,0) [0|0] "" Vector__XXX
 SG_ TRCM_a601_hsFetTestFailed m601 : 31|1@1+ (1,0) [0|0] "" Vector__XXX
 SG_ TRCM_a602_hsFetTestFailed m602 : 31|1@1+ (1,0) [0|0] "" Vector__XXX
 SG_ TRCM_a603_hsFetTestFailed m603 : 31|1@1+ (1,0) [0|0] "" Vector__XXX
 SG_ TRCM_a604_hsFetTestFailed m604 : 31|1@1+ (1,0) [0|0] "" Vector__XXX
 SG_ TRCM_a605_hsFetTestFailed m605 : 31|1@1+ (1,0) [0|0] "" Vector__XXX
 SG_ TRCM_a606_hsFetTestFailed m606 : 31|1@1+ (1,0) [0|0] "" Vector__XXX
 SG_ TRCM_a607_hsFetTestFailed m607 : 31|1@1+ (1,0) [0|0] "" Vector__XXX
 SG_ TRCM_a608_hsFetTestFailed m608 : 31|1@1+ (1,0) [0|0] "" Vector__XXX
 SG_ TRCM_a609_hsFetTestFailed m609 : 31|1@1+ (1,0) [0|0] "" Vector__XXX
 SG_ TRCM_a610_hsFetTestFailed m610 : 31|1@1+ (1,0) [0|0] "" Vector__XXX
 SG_ TRCM_a611_hsFetTestFailed m611 : 31|1@1+ (1,0) [0|0] "" Vector__XXX
 SG_ TRCM_a612_hsFetTestFailed m612 : 31|1@1+ (1,0) [0|0] "" Vector__XXX
 SG_ TRCM_a613_hsFetTestFailed m613 : 31|1@1+ (1,0) [0|0] "" Vector__XXX
 SG_ TRCM_a614_hsFetTestFailed m614 : 31|1@1+ (1,0) [0|0] "" Vector__XXX
 SG_ TRCM_a615_hsFetTestFailed m615 : 31|1@1+ (1,0) [0|0] "" Vector__XXX
 SG_ TRCM_a616_hsFetTestFailed m616 : 31|1@1+ (1,0) [0|0] "" Vector__XXX
 SG_ TRCM_a617_hsFetTestFailed m617 : 31|1@1+ (1,0) [0|0] "" Vector__XXX
 SG_ TRCM_a618_hsFetTestFailed m618 : 31|1@1+ (1,0) [0|0] "" Vector__XXX
 SG_ TRCM_a619_hsFetTestFailed m619 : 31|1@1+ (1,0) [0|0] "" Vector__XXX
 SG_ TRCM_a620_hsFetTestFailed m620 : 31|1@1+ (1,0) [0|0] "" Vector__XXX
 SG_ TRCM_a621_hsFetTestFailed m621 : 31|1@1+ (1,0) [0|0] "" Vector__XXX
 SG_ TRCM_a622_hsFetTestFailed m622 : 31|1@1+ (1,0) [0|0] "" Vector__XXX
 SG_ TRCM_a623_hsFetTestFailed m623 : 31|1@1+ (1,0) [0|0] "" Vector__XXX
 SG_ TRCM_a624_hsFetTestFailed m624 : 31|1@1+ (1,0) [0|0] "" Vector__XXX
 SG_ TRCM_a625_hsFetTestFailed m625 : 31|1@1+ (1,0) [0|0] "" Vector__XXX
 SG_ TRCM_a626_hsFetTestFailed m626 : 31|1@1+ (1,0) [0|0] "" Vector__XXX
 SG_ TRCM_a627_hsFetTestFailed m627 : 31|1@1+ (1,0) [0|0] "" Vector__XXX
 SG_ TRCM_a628_hsFetTestFailed m628 : 31|1@1+ (1,0) [0|0] "" Vector__XXX
 SG_ TRCM_a629_hsFetTestFailed m629 : 31|1@1+ (1,0) [0|0] "" Vector__XXX
 SG_ TRCM_a630_hsFetTestFailed m630 : 31|1@1+ (1,0) [0|0] "" Vector__XXX
 SG_ TRCM_a631_hsFetTestFailed m631 : 31|1@1+ (1,0) [0|0] "" Vector__XXX
 SG_ TRCM_a632_hsFetTestFailed m632 : 31|1@1+ (1,0) [0|0] "" Vector__XXX
 SG_ TRCM_a003_LineNumber m3 : 32|16@1+ (1,0) [0|0] "" Vector__XXX
 SG_ TRCM_a005_busID1 m5 : 32|4@1+ (1,0) [0|0] "" Vector__XXX
 SG_ TRCM_a006_messageID m6 : 32|29@1+ (1,0) [0|0] "" Vector__XXX
 SG_ TRCM_a007_expectedChecksum m7 : 32|16@1+ (1,0) [0|0] "" Vector__XXX
 SG_ TRCM_a008_expectedCounter m8 : 32|16@1+ (1,0) [0|0] "" Vector__XXX
 SG_ TRCM_a009_expectedChecksum m9 : 32|16@1+ (1,0) [0|0] "" Vector__XXX
 SG_ TRCM_a010_expectedCounter m10 : 32|16@1+ (1,0) [0|0] "" Vector__XXX
 SG_ TRCM_a016_NVMMRecordNotFound m16 : 32|1@1+ (1,0) [0|0] "" Vector__XXX
 SG_ TRCM_a020_VREGD_OK m20 : 32|1@1+ (1,0) [0|0] "" Vector__XXX
 SG_ TRCM_a022_TaskInitError1 m22 : 32|8@1+ (1,0) [0|0] "" Vector__XXX
 SG_ TRCM_a025_txErrCount m25 : 32|8@1+ (1,0) [0|0] "" Vector__XXX
 SG_ TRCM_a031_uds_bytes_2 m31 : 32|8@1+ (1,0) [0|0] "" Vector__XXX
 SG_ TRCM_a035_eventVehicleSpeed m35 : 32|12@1+ (0.08,-40) [0|0] "" Vector__XXX
 SG_ TRCM_a036_eventVehicleSpeed m36 : 32|12@1+ (0.08,-40) [0|0] "" Vector__XXX
 SG_ TRCM_a037_eventVehicleSpeed m37 : 32|12@1+ (0.08,-40) [0|0] "" Vector__XXX
 SG_ TRCM_a041_CPULoad10msTask m41 : 32|8@1+ (1,0) [0|0] "" Vector__XXX
 SG_ TRCM_a042_Usage100msTask m42 : 32|8@1+ (1,0) [0|0] "" Vector__XXX
 SG_ TRCM_a063_ADCVoltage m63 : 32|8@1+ (0.025,0) [0|0] "" Vector__XXX
 SG_ TRCM_a072_status1 m72 : 32|8@1+ (1,0) [0|0] "" Vector__XXX
 SG_ TRCM_a074_expected m74 : 32|16@1- (1,0) [0|0] "" Vector__XXX
 SG_ TRCM_a075_expected m75 : 32|16@1- (1,0) [0|0] "" Vector__XXX
 SG_ TRCM_a076_expected m76 : 32|16@1- (1,0) [0|0] "" Vector__XXX
 SG_ TRCM_a077_expected m77 : 32|16@1- (1,0) [0|0] "" Vector__XXX
 SG_ TRCM_a081_eventVehicleSpeed m81 : 32|12@1+ (0.08,-40) [0|0] "" Vector__XXX
 SG_ TRCM_a104_VEH_matrixHighBeamRequest m104 : 32|1@1+ (1,0) [0|0] "" Vector__XXX
 SG_ TRCM_a110_PARTY_carConfig m110 : 32|1@1+ (1,0) [0|0] "" Vector__XXX
 SG_ TRCM_a113_VEH_debugECU m113 : 32|1@1+ (1,0) [0|0] "" Vector__XXX
 SG_ TRCM_a114_BDY_wheelSpeeds m114 : 32|1@1+ (1,0) [0|0] "" Vector__XXX
 SG_ TRCM_a116_VEH_windowStatus m116 : 32|1@1+ (1,0) [0|0] "" Vector__XXX
 SG_ TRCM_a117_VEH_liftgateStatus m117 : 32|1@1+ (1,0) [0|0] "" Vector__XXX
 SG_ TRCM_a118_CH_sensors m118 : 32|1@1+ (1,0) [0|0] "" Vector__XXX
 SG_ TRCM_a120_PARTY_autonomyHealth m120 : 32|1@1+ (1,0) [0|0] "" Vector__XXX
 SG_ TRCM_a272_SelfTestAuto_SA_RBist_OK m272 : 32|1@1+ (1,0) [0|0] "" Vector__XXX
 SG_ TRCM_a387_vccBuckUnderVoltageHigh m387 : 32|1@1+ (1,0) [0|0] "" Vector__XXX
 SG_ TRCM_a389_vccBuckUnderVoltageLow m389 : 32|1@1+ (1,0) [0|0] "" Vector__XXX
 SG_ TRCM_a393_vrcmVoltage m393 : 32|9@1+ (0.05,0) [0|0] "" Vector__XXX
 SG_ TRCM_a394_firstErrorFrame m394 : 32|32@1+ (1,0) [0|0] "" Vector__XXX
 SG_ TRCM_a396_firstFrame m396 : 32|32@1+ (1,0) [0|0] "" Vector__XXX
 SG_ TRCM_a398_newAsicNvmValue m398 : 32|16@1+ (1,0) [0|0] "" Vector__XXX
 SG_ TRCM_a400_shortToGround m400 : 32|1@1+ (1,0) [0|0] "" Vector__XXX
 SG_ TRCM_a401_shortToGround m401 : 32|1@1+ (1,0) [0|0] "" Vector__XXX
 SG_ TRCM_a402_shortToGround m402 : 32|1@1+ (1,0) [0|0] "" Vector__XXX
 SG_ TRCM_a403_shortToGround m403 : 32|1@1+ (1,0) [0|0] "" Vector__XXX
 SG_ TRCM_a404_shortToGround m404 : 32|1@1+ (1,0) [0|0] "" Vector__XXX
 SG_ TRCM_a405_shortToGround m405 : 32|1@1+ (1,0) [0|0] "" Vector__XXX
 SG_ TRCM_a408_shortToGround m408 : 32|1@1+ (1,0) [0|0] "" Vector__XXX
 SG_ TRCM_a409_shortToGround m409 : 32|1@1+ (1,0) [0|0] "" Vector__XXX
 SG_ TRCM_a410_shortToGround m410 : 32|1@1+ (1,0) [0|0] "" Vector__XXX
 SG_ TRCM_a411_shortToGround m411 : 32|1@1+ (1,0) [0|0] "" Vector__XXX
 SG_ TRCM_a412_shortToGround m412 : 32|1@1+ (1,0) [0|0] "" Vector__XXX
 SG_ TRCM_a413_shortToGround m413 : 32|1@1+ (1,0) [0|0] "" Vector__XXX
 SG_ TRCM_a414_shortToGround m414 : 32|1@1+ (1,0) [0|0] "" Vector__XXX
 SG_ TRCM_a415_shortToGround m415 : 32|1@1+ (1,0) [0|0] "" Vector__XXX
 SG_ TRCM_a416_shortToGround m416 : 32|1@1+ (1,0) [0|0] "" Vector__XXX
 SG_ TRCM_a417_shortToGround m417 : 32|1@1+ (1,0) [0|0] "" Vector__XXX
 SG_ TRCM_a418_shortToGround m418 : 32|1@1+ (1,0) [0|0] "" Vector__XXX
 SG_ TRCM_a419_shortToGround m419 : 32|1@1+ (1,0) [0|0] "" Vector__XXX
 SG_ TRCM_a420_shortToGround m420 : 32|1@1+ (1,0) [0|0] "" Vector__XXX
 SG_ TRCM_a421_shortToGround m421 : 32|1@1+ (1,0) [0|0] "" Vector__XXX
 SG_ TRCM_a422_shortToGround m422 : 32|1@1+ (1,0) [0|0] "" Vector__XXX
 SG_ TRCM_a423_shortToGround m423 : 32|1@1+ (1,0) [0|0] "" Vector__XXX
 SG_ TRCM_a544_stateMachineFaulted m544 : 32|1@1+ (1,0) [0|0] "" Vector__XXX
 SG_ TRCM_a600_clockCtrlError m600 : 32|1@1+ (1,0) [0|0] "" Vector__XXX
 SG_ TRCM_a601_hsFetTestAborted m601 : 32|1@1+ (1,0) [0|0] "" Vector__XXX
 SG_ TRCM_a602_hsFetTestAborted m602 : 32|1@1+ (1,0) [0|0] "" Vector__XXX
 SG_ TRCM_a603_hsFetTestAborted m603 : 32|1@1+ (1,0) [0|0] "" Vector__XXX
 SG_ TRCM_a604_hsFetTestAborted m604 : 32|1@1+ (1,0) [0|0] "" Vector__XXX
 SG_ TRCM_a605_hsFetTestAborted m605 : 32|1@1+ (1,0) [0|0] "" Vector__XXX
 SG_ TRCM_a606_hsFetTestAborted m606 : 32|1@1+ (1,0) [0|0] "" Vector__XXX
 SG_ TRCM_a607_hsFetTestAborted m607 : 32|1@1+ (1,0) [0|0] "" Vector__XXX
 SG_ TRCM_a608_hsFetTestAborted m608 : 32|1@1+ (1,0) [0|0] "" Vector__XXX
 SG_ TRCM_a609_hsFetTestAborted m609 : 32|1@1+ (1,0) [0|0] "" Vector__XXX
 SG_ TRCM_a610_hsFetTestAborted m610 : 32|1@1+ (1,0) [0|0] "" Vector__XXX
 SG_ TRCM_a611_hsFetTestAborted m611 : 32|1@1+ (1,0) [0|0] "" Vector__XXX
 SG_ TRCM_a612_hsFetTestAborted m612 : 32|1@1+ (1,0) [0|0] "" Vector__XXX
 SG_ TRCM_a613_hsFetTestAborted m613 : 32|1@1+ (1,0) [0|0] "" Vector__XXX
 SG_ TRCM_a614_hsFetTestAborted m614 : 32|1@1+ (1,0) [0|0] "" Vector__XXX
 SG_ TRCM_a615_hsFetTestAborted m615 : 32|1@1+ (1,0) [0|0] "" Vector__XXX
 SG_ TRCM_a616_hsFetTestAborted m616 : 32|1@1+ (1,0) [0|0] "" Vector__XXX
 SG_ TRCM_a617_hsFetTestAborted m617 : 32|1@1+ (1,0) [0|0] "" Vector__XXX
 SG_ TRCM_a618_hsFetTestAborted m618 : 32|1@1+ (1,0) [0|0] "" Vector__XXX
 SG_ TRCM_a619_hsFetTestAborted m619 : 32|1@1+ (1,0) [0|0] "" Vector__XXX
 SG_ TRCM_a620_hsFetTestAborted m620 : 32|1@1+ (1,0) [0|0] "" Vector__XXX
 SG_ TRCM_a621_hsFetTestAborted m621 : 32|1@1+ (1,0) [0|0] "" Vector__XXX
 SG_ TRCM_a622_hsFetTestAborted m622 : 32|1@1+ (1,0) [0|0] "" Vector__XXX
 SG_ TRCM_a623_hsFetTestAborted m623 : 32|1@1+ (1,0) [0|0] "" Vector__XXX
 SG_ TRCM_a624_hsFetTestAborted m624 : 32|1@1+ (1,0) [0|0] "" Vector__XXX
 SG_ TRCM_a625_hsFetTestAborted m625 : 32|1@1+ (1,0) [0|0] "" Vector__XXX
 SG_ TRCM_a626_hsFetTestAborted m626 : 32|1@1+ (1,0) [0|0] "" Vector__XXX
 SG_ TRCM_a627_hsFetTestAborted m627 : 32|1@1+ (1,0) [0|0] "" Vector__XXX
 SG_ TRCM_a628_hsFetTestAborted m628 : 32|1@1+ (1,0) [0|0] "" Vector__XXX
 SG_ TRCM_a629_hsFetTestAborted m629 : 32|1@1+ (1,0) [0|0] "" Vector__XXX
 SG_ TRCM_a630_hsFetTestAborted m630 : 32|1@1+ (1,0) [0|0] "" Vector__XXX
 SG_ TRCM_a631_hsFetTestAborted m631 : 32|1@1+ (1,0) [0|0] "" Vector__XXX
 SG_ TRCM_a632_hsFetTestAborted m632 : 32|1@1+ (1,0) [0|0] "" Vector__XXX
 SG_ TRCM_a636_expectedRegisterValue m636 : 32|16@1+ (1,0) [0|0] "" Vector__XXX
 SG_ TRCM_a641_expectedRangeMax m641 : 32|8@1+ (1,0) [0|0] "" Vector__XXX
 SG_ TRCM_a016_NVMMCRCMismatch m16 : 33|1@1+ (1,0) [0|0] "" Vector__XXX
 SG_ TRCM_a020_VREGD_HIGH_OK m20 : 33|1@1+ (1,0) [0|0] "" Vector__XXX
 SG_ TRCM_a040_asm3State m40 : 33|4@1+ (1,0) [0|0] "" Vector__XXX
 SG_ TRCM_a104_VEH_summonCommand m104 : 33|1@1+ (1,0) [0|0] "" Vector__XXX
 SG_ TRCM_a113_VEH_status m113 : 33|1@1+ (1,0) [0|0] "" Vector__XXX
 SG_ TRCM_a114_CH_party1 m114 : 33|1@1+ (1,0) [0|0] "" Vector__XXX
 SG_ TRCM_a116_PARTY_restraintStatus m116 : 33|1@1+ (1,0) [0|0] "" Vector__XXX
 SG_ TRCM_a117_VEH_seatStatus2 m117 : 33|1@1+ (1,0) [0|0] "" Vector__XXX
 SG_ TRCM_a118_VEH_interNodeResistance m118 : 33|1@1+ (1,0) [0|0] "" Vector__XXX
 SG_ TRCM_a120_VEH_autonomyHealth m120 : 33|1@1+ (1,0) [0|0] "" Vector__XXX
 SG_ TRCM_a272_VREGD_OK m272 : 33|1@1+ (1,0) [0|0] "" Vector__XXX
 SG_ TRCM_a389_vccBuckUnderVoltageHigh m389 : 33|1@1+ (1,0) [0|0] "" Vector__XXX
 SG_ TRCM_a400_shortToBattery m400 : 33|1@1+ (1,0) [0|0] "" Vector__XXX
 SG_ TRCM_a401_shortToBattery m401 : 33|1@1+ (1,0) [0|0] "" Vector__XXX
 SG_ TRCM_a402_shortToBattery m402 : 33|1@1+ (1,0) [0|0] "" Vector__XXX
 SG_ TRCM_a403_shortToBattery m403 : 33|1@1+ (1,0) [0|0] "" Vector__XXX
 SG_ TRCM_a404_shortToBattery m404 : 33|1@1+ (1,0) [0|0] "" Vector__XXX
 SG_ TRCM_a405_shortToBattery m405 : 33|1@1+ (1,0) [0|0] "" Vector__XXX
 SG_ TRCM_a408_shortToBattery m408 : 33|1@1+ (1,0) [0|0] "" Vector__XXX
 SG_ TRCM_a409_shortToBattery m409 : 33|1@1+ (1,0) [0|0] "" Vector__XXX
 SG_ TRCM_a410_shortToBattery m410 : 33|1@1+ (1,0) [0|0] "" Vector__XXX
 SG_ TRCM_a411_shortToBattery m411 : 33|1@1+ (1,0) [0|0] "" Vector__XXX
 SG_ TRCM_a412_shortToBattery m412 : 33|1@1+ (1,0) [0|0] "" Vector__XXX
 SG_ TRCM_a413_shortToBattery m413 : 33|1@1+ (1,0) [0|0] "" Vector__XXX
 SG_ TRCM_a414_shortToBattery m414 : 33|1@1+ (1,0) [0|0] "" Vector__XXX
 SG_ TRCM_a415_shortToBattery m415 : 33|1@1+ (1,0) [0|0] "" Vector__XXX
 SG_ TRCM_a416_shortToBattery m416 : 33|1@1+ (1,0) [0|0] "" Vector__XXX
 SG_ TRCM_a417_shortToBattery m417 : 33|1@1+ (1,0) [0|0] "" Vector__XXX
 SG_ TRCM_a418_shortToBattery m418 : 33|1@1+ (1,0) [0|0] "" Vector__XXX
 SG_ TRCM_a419_shortToBattery m419 : 33|1@1+ (1,0) [0|0] "" Vector__XXX
 SG_ TRCM_a420_shortToBattery m420 : 33|1@1+ (1,0) [0|0] "" Vector__XXX
 SG_ TRCM_a421_shortToBattery m421 : 33|1@1+ (1,0) [0|0] "" Vector__XXX
 SG_ TRCM_a422_shortToBattery m422 : 33|1@1+ (1,0) [0|0] "" Vector__XXX
 SG_ TRCM_a423_shortToBattery m423 : 33|1@1+ (1,0) [0|0] "" Vector__XXX
 SG_ TRCM_a544_diagnosticFailureIsCritical m544 : 33|1@1+ (1,0) [0|0] "" Vector__XXX
 SG_ TRCM_a600_fllTimeoutError m600 : 33|1@1+ (1,0) [0|0] "" Vector__XXX
 SG_ TRCM_a601_lsFetTestFailed m601 : 33|1@1+ (1,0) [0|0] "" Vector__XXX
 SG_ TRCM_a602_lsFetTestFailed m602 : 33|1@1+ (1,0) [0|0] "" Vector__XXX
 SG_ TRCM_a603_lsFetTestFailed m603 : 33|1@1+ (1,0) [0|0] "" Vector__XXX
 SG_ TRCM_a604_lsFetTestFailed m604 : 33|1@1+ (1,0) [0|0] "" Vector__XXX
 SG_ TRCM_a605_lsFetTestFailed m605 : 33|1@1+ (1,0) [0|0] "" Vector__XXX
 SG_ TRCM_a606_lsFetTestFailed m606 : 33|1@1+ (1,0) [0|0] "" Vector__XXX
 SG_ TRCM_a607_lsFetTestFailed m607 : 33|1@1+ (1,0) [0|0] "" Vector__XXX
 SG_ TRCM_a608_lsFetTestFailed m608 : 33|1@1+ (1,0) [0|0] "" Vector__XXX
 SG_ TRCM_a609_lsFetTestFailed m609 : 33|1@1+ (1,0) [0|0] "" Vector__XXX
 SG_ TRCM_a610_lsFetTestFailed m610 : 33|1@1+ (1,0) [0|0] "" Vector__XXX
 SG_ TRCM_a611_lsFetTestFailed m611 : 33|1@1+ (1,0) [0|0] "" Vector__XXX
 SG_ TRCM_a612_lsFetTestFailed m612 : 33|1@1+ (1,0) [0|0] "" Vector__XXX
 SG_ TRCM_a613_lsFetTestFailed m613 : 33|1@1+ (1,0) [0|0] "" Vector__XXX
 SG_ TRCM_a614_lsFetTestFailed m614 : 33|1@1+ (1,0) [0|0] "" Vector__XXX
 SG_ TRCM_a615_lsFetTestFailed m615 : 33|1@1+ (1,0) [0|0] "" Vector__XXX
 SG_ TRCM_a616_lsFetTestFailed m616 : 33|1@1+ (1,0) [0|0] "" Vector__XXX
 SG_ TRCM_a617_lsFetTestFailed m617 : 33|1@1+ (1,0) [0|0] "" Vector__XXX
 SG_ TRCM_a618_lsFetTestFailed m618 : 33|1@1+ (1,0) [0|0] "" Vector__XXX
 SG_ TRCM_a619_lsFetTestFailed m619 : 33|1@1+ (1,0) [0|0] "" Vector__XXX
 SG_ TRCM_a620_lsFetTestFailed m620 : 33|1@1+ (1,0) [0|0] "" Vector__XXX
 SG_ TRCM_a621_lsFetTestFailed m621 : 33|1@1+ (1,0) [0|0] "" Vector__XXX
 SG_ TRCM_a622_lsFetTestFailed m622 : 33|1@1+ (1,0) [0|0] "" Vector__XXX
 SG_ TRCM_a623_lsFetTestFailed m623 : 33|1@1+ (1,0) [0|0] "" Vector__XXX
 SG_ TRCM_a624_lsFetTestFailed m624 : 33|1@1+ (1,0) [0|0] "" Vector__XXX
 SG_ TRCM_a625_lsFetTestFailed m625 : 33|1@1+ (1,0) [0|0] "" Vector__XXX
 SG_ TRCM_a626_lsFetTestFailed m626 : 33|1@1+ (1,0) [0|0] "" Vector__XXX
 SG_ TRCM_a627_lsFetTestFailed m627 : 33|1@1+ (1,0) [0|0] "" Vector__XXX
 SG_ TRCM_a628_lsFetTestFailed m628 : 33|1@1+ (1,0) [0|0] "" Vector__XXX
 SG_ TRCM_a629_lsFetTestFailed m629 : 33|1@1+ (1,0) [0|0] "" Vector__XXX
 SG_ TRCM_a630_lsFetTestFailed m630 : 33|1@1+ (1,0) [0|0] "" Vector__XXX
 SG_ TRCM_a631_lsFetTestFailed m631 : 33|1@1+ (1,0) [0|0] "" Vector__XXX
 SG_ TRCM_a632_lsFetTestFailed m632 : 33|1@1+ (1,0) [0|0] "" Vector__XXX
 SG_ TRCM_a016_NVMMVersionMismatch m16 : 34|1@1+ (1,0) [0|0] "" Vector__XXX
 SG_ TRCM_a020_VREGA_OK m20 : 34|1@1+ (1,0) [0|0] "" Vector__XXX
 SG_ TRCM_a104_VEH_status m104 : 34|1@1+ (1,0) [0|0] "" Vector__XXX
 SG_ TRCM_a113_VEH_elevationStatus m113 : 34|1@1+ (1,0) [0|0] "" Vector__XXX
 SG_ TRCM_a114_CH_party3 m114 : 34|1@1+ (1,0) [0|0] "" Vector__XXX
 SG_ TRCM_a116_PARTY_doorStatus m116 : 34|1@1+ (1,0) [0|0] "" Vector__XXX
 SG_ TRCM_a117_PARTY_restraintStatus m117 : 34|1@1+ (1,0) [0|0] "" Vector__XXX
 SG_ TRCM_a118_CH_lighting m118 : 34|1@1+ (1,0) [0|0] "" Vector__XXX
 SG_ TRCM_a120_PT_systemPower m120 : 34|1@1+ (1,0) [0|0] "" Vector__XXX
 SG_ TRCM_a272_VREGD_HIGH_OK m272 : 34|1@1+ (1,0) [0|0] "" Vector__XXX
 SG_ TRCM_a389_vccBuckGroundLoss m389 : 34|1@1+ (1,0) [0|0] "" Vector__XXX
 SG_ TRCM_a400_shortToSelf m400 : 34|1@1+ (1,0) [0|0] "" Vector__XXX
 SG_ TRCM_a401_shortToSelf m401 : 34|1@1+ (1,0) [0|0] "" Vector__XXX
 SG_ TRCM_a402_shortToSelf m402 : 34|1@1+ (1,0) [0|0] "" Vector__XXX
 SG_ TRCM_a403_shortToSelf m403 : 34|1@1+ (1,0) [0|0] "" Vector__XXX
 SG_ TRCM_a404_shortToSelf m404 : 34|1@1+ (1,0) [0|0] "" Vector__XXX
 SG_ TRCM_a405_shortToSelf m405 : 34|1@1+ (1,0) [0|0] "" Vector__XXX
 SG_ TRCM_a408_shortToSelf m408 : 34|1@1+ (1,0) [0|0] "" Vector__XXX
 SG_ TRCM_a409_shortToSelf m409 : 34|1@1+ (1,0) [0|0] "" Vector__XXX
 SG_ TRCM_a410_shortToSelf m410 : 34|1@1+ (1,0) [0|0] "" Vector__XXX
 SG_ TRCM_a411_shortToSelf m411 : 34|1@1+ (1,0) [0|0] "" Vector__XXX
 SG_ TRCM_a412_shortToSelf m412 : 34|1@1+ (1,0) [0|0] "" Vector__XXX
 SG_ TRCM_a413_shortToSelf m413 : 34|1@1+ (1,0) [0|0] "" Vector__XXX
 SG_ TRCM_a414_shortToSelf m414 : 34|1@1+ (1,0) [0|0] "" Vector__XXX
 SG_ TRCM_a415_shortToSelf m415 : 34|1@1+ (1,0) [0|0] "" Vector__XXX
 SG_ TRCM_a416_shortToSelf m416 : 34|1@1+ (1,0) [0|0] "" Vector__XXX
 SG_ TRCM_a417_shortToSelf m417 : 34|1@1+ (1,0) [0|0] "" Vector__XXX
 SG_ TRCM_a418_shortToSelf m418 : 34|1@1+ (1,0) [0|0] "" Vector__XXX
 SG_ TRCM_a419_shortToSelf m419 : 34|1@1+ (1,0) [0|0] "" Vector__XXX
 SG_ TRCM_a420_shortToSelf m420 : 34|1@1+ (1,0) [0|0] "" Vector__XXX
 SG_ TRCM_a421_shortToSelf m421 : 34|1@1+ (1,0) [0|0] "" Vector__XXX
 SG_ TRCM_a422_shortToSelf m422 : 34|1@1+ (1,0) [0|0] "" Vector__XXX
 SG_ TRCM_a423_shortToSelf m423 : 34|1@1+ (1,0) [0|0] "" Vector__XXX
 SG_ TRCM_a600_depCmdTestFailed m600 : 34|1@1+ (1,0) [0|0] "" Vector__XXX
 SG_ TRCM_a601_lsFetTestAborted m601 : 34|1@1+ (1,0) [0|0] "" Vector__XXX
 SG_ TRCM_a602_lsFetTestAborted m602 : 34|1@1+ (1,0) [0|0] "" Vector__XXX
 SG_ TRCM_a603_lsFetTestAborted m603 : 34|1@1+ (1,0) [0|0] "" Vector__XXX
 SG_ TRCM_a604_lsFetTestAborted m604 : 34|1@1+ (1,0) [0|0] "" Vector__XXX
 SG_ TRCM_a605_lsFetTestAborted m605 : 34|1@1+ (1,0) [0|0] "" Vector__XXX
 SG_ TRCM_a606_lsFetTestAborted m606 : 34|1@1+ (1,0) [0|0] "" Vector__XXX
 SG_ TRCM_a607_lsFetTestAborted m607 : 34|1@1+ (1,0) [0|0] "" Vector__XXX
 SG_ TRCM_a608_lsFetTestAborted m608 : 34|1@1+ (1,0) [0|0] "" Vector__XXX
 SG_ TRCM_a609_lsFetTestAborted m609 : 34|1@1+ (1,0) [0|0] "" Vector__XXX
 SG_ TRCM_a610_lsFetTestAborted m610 : 34|1@1+ (1,0) [0|0] "" Vector__XXX
 SG_ TRCM_a611_lsFetTestAborted m611 : 34|1@1+ (1,0) [0|0] "" Vector__XXX
 SG_ TRCM_a612_lsFetTestAborted m612 : 34|1@1+ (1,0) [0|0] "" Vector__XXX
 SG_ TRCM_a613_lsFetTestAborted m613 : 34|1@1+ (1,0) [0|0] "" Vector__XXX
 SG_ TRCM_a614_lsFetTestAborted m614 : 34|1@1+ (1,0) [0|0] "" Vector__XXX
 SG_ TRCM_a615_lsFetTestAborted m615 : 34|1@1+ (1,0) [0|0] "" Vector__XXX
 SG_ TRCM_a616_lsFetTestAborted m616 : 34|1@1+ (1,0) [0|0] "" Vector__XXX
 SG_ TRCM_a617_lsFetTestAborted m617 : 34|1@1+ (1,0) [0|0] "" Vector__XXX
 SG_ TRCM_a618_lsFetTestAborted m618 : 34|1@1+ (1,0) [0|0] "" Vector__XXX
 SG_ TRCM_a619_lsFetTestAborted m619 : 34|1@1+ (1,0) [0|0] "" Vector__XXX
 SG_ TRCM_a620_lsFetTestAborted m620 : 34|1@1+ (1,0) [0|0] "" Vector__XXX
 SG_ TRCM_a621_lsFetTestAborted m621 : 34|1@1+ (1,0) [0|0] "" Vector__XXX
 SG_ TRCM_a622_lsFetTestAborted m622 : 34|1@1+ (1,0) [0|0] "" Vector__XXX
 SG_ TRCM_a623_lsFetTestAborted m623 : 34|1@1+ (1,0) [0|0] "" Vector__XXX
 SG_ TRCM_a624_lsFetTestAborted m624 : 34|1@1+ (1,0) [0|0] "" Vector__XXX
 SG_ TRCM_a625_lsFetTestAborted m625 : 34|1@1+ (1,0) [0|0] "" Vector__XXX
 SG_ TRCM_a626_lsFetTestAborted m626 : 34|1@1+ (1,0) [0|0] "" Vector__XXX
 SG_ TRCM_a627_lsFetTestAborted m627 : 34|1@1+ (1,0) [0|0] "" Vector__XXX
 SG_ TRCM_a628_lsFetTestAborted m628 : 34|1@1+ (1,0) [0|0] "" Vector__XXX
 SG_ TRCM_a629_lsFetTestAborted m629 : 34|1@1+ (1,0) [0|0] "" Vector__XXX
 SG_ TRCM_a630_lsFetTestAborted m630 : 34|1@1+ (1,0) [0|0] "" Vector__XXX
 SG_ TRCM_a631_lsFetTestAborted m631 : 34|1@1+ (1,0) [0|0] "" Vector__XXX
 SG_ TRCM_a632_lsFetTestAborted m632 : 34|1@1+ (1,0) [0|0] "" Vector__XXX
 SG_ TRCM_a016_NVMMRecordUpgraded m16 : 35|1@1+ (1,0) [0|0] "" Vector__XXX
 SG_ TRCM_a020_VREGA_HIGH_OK m20 : 35|1@1+ (1,0) [0|0] "" Vector__XXX
 SG_ TRCM_a104_CH_pscControl m104 : 35|1@1+ (1,0) [0|0] "" Vector__XXX
 SG_ TRCM_a113_VEH_LVControl m113 : 35|1@1+ (1,0) [0|0] "" Vector__XXX
 SG_ TRCM_a114_CH_status m114 : 35|1@1+ (1,0) [0|0] "" Vector__XXX
 SG_ TRCM_a116_BDY_epbmStatus m116 : 35|1@1+ (1,0) [0|0] "" Vector__XXX
 SG_ TRCM_a117_VEH_thermalStatus m117 : 35|1@1+ (1,0) [0|0] "" Vector__XXX
 SG_ TRCM_a118_VEH_lightStatus m118 : 35|1@1+ (1,0) [0|0] "" Vector__XXX
 SG_ TRCM_a120_PARTY_stalklessInterfaces m120 : 35|1@1+ (1,0) [0|0] "" Vector__XXX
 SG_ TRCM_a272_VREGA_OK m272 : 35|1@1+ (1,0) [0|0] "" Vector__XXX
 SG_ TRCM_a389_vccBuckOverTemperature m389 : 35|1@1+ (1,0) [0|0] "" Vector__XXX
 SG_ TRCM_a400_openCircuit m400 : 35|1@1+ (1,0) [0|0] "" Vector__XXX
 SG_ TRCM_a401_openCircuit m401 : 35|1@1+ (1,0) [0|0] "" Vector__XXX
 SG_ TRCM_a402_openCircuit m402 : 35|1@1+ (1,0) [0|0] "" Vector__XXX
 SG_ TRCM_a403_openCircuit m403 : 35|1@1+ (1,0) [0|0] "" Vector__XXX
 SG_ TRCM_a404_openCircuit m404 : 35|1@1+ (1,0) [0|0] "" Vector__XXX
 SG_ TRCM_a405_openCircuit m405 : 35|1@1+ (1,0) [0|0] "" Vector__XXX
 SG_ TRCM_a408_openCircuit m408 : 35|1@1+ (1,0) [0|0] "" Vector__XXX
 SG_ TRCM_a409_openCircuit m409 : 35|1@1+ (1,0) [0|0] "" Vector__XXX
 SG_ TRCM_a410_openCircuit m410 : 35|1@1+ (1,0) [0|0] "" Vector__XXX
 SG_ TRCM_a411_openCircuit m411 : 35|1@1+ (1,0) [0|0] "" Vector__XXX
 SG_ TRCM_a412_openCircuit m412 : 35|1@1+ (1,0) [0|0] "" Vector__XXX
 SG_ TRCM_a413_openCircuit m413 : 35|1@1+ (1,0) [0|0] "" Vector__XXX
 SG_ TRCM_a414_openCircuit m414 : 35|1@1+ (1,0) [0|0] "" Vector__XXX
 SG_ TRCM_a415_openCircuit m415 : 35|1@1+ (1,0) [0|0] "" Vector__XXX
 SG_ TRCM_a416_openCircuit m416 : 35|1@1+ (1,0) [0|0] "" Vector__XXX
 SG_ TRCM_a417_openCircuit m417 : 35|1@1+ (1,0) [0|0] "" Vector__XXX
 SG_ TRCM_a418_openCircuit m418 : 35|1@1+ (1,0) [0|0] "" Vector__XXX
 SG_ TRCM_a419_openCircuit m419 : 35|1@1+ (1,0) [0|0] "" Vector__XXX
 SG_ TRCM_a420_openCircuit m420 : 35|1@1+ (1,0) [0|0] "" Vector__XXX
 SG_ TRCM_a421_openCircuit m421 : 35|1@1+ (1,0) [0|0] "" Vector__XXX
 SG_ TRCM_a422_openCircuit m422 : 35|1@1+ (1,0) [0|0] "" Vector__XXX
 SG_ TRCM_a423_openCircuit m423 : 35|1@1+ (1,0) [0|0] "" Vector__XXX
 SG_ TRCM_a600_depCmdNTestFailed m600 : 35|1@1+ (1,0) [0|0] "" Vector__XXX
 SG_ TRCM_a601_safingFetOffSsVoltageLow m601 : 35|1@1+ (1,0) [0|0] "" Vector__XXX
 SG_ TRCM_a602_safingFetOffSsVoltageLow m602 : 35|1@1+ (1,0) [0|0] "" Vector__XXX
 SG_ TRCM_a603_safingFetOffSsVoltageLow m603 : 35|1@1+ (1,0) [0|0] "" Vector__XXX
 SG_ TRCM_a604_safingFetOffSsVoltageLow m604 : 35|1@1+ (1,0) [0|0] "" Vector__XXX
 SG_ TRCM_a605_safingFetOffSsVoltageLow m605 : 35|1@1+ (1,0) [0|0] "" Vector__XXX
 SG_ TRCM_a606_safingFetOffSsVoltageLow m606 : 35|1@1+ (1,0) [0|0] "" Vector__XXX
 SG_ TRCM_a607_safingFetOffSsVoltageLow m607 : 35|1@1+ (1,0) [0|0] "" Vector__XXX
 SG_ TRCM_a608_safingFetOffSsVoltageLow m608 : 35|1@1+ (1,0) [0|0] "" Vector__XXX
 SG_ TRCM_a609_safingFetOffSsVoltageLow m609 : 35|1@1+ (1,0) [0|0] "" Vector__XXX
 SG_ TRCM_a610_safingFetOffSsVoltageLow m610 : 35|1@1+ (1,0) [0|0] "" Vector__XXX
 SG_ TRCM_a611_safingFetOffSsVoltageLow m611 : 35|1@1+ (1,0) [0|0] "" Vector__XXX
 SG_ TRCM_a612_safingFetOffSsVoltageLow m612 : 35|1@1+ (1,0) [0|0] "" Vector__XXX
 SG_ TRCM_a613_safingFetOffSsVoltageLow m613 : 35|1@1+ (1,0) [0|0] "" Vector__XXX
 SG_ TRCM_a614_safingFetOffSsVoltageLow m614 : 35|1@1+ (1,0) [0|0] "" Vector__XXX
 SG_ TRCM_a615_safingFetOffSsVoltageLow m615 : 35|1@1+ (1,0) [0|0] "" Vector__XXX
 SG_ TRCM_a616_safingFetOffSsVoltageLow m616 : 35|1@1+ (1,0) [0|0] "" Vector__XXX
 SG_ TRCM_a617_safingFetOffSsVoltageLow m617 : 35|1@1+ (1,0) [0|0] "" Vector__XXX
 SG_ TRCM_a618_safingFetOffSsVoltageLow m618 : 35|1@1+ (1,0) [0|0] "" Vector__XXX
 SG_ TRCM_a619_safingFetOffSsVoltageLow m619 : 35|1@1+ (1,0) [0|0] "" Vector__XXX
 SG_ TRCM_a620_safingFetOffSsVoltageLow m620 : 35|1@1+ (1,0) [0|0] "" Vector__XXX
 SG_ TRCM_a621_safingFetOffSsVoltageLow m621 : 35|1@1+ (1,0) [0|0] "" Vector__XXX
 SG_ TRCM_a622_safingFetOffSsVoltageLow m622 : 35|1@1+ (1,0) [0|0] "" Vector__XXX
 SG_ TRCM_a623_safingFetOffSsVoltageLow m623 : 35|1@1+ (1,0) [0|0] "" Vector__XXX
 SG_ TRCM_a624_safingFetOffSsVoltageLow m624 : 35|1@1+ (1,0) [0|0] "" Vector__XXX
 SG_ TRCM_a625_safingFetOffSsVoltageLow m625 : 35|1@1+ (1,0) [0|0] "" Vector__XXX
 SG_ TRCM_a626_safingFetOffSsVoltageLow m626 : 35|1@1+ (1,0) [0|0] "" Vector__XXX
 SG_ TRCM_a627_safingFetOffSsVoltageLow m627 : 35|1@1+ (1,0) [0|0] "" Vector__XXX
 SG_ TRCM_a628_safingFetOffSsVoltageLow m628 : 35|1@1+ (1,0) [0|0] "" Vector__XXX
 SG_ TRCM_a629_safingFetOffSsVoltageLow m629 : 35|1@1+ (1,0) [0|0] "" Vector__XXX
 SG_ TRCM_a630_safingFetOffSsVoltageLow m630 : 35|1@1+ (1,0) [0|0] "" Vector__XXX
 SG_ TRCM_a631_safingFetOffSsVoltageLow m631 : 35|1@1+ (1,0) [0|0] "" Vector__XXX
 SG_ TRCM_a632_safingFetOffSsVoltageLow m632 : 35|1@1+ (1,0) [0|0] "" Vector__XXX
 SG_ TRCM_a005_faults1 m5 : 36|12@1+ (1,0) [0|0] "" Vector__XXX
 SG_ TRCM_a016_NVMMMemOverflow m16 : 36|1@1+ (1,0) [0|0] "" Vector__XXX
 SG_ TRCM_a020_AVDD_OK m20 : 36|1@1+ (1,0) [0|0] "" Vector__XXX
 SG_ TRCM_a104_BDY_gpsAccuracies m104 : 36|1@1+ (1,0) [0|0] "" Vector__XXX
 SG_ TRCM_a113_CH_chassisControl m113 : 36|1@1+ (1,0) [0|0] "" Vector__XXX
 SG_ TRCM_a116_BDY_restraintStatus m116 : 36|1@1+ (1,0) [0|0] "" Vector__XXX
 SG_ TRCM_a117_PARTY_doorStatus m117 : 36|1@1+ (1,0) [0|0] "" Vector__XXX
 SG_ TRCM_a118_PARTY_vehNm m118 : 36|1@1+ (1,0) [0|0] "" Vector__XXX
 SG_ TRCM_a120_CH_speed m120 : 36|1@1+ (1,0) [0|0] "" Vector__XXX
 SG_ TRCM_a148_sensorParams m148 : 36|8@1+ (1,0) [0|0] "" Vector__XXX
 SG_ TRCM_a153_sensorParams m153 : 36|8@1+ (1,0) [0|0] "" Vector__XXX
 SG_ TRCM_a158_sensorParams m158 : 36|8@1+ (1,0) [0|0] "" Vector__XXX
 SG_ TRCM_a163_sensorParams m163 : 36|8@1+ (1,0) [0|0] "" Vector__XXX
 SG_ TRCM_a168_sensorParams m168 : 36|8@1+ (1,0) [0|0] "" Vector__XXX
 SG_ TRCM_a173_sensorParams m173 : 36|8@1+ (1,0) [0|0] "" Vector__XXX
 SG_ TRCM_a178_sensorParams m178 : 36|8@1+ (1,0) [0|0] "" Vector__XXX
 SG_ TRCM_a203_sensorParams m203 : 36|8@1+ (1,0) [0|0] "" Vector__XXX
 SG_ TRCM_a208_sensorParams m208 : 36|8@1+ (1,0) [0|0] "" Vector__XXX
 SG_ TRCM_a272_VREGA_HIGH_OK m272 : 36|1@1+ (1,0) [0|0] "" Vector__XXX
 SG_ TRCM_a389_vcoreOverVoltage m389 : 36|1@1+ (1,0) [0|0] "" Vector__XXX
 SG_ TRCM_a400_crossCoupled m400 : 36|1@1+ (1,0) [0|0] "" Vector__XXX
 SG_ TRCM_a401_crossCoupled m401 : 36|1@1+ (1,0) [0|0] "" Vector__XXX
 SG_ TRCM_a402_crossCoupled m402 : 36|1@1+ (1,0) [0|0] "" Vector__XXX
 SG_ TRCM_a403_crossCoupled m403 : 36|1@1+ (1,0) [0|0] "" Vector__XXX
 SG_ TRCM_a404_crossCoupled m404 : 36|1@1+ (1,0) [0|0] "" Vector__XXX
 SG_ TRCM_a405_crossCoupled m405 : 36|1@1+ (1,0) [0|0] "" Vector__XXX
 SG_ TRCM_a408_crossCoupled m408 : 36|1@1+ (1,0) [0|0] "" Vector__XXX
 SG_ TRCM_a409_crossCoupled m409 : 36|1@1+ (1,0) [0|0] "" Vector__XXX
 SG_ TRCM_a410_crossCoupled m410 : 36|1@1+ (1,0) [0|0] "" Vector__XXX
 SG_ TRCM_a411_crossCoupled m411 : 36|1@1+ (1,0) [0|0] "" Vector__XXX
 SG_ TRCM_a412_crossCoupled m412 : 36|1@1+ (1,0) [0|0] "" Vector__XXX
 SG_ TRCM_a413_crossCoupled m413 : 36|1@1+ (1,0) [0|0] "" Vector__XXX
 SG_ TRCM_a414_crossCoupled m414 : 36|1@1+ (1,0) [0|0] "" Vector__XXX
 SG_ TRCM_a415_crossCoupled m415 : 36|1@1+ (1,0) [0|0] "" Vector__XXX
 SG_ TRCM_a416_crossCoupled m416 : 36|1@1+ (1,0) [0|0] "" Vector__XXX
 SG_ TRCM_a417_crossCoupled m417 : 36|1@1+ (1,0) [0|0] "" Vector__XXX
 SG_ TRCM_a418_crossCoupled m418 : 36|1@1+ (1,0) [0|0] "" Vector__XXX
 SG_ TRCM_a419_crossCoupled m419 : 36|1@1+ (1,0) [0|0] "" Vector__XXX
 SG_ TRCM_a420_crossCoupled m420 : 36|1@1+ (1,0) [0|0] "" Vector__XXX
 SG_ TRCM_a421_crossCoupled m421 : 36|1@1+ (1,0) [0|0] "" Vector__XXX
 SG_ TRCM_a422_crossCoupled m422 : 36|1@1+ (1,0) [0|0] "" Vector__XXX
 SG_ TRCM_a423_crossCoupled m423 : 36|1@1+ (1,0) [0|0] "" Vector__XXX
 SG_ TRCM_a600_vrcmComparatorTestLeakDiagStg m600 : 36|1@1+ (1,0) [0|0] "" Vector__XXX
 SG_ TRCM_a601_safingFetOnSsVoltageLow m601 : 36|1@1+ (1,0) [0|0] "" Vector__XXX
 SG_ TRCM_a602_safingFetOnSsVoltageLow m602 : 36|1@1+ (1,0) [0|0] "" Vector__XXX
 SG_ TRCM_a603_safingFetOnSsVoltageLow m603 : 36|1@1+ (1,0) [0|0] "" Vector__XXX
 SG_ TRCM_a604_safingFetOnSsVoltageLow m604 : 36|1@1+ (1,0) [0|0] "" Vector__XXX
 SG_ TRCM_a605_safingFetOnSsVoltageLow m605 : 36|1@1+ (1,0) [0|0] "" Vector__XXX
 SG_ TRCM_a606_safingFetOnSsVoltageLow m606 : 36|1@1+ (1,0) [0|0] "" Vector__XXX
 SG_ TRCM_a607_safingFetOnSsVoltageLow m607 : 36|1@1+ (1,0) [0|0] "" Vector__XXX
 SG_ TRCM_a608_safingFetOnSsVoltageLow m608 : 36|1@1+ (1,0) [0|0] "" Vector__XXX
 SG_ TRCM_a609_safingFetOnSsVoltageLow m609 : 36|1@1+ (1,0) [0|0] "" Vector__XXX
 SG_ TRCM_a610_safingFetOnSsVoltageLow m610 : 36|1@1+ (1,0) [0|0] "" Vector__XXX
 SG_ TRCM_a611_safingFetOnSsVoltageLow m611 : 36|1@1+ (1,0) [0|0] "" Vector__XXX
 SG_ TRCM_a612_safingFetOnSsVoltageLow m612 : 36|1@1+ (1,0) [0|0] "" Vector__XXX
 SG_ TRCM_a613_safingFetOnSsVoltageLow m613 : 36|1@1+ (1,0) [0|0] "" Vector__XXX
 SG_ TRCM_a614_safingFetOnSsVoltageLow m614 : 36|1@1+ (1,0) [0|0] "" Vector__XXX
 SG_ TRCM_a615_safingFetOnSsVoltageLow m615 : 36|1@1+ (1,0) [0|0] "" Vector__XXX
 SG_ TRCM_a616_safingFetOnSsVoltageLow m616 : 36|1@1+ (1,0) [0|0] "" Vector__XXX
 SG_ TRCM_a617_safingFetOnSsVoltageLow m617 : 36|1@1+ (1,0) [0|0] "" Vector__XXX
 SG_ TRCM_a618_safingFetOnSsVoltageLow m618 : 36|1@1+ (1,0) [0|0] "" Vector__XXX
 SG_ TRCM_a619_safingFetOnSsVoltageLow m619 : 36|1@1+ (1,0) [0|0] "" Vector__XXX
 SG_ TRCM_a620_safingFetOnSsVoltageLow m620 : 36|1@1+ (1,0) [0|0] "" Vector__XXX
 SG_ TRCM_a621_safingFetOnSsVoltageLow m621 : 36|1@1+ (1,0) [0|0] "" Vector__XXX
 SG_ TRCM_a622_safingFetOnSsVoltageLow m622 : 36|1@1+ (1,0) [0|0] "" Vector__XXX
 SG_ TRCM_a623_safingFetOnSsVoltageLow m623 : 36|1@1+ (1,0) [0|0] "" Vector__XXX
 SG_ TRCM_a624_safingFetOnSsVoltageLow m624 : 36|1@1+ (1,0) [0|0] "" Vector__XXX
 SG_ TRCM_a625_safingFetOnSsVoltageLow m625 : 36|1@1+ (1,0) [0|0] "" Vector__XXX
 SG_ TRCM_a626_safingFetOnSsVoltageLow m626 : 36|1@1+ (1,0) [0|0] "" Vector__XXX
 SG_ TRCM_a627_safingFetOnSsVoltageLow m627 : 36|1@1+ (1,0) [0|0] "" Vector__XXX
 SG_ TRCM_a628_safingFetOnSsVoltageLow m628 : 36|1@1+ (1,0) [0|0] "" Vector__XXX
 SG_ TRCM_a629_safingFetOnSsVoltageLow m629 : 36|1@1+ (1,0) [0|0] "" Vector__XXX
 SG_ TRCM_a630_safingFetOnSsVoltageLow m630 : 36|1@1+ (1,0) [0|0] "" Vector__XXX
 SG_ TRCM_a631_safingFetOnSsVoltageLow m631 : 36|1@1+ (1,0) [0|0] "" Vector__XXX
 SG_ TRCM_a632_safingFetOnSsVoltageLow m632 : 36|1@1+ (1,0) [0|0] "" Vector__XXX
 SG_ TRCM_a016_NVMMWriteFailed m16 : 37|1@1+ (1,0) [0|0] "" Vector__XXX
 SG_ TRCM_a020_AVDD_HIGH_OK m20 : 37|1@1+ (1,0) [0|0] "" Vector__XXX
 SG_ TRCM_a040_asm5State m40 : 37|4@1+ (1,0) [0|0] "" Vector__XXX
 SG_ TRCM_a104_BDY_control m104 : 37|1@1+ (1,0) [0|0] "" Vector__XXX
 SG_ TRCM_a113_CH_powertrainControl m113 : 37|1@1+ (1,0) [0|0] "" Vector__XXX
 SG_ TRCM_a116_BDY_switchStatus m116 : 37|1@1+ (1,0) [0|0] "" Vector__XXX
 SG_ TRCM_a117_VEH_status m117 : 37|1@1+ (1,0) [0|0] "" Vector__XXX
 SG_ TRCM_a118_CH_12VBatteryStatus m118 : 37|1@1+ (1,0) [0|0] "" Vector__XXX
 SG_ TRCM_a120_VEH_estimatedBrakeTemp m120 : 37|1@1+ (1,0) [0|0] "" Vector__XXX
 SG_ TRCM_a272_AVDD_OK m272 : 37|1@1+ (1,0) [0|0] "" Vector__XXX
 SG_ TRCM_a389_vcoreUnderVoltage m389 : 37|1@1+ (1,0) [0|0] "" Vector__XXX
 SG_ TRCM_a400_resistanceOutOfSpec m400 : 37|1@1+ (1,0) [0|0] "" Vector__XXX
 SG_ TRCM_a401_resistanceOutOfSpec m401 : 37|1@1+ (1,0) [0|0] "" Vector__XXX
 SG_ TRCM_a402_resistanceOutOfSpec m402 : 37|1@1+ (1,0) [0|0] "" Vector__XXX
 SG_ TRCM_a403_resistanceOutOfSpec m403 : 37|1@1+ (1,0) [0|0] "" Vector__XXX
 SG_ TRCM_a404_resistanceOutOfSpec m404 : 37|1@1+ (1,0) [0|0] "" Vector__XXX
 SG_ TRCM_a405_resistanceOutOfSpec m405 : 37|1@1+ (1,0) [0|0] "" Vector__XXX
 SG_ TRCM_a408_resistanceOutOfSpec m408 : 37|1@1+ (1,0) [0|0] "" Vector__XXX
 SG_ TRCM_a409_resistanceOutOfSpec m409 : 37|1@1+ (1,0) [0|0] "" Vector__XXX
 SG_ TRCM_a410_resistanceOutOfSpec m410 : 37|1@1+ (1,0) [0|0] "" Vector__XXX
 SG_ TRCM_a411_resistanceOutOfSpec m411 : 37|1@1+ (1,0) [0|0] "" Vector__XXX
 SG_ TRCM_a412_resistanceOutOfSpec m412 : 37|1@1+ (1,0) [0|0] "" Vector__XXX
 SG_ TRCM_a413_resistanceOutOfSpec m413 : 37|1@1+ (1,0) [0|0] "" Vector__XXX
 SG_ TRCM_a414_resistanceOutOfSpec m414 : 37|1@1+ (1,0) [0|0] "" Vector__XXX
 SG_ TRCM_a415_resistanceOutOfSpec m415 : 37|1@1+ (1,0) [0|0] "" Vector__XXX
 SG_ TRCM_a416_resistanceOutOfSpec m416 : 37|1@1+ (1,0) [0|0] "" Vector__XXX
 SG_ TRCM_a417_resistanceOutOfSpec m417 : 37|1@1+ (1,0) [0|0] "" Vector__XXX
 SG_ TRCM_a418_resistanceOutOfSpec m418 : 37|1@1+ (1,0) [0|0] "" Vector__XXX
 SG_ TRCM_a419_resistanceOutOfSpec m419 : 37|1@1+ (1,0) [0|0] "" Vector__XXX
 SG_ TRCM_a420_resistanceOutOfSpec m420 : 37|1@1+ (1,0) [0|0] "" Vector__XXX
 SG_ TRCM_a421_resistanceOutOfSpec m421 : 37|1@1+ (1,0) [0|0] "" Vector__XXX
 SG_ TRCM_a422_resistanceOutOfSpec m422 : 37|1@1+ (1,0) [0|0] "" Vector__XXX
 SG_ TRCM_a423_resistanceOutOfSpec m423 : 37|1@1+ (1,0) [0|0] "" Vector__XXX
 SG_ TRCM_a600_vrcmComparatorTestLeakDiagStb m600 : 37|1@1+ (1,0) [0|0] "" Vector__XXX
 SG_ TRCM_a601_ssPinDisconnected m601 : 37|1@1+ (1,0) [0|0] "" Vector__XXX
 SG_ TRCM_a602_ssPinDisconnected m602 : 37|1@1+ (1,0) [0|0] "" Vector__XXX
 SG_ TRCM_a603_ssPinDisconnected m603 : 37|1@1+ (1,0) [0|0] "" Vector__XXX
 SG_ TRCM_a604_ssPinDisconnected m604 : 37|1@1+ (1,0) [0|0] "" Vector__XXX
 SG_ TRCM_a605_ssPinDisconnected m605 : 37|1@1+ (1,0) [0|0] "" Vector__XXX
 SG_ TRCM_a606_ssPinDisconnected m606 : 37|1@1+ (1,0) [0|0] "" Vector__XXX
 SG_ TRCM_a607_ssPinDisconnected m607 : 37|1@1+ (1,0) [0|0] "" Vector__XXX
 SG_ TRCM_a608_ssPinDisconnected m608 : 37|1@1+ (1,0) [0|0] "" Vector__XXX
 SG_ TRCM_a609_ssPinDisconnected m609 : 37|1@1+ (1,0) [0|0] "" Vector__XXX
 SG_ TRCM_a610_ssPinDisconnected m610 : 37|1@1+ (1,0) [0|0] "" Vector__XXX
 SG_ TRCM_a611_ssPinDisconnected m611 : 37|1@1+ (1,0) [0|0] "" Vector__XXX
 SG_ TRCM_a612_ssPinDisconnected m612 : 37|1@1+ (1,0) [0|0] "" Vector__XXX
 SG_ TRCM_a613_ssPinDisconnected m613 : 37|1@1+ (1,0) [0|0] "" Vector__XXX
 SG_ TRCM_a614_ssPinDisconnected m614 : 37|1@1+ (1,0) [0|0] "" Vector__XXX
 SG_ TRCM_a615_ssPinDisconnected m615 : 37|1@1+ (1,0) [0|0] "" Vector__XXX
 SG_ TRCM_a616_ssPinDisconnected m616 : 37|1@1+ (1,0) [0|0] "" Vector__XXX
 SG_ TRCM_a617_ssPinDisconnected m617 : 37|1@1+ (1,0) [0|0] "" Vector__XXX
 SG_ TRCM_a618_ssPinDisconnected m618 : 37|1@1+ (1,0) [0|0] "" Vector__XXX
 SG_ TRCM_a619_ssPinDisconnected m619 : 37|1@1+ (1,0) [0|0] "" Vector__XXX
 SG_ TRCM_a620_ssPinDisconnected m620 : 37|1@1+ (1,0) [0|0] "" Vector__XXX
 SG_ TRCM_a621_ssPinDisconnected m621 : 37|1@1+ (1,0) [0|0] "" Vector__XXX
 SG_ TRCM_a622_ssPinDisconnected m622 : 37|1@1+ (1,0) [0|0] "" Vector__XXX
 SG_ TRCM_a623_ssPinDisconnected m623 : 37|1@1+ (1,0) [0|0] "" Vector__XXX
 SG_ TRCM_a624_ssPinDisconnected m624 : 37|1@1+ (1,0) [0|0] "" Vector__XXX
 SG_ TRCM_a625_ssPinDisconnected m625 : 37|1@1+ (1,0) [0|0] "" Vector__XXX
 SG_ TRCM_a626_ssPinDisconnected m626 : 37|1@1+ (1,0) [0|0] "" Vector__XXX
 SG_ TRCM_a627_ssPinDisconnected m627 : 37|1@1+ (1,0) [0|0] "" Vector__XXX
 SG_ TRCM_a628_ssPinDisconnected m628 : 37|1@1+ (1,0) [0|0] "" Vector__XXX
 SG_ TRCM_a629_ssPinDisconnected m629 : 37|1@1+ (1,0) [0|0] "" Vector__XXX
 SG_ TRCM_a630_ssPinDisconnected m630 : 37|1@1+ (1,0) [0|0] "" Vector__XXX
 SG_ TRCM_a631_ssPinDisconnected m631 : 37|1@1+ (1,0) [0|0] "" Vector__XXX
 SG_ TRCM_a632_ssPinDisconnected m632 : 37|1@1+ (1,0) [0|0] "" Vector__XXX
 SG_ TRCM_a104_BDY_status m104 : 38|1@1+ (1,0) [0|0] "" Vector__XXX
 SG_ TRCM_a113_VEH_tripPlanning m113 : 38|1@1+ (1,0) [0|0] "" Vector__XXX
 SG_ TRCM_a117_PARTY_prndStatus m117 : 38|1@1+ (1,0) [0|0] "" Vector__XXX
 SG_ TRCM_a118_CH_LVBMS_statusHigh m118 : 38|1@1+ (1,0) [0|0] "" Vector__XXX
 SG_ TRCM_a120_PARTY_prndControl m120 : 38|1@1+ (1,0) [0|0] "" Vector__XXX
 SG_ TRCM_a272_AVDD_HIGH_OK m272 : 38|1@1+ (1,0) [0|0] "" Vector__XXX
 SG_ TRCM_a389_v5SenseOverVoltage m389 : 38|1@1+ (1,0) [0|0] "" Vector__XXX
 SG_ TRCM_a600_vrcmComparatorTestFetTestStg m600 : 38|1@1+ (1,0) [0|0] "" Vector__XXX
 SG_ TRCM_a601_hsFetFailedShortSuspected m601 : 38|1@1+ (1,0) [0|0] "" Vector__XXX
 SG_ TRCM_a602_hsFetFailedShortSuspected m602 : 38|1@1+ (1,0) [0|0] "" Vector__XXX
 SG_ TRCM_a603_hsFetFailedShortSuspected m603 : 38|1@1+ (1,0) [0|0] "" Vector__XXX
 SG_ TRCM_a604_hsFetFailedShortSuspected m604 : 38|1@1+ (1,0) [0|0] "" Vector__XXX
 SG_ TRCM_a605_hsFetFailedShortSuspected m605 : 38|1@1+ (1,0) [0|0] "" Vector__XXX
 SG_ TRCM_a606_hsFetFailedShortSuspected m606 : 38|1@1+ (1,0) [0|0] "" Vector__XXX
 SG_ TRCM_a607_hsFetFailedShortSuspected m607 : 38|1@1+ (1,0) [0|0] "" Vector__XXX
 SG_ TRCM_a608_hsFetFailedShortSuspected m608 : 38|1@1+ (1,0) [0|0] "" Vector__XXX
 SG_ TRCM_a609_hsFetFailedShortSuspected m609 : 38|1@1+ (1,0) [0|0] "" Vector__XXX
 SG_ TRCM_a610_hsFetFailedShortSuspected m610 : 38|1@1+ (1,0) [0|0] "" Vector__XXX
 SG_ TRCM_a611_hsFetFailedShortSuspected m611 : 38|1@1+ (1,0) [0|0] "" Vector__XXX
 SG_ TRCM_a612_hsFetFailedShortSuspected m612 : 38|1@1+ (1,0) [0|0] "" Vector__XXX
 SG_ TRCM_a613_hsFetFailedShortSuspected m613 : 38|1@1+ (1,0) [0|0] "" Vector__XXX
 SG_ TRCM_a614_hsFetFailedShortSuspected m614 : 38|1@1+ (1,0) [0|0] "" Vector__XXX
 SG_ TRCM_a615_hsFetFailedShortSuspected m615 : 38|1@1+ (1,0) [0|0] "" Vector__XXX
 SG_ TRCM_a616_hsFetFailedShortSuspected m616 : 38|1@1+ (1,0) [0|0] "" Vector__XXX
 SG_ TRCM_a617_hsFetFailedShortSuspected m617 : 38|1@1+ (1,0) [0|0] "" Vector__XXX
 SG_ TRCM_a618_hsFetFailedShortSuspected m618 : 38|1@1+ (1,0) [0|0] "" Vector__XXX
 SG_ TRCM_a619_hsFetFailedShortSuspected m619 : 38|1@1+ (1,0) [0|0] "" Vector__XXX
 SG_ TRCM_a620_hsFetFailedShortSuspected m620 : 38|1@1+ (1,0) [0|0] "" Vector__XXX
 SG_ TRCM_a621_hsFetFailedShortSuspected m621 : 38|1@1+ (1,0) [0|0] "" Vector__XXX
 SG_ TRCM_a622_hsFetFailedShortSuspected m622 : 38|1@1+ (1,0) [0|0] "" Vector__XXX
 SG_ TRCM_a623_hsFetFailedShortSuspected m623 : 38|1@1+ (1,0) [0|0] "" Vector__XXX
 SG_ TRCM_a624_hsFetFailedShortSuspected m624 : 38|1@1+ (1,0) [0|0] "" Vector__XXX
 SG_ TRCM_a625_hsFetFailedShortSuspected m625 : 38|1@1+ (1,0) [0|0] "" Vector__XXX
 SG_ TRCM_a626_hsFetFailedShortSuspected m626 : 38|1@1+ (1,0) [0|0] "" Vector__XXX
 SG_ TRCM_a627_hsFetFailedShortSuspected m627 : 38|1@1+ (1,0) [0|0] "" Vector__XXX
 SG_ TRCM_a628_hsFetFailedShortSuspected m628 : 38|1@1+ (1,0) [0|0] "" Vector__XXX
 SG_ TRCM_a629_hsFetFailedShortSuspected m629 : 38|1@1+ (1,0) [0|0] "" Vector__XXX
 SG_ TRCM_a630_hsFetFailedShortSuspected m630 : 38|1@1+ (1,0) [0|0] "" Vector__XXX
 SG_ TRCM_a631_hsFetFailedShortSuspected m631 : 38|1@1+ (1,0) [0|0] "" Vector__XXX
 SG_ TRCM_a632_hsFetFailedShortSuspected m632 : 38|1@1+ (1,0) [0|0] "" Vector__XXX
 SG_ TRCM_a058_prevREstimate m58 : 39|12@1+ (0.00061,0) [0|0] "" Vector__XXX
 SG_ TRCM_a104_PARTY_autonomyControl m104 : 39|1@1+ (1,0) [0|0] "" Vector__XXX
 SG_ TRCM_a113_VEH_vehicleControl3 m113 : 39|1@1+ (1,0) [0|0] "" Vector__XXX
 SG_ TRCM_a117_PARTY_lightingSecondary m117 : 39|1@1+ (1,0) [0|0] "" Vector__XXX
 SG_ TRCM_a118_CH_alertMatrix m118 : 39|1@1+ (1,0) [0|0] "" Vector__XXX
 SG_ TRCM_a120_PARTY_locStatus2 m120 : 39|1@1+ (1,0) [0|0] "" Vector__XXX
 SG_ TRCM_a389_v5SenseUnderVoltage m389 : 39|1@1+ (1,0) [0|0] "" Vector__XXX
 SG_ TRCM_a600_vrcmComparatorTestFetTestStb m600 : 39|1@1+ (1,0) [0|0] "" Vector__XXX
 SG_ TRCM_a022_TaskInitError2 m22 : 40|8@1+ (1,0) [0|0] "" Vector__XXX
 SG_ TRCM_a031_uds_bytes_3 m31 : 40|8@1+ (1,0) [0|0] "" Vector__XXX
 SG_ TRCM_a041_CPULoad100msTask m41 : 40|8@1+ (1,0) [0|0] "" Vector__XXX
 SG_ TRCM_a042_Usage1000msTask m42 : 40|8@1+ (1,0) [0|0] "" Vector__XXX
 SG_ TRCM_a043_CallTrace1 m43 : 40|24@1+ (1,0) [0|0] "" Vector__XXX
 SG_ TRCM_a044_CallTrace1 m44 : 40|24@1+ (1,0) [0|0] "" Vector__XXX
 SG_ TRCM_a045_CallTrace1 m45 : 40|24@1+ (1,0) [0|0] "" Vector__XXX
 SG_ TRCM_a046_CallTrace1 m46 : 40|24@1+ (1,0) [0|0] "" Vector__XXX
 SG_ TRCM_a059_current m59 : 40|12@1+ (0.05,0) [0|0] "" Vector__XXX
 SG_ TRCM_a063_disconnected m63 : 40|1@1+ (1,0) [0|0] "" Vector__XXX
 SG_ TRCM_a072_status2 m72 : 40|8@1+ (1,0) [0|0] "" Vector__XXX
 SG_ TRCM_a104_VEH_autonomyControl m104 : 40|1@1+ (1,0) [0|0] "" Vector__XXX
 SG_ TRCM_a113_VEH_vehicleControlThermal m113 : 40|1@1+ (1,0) [0|0] "" Vector__XXX
 SG_ TRCM_a118_BDY_outputPowerStatus m118 : 40|1@1+ (1,0) [0|0] "" Vector__XXX
 SG_ TRCM_a120_VEH_chassisCntl m120 : 40|1@1+ (1,0) [0|0] "" Vector__XXX
 SG_ TRCM_a146_frameData m146 : 40|16@1+ (1,0) [0|0] "" Vector__XXX
 SG_ TRCM_a151_frameData m151 : 40|16@1+ (1,0) [0|0] "" Vector__XXX
 SG_ TRCM_a156_frameData m156 : 40|16@1+ (1,0) [0|0] "" Vector__XXX
 SG_ TRCM_a161_frameData m161 : 40|16@1+ (1,0) [0|0] "" Vector__XXX
 SG_ TRCM_a166_frameData m166 : 40|16@1+ (1,0) [0|0] "" Vector__XXX
 SG_ TRCM_a171_frameData m171 : 40|16@1+ (1,0) [0|0] "" Vector__XXX
 SG_ TRCM_a176_frameData m176 : 40|16@1+ (1,0) [0|0] "" Vector__XXX
 SG_ TRCM_a201_frameData m201 : 40|16@1+ (1,0) [0|0] "" Vector__XXX
 SG_ TRCM_a206_frameData m206 : 40|16@1+ (1,0) [0|0] "" Vector__XXX
 SG_ TRCM_a389_inErState m389 : 40|1@1+ (1,0) [0|0] "" Vector__XXX
 SG_ TRCM_a600_adcRatioReadIncomplete m600 : 40|1@1+ (1,0) [0|0] "" Vector__XXX
 SG_ TRCM_a634_obtainedRegisterValueSigned m634 : 40|16@1- (1,0) [0|0] "" Vector__XXX
 SG_ TRCM_a635_obtainedRegisterValueSigned m635 : 40|16@1- (1,0) [0|0] "" Vector__XXX
 SG_ TRCM_a637_expectedRegisterValue m637 : 40|16@1+ (1,0) [0|0] "" Vector__XXX
 SG_ TRCM_a640_targetValue m640 : 40|16@1- (1,0) [0|0] "" Vector__XXX
 SG_ TRCM_a040_erCapState m40 : 41|5@1+ (1,0) [0|0] "" Vector__XXX
 SG_ TRCM_a063_indeterminate m63 : 41|1@1+ (1,0) [0|0] "" Vector__XXX
 SG_ TRCM_a104_CH_autonomyControl m104 : 41|1@1+ (1,0) [0|0] "" Vector__XXX
 SG_ TRCM_a113_CH_odo m113 : 41|1@1+ (1,0) [0|0] "" Vector__XXX
 SG_ TRCM_a118_BDY_vehicleTime m118 : 41|1@1+ (1,0) [0|0] "" Vector__XXX
 SG_ TRCM_a120_CH_locStatus2 m120 : 41|1@1+ (1,0) [0|0] "" Vector__XXX
 SG_ TRCM_a389_v5SenseShortToGround m389 : 41|1@1+ (1,0) [0|0] "" Vector__XXX
 SG_ TRCM_a393_asicDevice m393 : 41|2@1+ (1,0) [0|0] "" Vector__XXX
 SG_ TRCM_a600_adcRatioMismatch m600 : 41|1@1+ (1,0) [0|0] "" Vector__XXX
 SG_ TRCM_a063_stuckActive m63 : 42|1@1+ (1,0) [0|0] "" Vector__XXX
 SG_ TRCM_a104_BDY_autonomyControl m104 : 42|1@1+ (1,0) [0|0] "" Vector__XXX
 SG_ TRCM_a113_VEH_locationStatus m113 : 42|1@1+ (1,0) [0|0] "" Vector__XXX
 SG_ TRCM_a118_PARTY_AP_vehicleState1HzMuxed m118 : 42|1@1+ (1,0) [0|0] "" Vector__XXX
 SG_ TRCM_a120_VEH_locStatus m120 : 42|1@1+ (1,0) [0|0] "" Vector__XXX
 SG_ TRCM_a389_erBoostOnDeasserted m389 : 42|1@1+ (1,0) [0|0] "" Vector__XXX
 SG_ TRCM_a600_hsLsFetTestsSkipped m600 : 42|1@1+ (1,0) [0|0] "" Vector__XXX
 SG_ TRCM_a063_faulted m63 : 43|1@1+ (1,0) [0|0] "" Vector__XXX
 SG_ TRCM_a104_VEH_wirelessChargingStatus m104 : 43|1@1+ (1,0) [0|0] "" Vector__XXX
 SG_ TRCM_a113_VEH_gpsTime m113 : 43|1@1+ (1,0) [0|0] "" Vector__XXX
 SG_ TRCM_a118_BDY_AP_vehicleState1HzMuxed m118 : 43|1@1+ (1,0) [0|0] "" Vector__XXX
 SG_ TRCM_a120_VEH_locStatus2 m120 : 43|1@1+ (1,0) [0|0] "" Vector__XXX
 SG_ TRCM_a389_erChargeSwitchOnDeasserted m389 : 43|1@1+ (1,0) [0|0] "" Vector__XXX
 SG_ TRCM_a600_safingFetTestSkipped m600 : 43|1@1+ (1,0) [0|0] "" Vector__XXX
 SG_ TRCM_a104_VEH_control m104 : 44|1@1+ (1,0) [0|0] "" Vector__XXX
 SG_ TRCM_a113_VEH_gpsVehicleSpeed m113 : 44|1@1+ (1,0) [0|0] "" Vector__XXX
 SG_ TRCM_a118_PARTY_VCFRONT_cameraCleaningStatus m118 : 44|1@1+ (1,0) [0|0] "" Vector__XXX
 SG_ TRCM_a120_VEH_prndControl m120 : 44|1@1+ (1,0) [0|0] "" Vector__XXX
 SG_ TRCM_a148_manufacturerId m148 : 44|8@1+ (1,0) [0|0] "" Vector__XXX
 SG_ TRCM_a153_manufacturerId m153 : 44|8@1+ (1,0) [0|0] "" Vector__XXX
 SG_ TRCM_a158_manufacturerId m158 : 44|8@1+ (1,0) [0|0] "" Vector__XXX
 SG_ TRCM_a163_manufacturerId m163 : 44|8@1+ (1,0) [0|0] "" Vector__XXX
 SG_ TRCM_a168_manufacturerId m168 : 44|8@1+ (1,0) [0|0] "" Vector__XXX
 SG_ TRCM_a173_manufacturerId m173 : 44|8@1+ (1,0) [0|0] "" Vector__XXX
 SG_ TRCM_a178_manufacturerId m178 : 44|8@1+ (1,0) [0|0] "" Vector__XXX
 SG_ TRCM_a203_manufacturerId m203 : 44|8@1+ (1,0) [0|0] "" Vector__XXX
 SG_ TRCM_a208_manufacturerId m208 : 44|8@1+ (1,0) [0|0] "" Vector__XXX
 SG_ TRCM_a389_erDischargeSwitchOn m389 : 44|1@1+ (1,0) [0|0] "" Vector__XXX
 SG_ TRCM_a600_safingFetAdcReadIncomplete m600 : 44|1@1+ (1,0) [0|0] "" Vector__XXX
 SG_ TRCM_a104_VEH_redundantBrakingControl m104 : 45|1@1+ (1,0) [0|0] "" Vector__XXX
 SG_ TRCM_a113_VEH_status2 m113 : 45|1@1+ (1,0) [0|0] "" Vector__XXX
 SG_ TRCM_a120_VEH_vehicleEstimates m120 : 45|1@1+ (1,0) [0|0] "" Vector__XXX
 SG_ TRCM_a389_erSwOn m389 : 45|1@1+ (1,0) [0|0] "" Vector__XXX
 SG_ TRCM_a600_safingFetBypassSupplyVoltageLow m600 : 45|1@1+ (1,0) [0|0] "" Vector__XXX
 SG_ TRCM_a040_normalNvmStatus m40 : 46|2@1+ (1,0) [0|0] "" Vector__XXX
 SG_ TRCM_a104_BDY_bodyControls m104 : 46|1@1+ (1,0) [0|0] "" Vector__XXX
 SG_ TRCM_a113_VEH_autopilotControl m113 : 46|1@1+ (1,0) [0|0] "" Vector__XXX
 SG_ TRCM_a120_PARTY_motorStatus m120 : 46|1@1+ (1,0) [0|0] "" Vector__XXX
 SG_ TRCM_a389_sysBoostOnDeasserted m389 : 46|1@1+ (1,0) [0|0] "" Vector__XXX
 SG_ TRCM_a600_safingFetAsicAndMcuAdcsMismatch m600 : 46|1@1+ (1,0) [0|0] "" Vector__XXX
 SG_ TRCM_a113_VEH_ambientLightingCtrls m113 : 47|1@1+ (1,0) [0|0] "" Vector__XXX
 SG_ TRCM_a120_VEH_motorStatus m120 : 47|1@1+ (1,0) [0|0] "" Vector__XXX
 SG_ TRCM_a389_satBuckOnDeasserted m389 : 47|1@1+ (1,0) [0|0] "" Vector__XXX
 SG_ TRCM_a600_safingFetOffCheckFailed m600 : 47|1@1+ (1,0) [0|0] "" Vector__XXX
 SG_ TRCM_a003_Data m3 : 48|16@1+ (1,0) [0|0] "" Vector__XXX
 SG_ TRCM_a007_receivedChecksum m7 : 48|16@1+ (1,0) [0|0] "" Vector__XXX
 SG_ TRCM_a008_receivedCounter m8 : 48|16@1+ (1,0) [0|0] "" Vector__XXX
 SG_ TRCM_a009_receivedChecksum m9 : 48|16@1+ (1,0) [0|0] "" Vector__XXX
 SG_ TRCM_a010_receivedCounter m10 : 48|16@1+ (1,0) [0|0] "" Vector__XXX
 SG_ TRCM_a022_TaskInitError3 m22 : 48|8@1+ (1,0) [0|0] "" Vector__XXX
 SG_ TRCM_a031_uds_bytes_4 m31 : 48|8@1+ (1,0) [0|0] "" Vector__XXX
 SG_ TRCM_a032_timeTickSinceCreated m32 : 48|16@1+ (1,0) [0|0] "" Vector__XXX
 SG_ TRCM_a033_timeTickSinceCreated m33 : 48|16@1+ (1,0) [0|0] "" Vector__XXX
 SG_ TRCM_a035_eventDriverBrakeApply m35 : 48|2@1+ (1,0) [0|0] "" Vector__XXX
 SG_ TRCM_a036_eventDriverBrakeApply m36 : 48|2@1+ (1,0) [0|0] "" Vector__XXX
 SG_ TRCM_a037_eventDriverBrakeApply m37 : 48|2@1+ (1,0) [0|0] "" Vector__XXX
 SG_ TRCM_a040_criticalNvmStatus m40 : 48|2@1+ (1,0) [0|0] "" Vector__XXX
 SG_ TRCM_a041_CPULoad1000msTask m41 : 48|8@1+ (1,0) [0|0] "" Vector__XXX
 SG_ TRCM_a042_UsageUDSTask m42 : 48|8@1+ (1,0) [0|0] "" Vector__XXX
 SG_ TRCM_a072_resetRetryCount m72 : 48|8@1+ (1,0) [0|0] "" Vector__XXX
 SG_ TRCM_a081_eventDriverBrakeApply m81 : 48|2@1+ (1,0) [0|0] "" Vector__XXX
 SG_ TRCM_a113_VEH_driverAssistMapData m113 : 48|1@1+ (1,0) [0|0] "" Vector__XXX
 SG_ TRCM_a120_BDY_speed m120 : 48|1@1+ (1,0) [0|0] "" Vector__XXX
 SG_ TRCM_a389_vccBuckOnDeasserted m389 : 48|1@1+ (1,0) [0|0] "" Vector__XXX
 SG_ TRCM_a600_safingFetOffSsVoltageHigh m600 : 48|1@1+ (1,0) [0|0] "" Vector__XXX
 SG_ TRCM_a113_CH_vehicleControl2 m113 : 49|1@1+ (1,0) [0|0] "" Vector__XXX
 SG_ TRCM_a389_vsf1Enabled m389 : 49|1@1+ (1,0) [0|0] "" Vector__XXX
 SG_ TRCM_a600_safingFetOnFetCheckFailed m600 : 49|1@1+ (1,0) [0|0] "" Vector__XXX
 SG_ TRCM_a040_numberOfTick m40 : 50|14@1+ (1,0) [0|0] "" Vector__XXX
 SG_ TRCM_a113_VEH_odo m113 : 50|1@1+ (1,0) [0|0] "" Vector__XXX
 SG_ TRCM_a389_vsf2Enabled m389 : 50|1@1+ (1,0) [0|0] "" Vector__XXX
 SG_ TRCM_a600_safingFetOnSsVoltageHigh m600 : 50|1@1+ (1,0) [0|0] "" Vector__XXX
 SG_ TRCM_a058_newREstimate m58 : 51|12@1+ (0.00061,0) [0|0] "" Vector__XXX
 SG_ TRCM_a389_wakeUpStatusDeasserted m389 : 51|1@1+ (1,0) [0|0] "" Vector__XXX
 SG_ TRCM_a600_safingFetMcuInhibitCheckFailed m600 : 51|1@1+ (1,0) [0|0] "" Vector__XXX
 SG_ TRCM_a148_sensorType m148 : 52|8@1+ (1,0) [0|0] "" Vector__XXX
 SG_ TRCM_a153_sensorType m153 : 52|8@1+ (1,0) [0|0] "" Vector__XXX
 SG_ TRCM_a158_sensorType m158 : 52|8@1+ (1,0) [0|0] "" Vector__XXX
 SG_ TRCM_a163_sensorType m163 : 52|8@1+ (1,0) [0|0] "" Vector__XXX
 SG_ TRCM_a168_sensorType m168 : 52|8@1+ (1,0) [0|0] "" Vector__XXX
 SG_ TRCM_a173_sensorType m173 : 52|8@1+ (1,0) [0|0] "" Vector__XXX
 SG_ TRCM_a178_sensorType m178 : 52|8@1+ (1,0) [0|0] "" Vector__XXX
 SG_ TRCM_a203_sensorType m203 : 52|8@1+ (1,0) [0|0] "" Vector__XXX
 SG_ TRCM_a208_sensorType m208 : 52|8@1+ (1,0) [0|0] "" Vector__XXX
 SG_ TRCM_a389_vBatMonStatusDeasserted m389 : 52|1@1+ (1,0) [0|0] "" Vector__XXX
 SG_ TRCM_a600_backgroundMonitorSafCrcRecalcFailed m600 : 52|1@1+ (1,0) [0|0] "" Vector__XXX
 SG_ TRCM_a389_vinGoodDeasserted m389 : 53|1@1+ (1,0) [0|0] "" Vector__XXX
 SG_ TRCM_a600_backgroundMonitorDepCrcRecalcFailed m600 : 53|1@1+ (1,0) [0|0] "" Vector__XXX
 SG_ TRCM_a389_vinBadAsserted m389 : 54|1@1+ (1,0) [0|0] "" Vector__XXX
 SG_ TRCM_a600_backgroundMonitorGswSetAfterCrcRecalc m600 : 54|1@1+ (1,0) [0|0] "" Vector__XXX
 SG_ TRCM_a389_vcoreError m389 : 55|1@1+ (1,0) [0|0] "" Vector__XXX
 SG_ TRCM_a600_sysAsicHasFailure m600 : 55|1@1+ (1,0) [0|0] "" Vector__XXX
 SG_ TRCM_a022_TaskInitError4 m22 : 56|8@1+ (1,0) [0|0] "" Vector__XXX
 SG_ TRCM_a031_uds_bytes_5 m31 : 56|8@1+ (1,0) [0|0] "" Vector__XXX
 SG_ TRCM_a035_eventAccelPedalPos m35 : 56|8@1+ (0.4,0) [0|0] "" Vector__XXX
 SG_ TRCM_a036_eventAccelPedalPos m36 : 56|8@1+ (0.4,0) [0|0] "" Vector__XXX
 SG_ TRCM_a037_eventAccelPedalPos m37 : 56|8@1+ (0.4,0) [0|0] "" Vector__XXX
 SG_ TRCM_a041_CPULoadNVMMTask m41 : 56|8@1+ (1,0) [0|0] "" Vector__XXX
 SG_ TRCM_a042_UsageNVMMTask m42 : 56|8@1+ (1,0) [0|0] "" Vector__XXX
 SG_ TRCM_a081_eventAccelPedalPos m81 : 56|8@1+ (0.4,0) [0|0] "" Vector__XXX
 SG_ TRCM_a389_v5SenseError m389 : 56|1@1+ (1,0) [0|0] "" Vector__XXX
 SG_ TRCM_a600_extAsic1HasFailure m600 : 56|1@1+ (1,0) [0|0] "" Vector__XXX
 SG_ TRCM_a389_covractPinAsserted m389 : 57|1@1+ (1,0) [0|0] "" Vector__XXX
 SG_ TRCM_a600_extAsic2HasFailure m600 : 57|1@1+ (1,0) [0|0] "" Vector__XXX
 SG_ TRCM_a389_extAsicPGNDGroundLoss m389 : 58|1@1+ (1,0) [0|0] "" Vector__XXX
 SG_ TRCM_a389_extAsicSysBoostOverVoltage m389 : 59|1@1+ (1,0) [0|0] "" Vector__XXX
 SG_ TRCM_a148_protocolRev m148 : 60|4@1+ (1,0) [0|0] "" Vector__XXX
 SG_ TRCM_a153_protocolRev m153 : 60|4@1+ (1,0) [0|0] "" Vector__XXX
 SG_ TRCM_a158_protocolRev m158 : 60|4@1+ (1,0) [0|0] "" Vector__XXX
 SG_ TRCM_a163_protocolRev m163 : 60|4@1+ (1,0) [0|0] "" Vector__XXX
 SG_ TRCM_a168_protocolRev m168 : 60|4@1+ (1,0) [0|0] "" Vector__XXX
 SG_ TRCM_a173_protocolRev m173 : 60|4@1+ (1,0) [0|0] "" Vector__XXX
 SG_ TRCM_a178_protocolRev m178 : 60|4@1+ (1,0) [0|0] "" Vector__XXX
 SG_ TRCM_a203_protocolRev m203 : 60|4@1+ (1,0) [0|0] "" Vector__XXX
 SG_ TRCM_a208_protocolRev m208 : 60|4@1+ (1,0) [0|0] "" Vector__XXX
 SG_ TRCM_a389_extAsicSysBoostUnderVoltage m389 : 60|1@1+ (1,0) [0|0] "" Vector__XXX
 SG_ TRCM_a389_extAsicSatBuckUnderVoltage m389 : 61|1@1+ (1,0) [0|0] "" Vector__XXX
 SG_ TRCM_a389_extAsicVinBadAsserted m389 : 62|1@1+ (1,0) [0|0] "" Vector__XXX
 SG_ TRCM_a058_faultReason m58 : 63|1@1+ (1,0) [0|0] "" Vector__XXX
 SG_ TRCM_a389_extAsicVinGoodDeasserted m389 : 63|1@1+ (1,0) [0|0] "" Vector__XXX

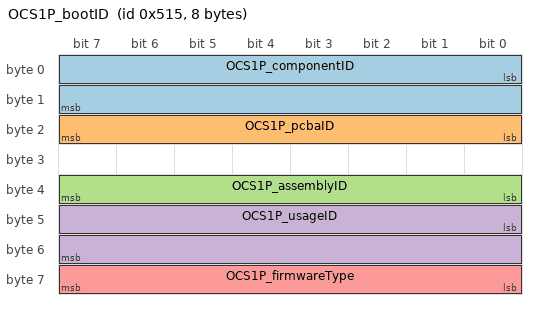
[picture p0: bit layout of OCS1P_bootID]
BO_ 1301 OCS1P_bootID: 8 Vector__XXX
 SG_ OCS1P_componentID : 0|16@1+ (1,0) [0|0] "" Vector__XXX
 SG_ OCS1P_pcbaID : 16|8@1+ (1,0) [0|0] "" Vector__XXX
 SG_ OCS1P_assemblyID : 32|8@1+ (1,0) [0|0] "" Vector__XXX
 SG_ OCS1P_usageID : 40|16@1+ (1,0) [0|0] "" Vector__XXX
 SG_ OCS1P_firmwareType : 56|8@1+ (1,0) [0|0] "" Vector__XXX

BO_ 1327 GTW_epochTimeGtw: 12 Vector__XXX
 SG_ GTW_epoch_ns : 7|64@0+ (1,0) [0|0] "" Vector__XXX

BO_ 1329 RADC_info: 8 Vector__XXX
 SG_ RADC_infoIndex M : 0|8@1+ (1,0) [0|0] "" Vector__XXX
 SG_ RADC_infoBootUdsProtoVersion m20 : 8|8@1+ (1,0) [0|0] "" Vector__XXX
 SG_ RADC_infoBuildType m10 : 8|8@1+ (1,0) [0|0] "" Vector__XXX
 SG_ RADC_infoPlatformType m19 : 8|8@1+ (1,0) [0|0] "" Vector__XXX
 SG_ RADC_infoBuildConfigID m10 : 16|16@1+ (1,0) [0|0] "" Vector__XXX
 SG_ RADC_infoMajorVersion m19 : 16|8@1+ (1,0) [0|0] "" Vector__XXX
 SG_ RADC_infoPcbaID m11 : 16|8@1+ (1,0) [0|0] "" Vector__XXX
 SG_ RADC_infoAssemblyID m11 : 24|8@1+ (1,0) [0|0] "" Vector__XXX
 SG_ RADC_infoBranchOrigin m19 : 24|8@1+ (1,0) [0|0] "" Vector__XXX
 SG_ RADC_infoApplicationCRC m13 : 32|32@1+ (1,0) [0|0] "" Vector__XXX
 SG_ RADC_infoBootloaderCRC m20 : 32|32@1+ (1,0) [0|0] "" Vector__XXX
 SG_ RADC_infoHardwareID m10 : 32|16@1+ (1,0) [0|0] "" Vector__XXX
 SG_ RADC_infoMaturity m19 : 32|8@1+ (1,0) [0|0] "" Vector__XXX
 SG_ RADC_infoUsageID m11 : 32|16@1+ (1,0) [0|0] "" Vector__XXX
 SG_ RADC_infoHardwareRevision m19 : 40|8@1+ (1,0) [0|0] "" Vector__XXX
 SG_ RADC_infoComponentID m10 : 48|16@1+ (1,0) [0|0] "" Vector__XXX
 SG_ RADC_infoSubUsageID m11 : 48|16@1+ (1,0) [0|0] "" Vector__XXX

BO_ 1332 VCFRONT_alertLog: 8 Vector__XXX
 SG_ VCFRONT_alertID M : 0|10@1+ (1,0) [0|0] "" Vector__XXX
 SG_ VCFRONT_alertState : 15|1@1+ (1,0) [0|0] "" Vector__XXX
 SG_ VCFRONT_a000_alertDataW0 m0 : 16|16@1+ (1,0) [0|0] "" Vector__XXX
 SG_ VCFRONT_a001_InternalWatchdog m1 : 16|1@1+ (1,0) [0|0] "" Vector__XXX
 SG_ VCFRONT_a002_CPUUndervoltage m2 : 16|1@1+ (1,0) [0|0] "" Vector__XXX
 SG_ VCFRONT_a003_AssertID m3 : 16|16@1+ (1,0) [0|0] "" Vector__XXX
 SG_ VCFRONT_a004_APPWatchdogFaultOrMIA m4 : 16|1@1+ (1,0) [0|0] "" Vector__XXX
 SG_ VCFRONT_a005_busID0 m5 : 16|4@1+ (1,0) [0|0] "" Vector__XXX
 SG_ VCFRONT_a006_busID m6 : 16|4@1+ (1,0) [0|0] "" Vector__XXX
 SG_ VCFRONT_a008_APPWatchdogFaultOrMIA m8 : 16|1@1+ (1,0) [0|0] "" Vector__XXX
 SG_ VCFRONT_a009_purgeTimeSeconds m9 : 16|5@1+ (1,0) [0|0] "" Vector__XXX
 SG_ VCFRONT_a010_UnderVoltageDetected m10 : 16|1@1+ (1,0) [0|0] "" Vector__XXX
 SG_ VCFRONT_a012_ClockError m12 : 16|1@1+ (1,0) [0|0] "" Vector__XXX
 SG_ VCFRONT_a013_LogQueueFull m13 : 16|1@1+ (1,0) [0|0] "" Vector__XXX
 SG_ VCFRONT_a015_NVMMMemOverflow m15 : 16|1@1+ (1,0) [0|0] "" Vector__XXX
 SG_ VCFRONT_a016_NVMMRecordID m16 : 16|16@1+ (1,0) [0|0] "" Vector__XXX
 SG_ VCFRONT_a017_NVMMLifetimeEraseCycles m17 : 16|32@1+ (1,0) [0|0] "" Vector__XXX
 SG_ VCFRONT_a021_Task1msLate m21 : 16|1@1+ (1,0) [0|0] "" Vector__XXX
 SG_ VCFRONT_a022_TaskInitErrorCount m22 : 16|8@1+ (1,0) [0|0] "" Vector__XXX
 SG_ VCFRONT_a030_logId m30 : 16|4@1+ (1,0) [0|0] "" Vector__XXX
 SG_ VCFRONT_a031_uds_bytes_0 m31 : 16|8@1+ (1,0) [0|0] "" Vector__XXX
 SG_ VCFRONT_a032_core m32 : 16|2@1+ (1,0) [0|0] "" Vector__XXX
 SG_ VCFRONT_a033_index m33 : 16|7@1+ (1,0) [0|0] "" Vector__XXX
 SG_ VCFRONT_a038_faultType m38 : 16|2@1+ (1,0) [0|0] "" Vector__XXX
 SG_ VCFRONT_a039_faultType m39 : 16|2@1+ (1,0) [0|0] "" Vector__XXX
 SG_ VCFRONT_a040_depth m40 : 16|4@1+ (1,0) [0|0] "" Vector__XXX
 SG_ VCFRONT_a041_CPULoadTotal m41 : 16|8@1+ (1,0) [0|0] "" Vector__XXX
 SG_ VCFRONT_a042_Usage1msTask m42 : 16|8@1+ (1,0) [0|0] "" Vector__XXX
 SG_ VCFRONT_a043_CallTrace0 m43 : 16|24@1+ (1,0) [0|0] "" Vector__XXX
 SG_ VCFRONT_a044_CallTrace0 m44 : 16|24@1+ (1,0) [0|0] "" Vector__XXX
 SG_ VCFRONT_a045_CallTrace0 m45 : 16|24@1+ (1,0) [0|0] "" Vector__XXX
 SG_ VCFRONT_a046_CallTrace0 m46 : 16|24@1+ (1,0) [0|0] "" Vector__XXX
 SG_ VCFRONT_a047_Wdt m47 : 16|1@1+ (1,0) [0|0] "" Vector__XXX
 SG_ VCFRONT_a057_VEH_cpControl m57 : 16|1@1+ (1,0) [0|0] "" Vector__XXX
 SG_ VCFRONT_a058_voltageDrop m58 : 16|12@1+ (0.005443676098,0) [0|0] "" Vector__XXX
 SG_ VCFRONT_a059_voltageDrop m59 : 16|12@1+ (0.005443676098,0) [0|0] "" Vector__XXX
 SG_ VCFRONT_a060_lockoutDisabled m60 : 16|1@1+ (1,0) [0|0] "" Vector__XXX
 SG_ VCFRONT_a063_switchChannel m63 : 16|8@1+ (1,0) [0|0] "" Vector__XXX
 SG_ VCFRONT_a064_busBitField m64 : 16|8@1+ (1,0) [0|0] "" Vector__XXX
 SG_ VCFRONT_a082_RIPC_epbPrivateState m82 : 16|1@1+ (1,0) [0|0] "" Vector__XXX
 SG_ VCFRONT_a083_LIPC_epbPrivateState m83 : 16|1@1+ (1,0) [0|0] "" Vector__XXX
 SG_ VCFRONT_a084_CH_StatusC m84 : 16|1@1+ (1,0) [0|0] "" Vector__XXX
 SG_ VCFRONT_a085_PARTY_buttonStatus m85 : 16|1@1+ (1,0) [0|0] "" Vector__XXX
 SG_ VCFRONT_a086_VEH_LVBMS_statusHigh m86 : 16|1@1+ (1,0) [0|0] "" Vector__XXX
 SG_ VCFRONT_a087_VEH_temperature m87 : 16|1@1+ (1,0) [0|0] "" Vector__XXX
 SG_ VCFRONT_a088_VEH_temperature m88 : 16|1@1+ (1,0) [0|0] "" Vector__XXX
 SG_ VCFRONT_a089_PARTY_party1 m89 : 16|1@1+ (1,0) [0|0] "" Vector__XXX
 SG_ VCFRONT_a090_VEH_chNm m90 : 16|1@1+ (1,0) [0|0] "" Vector__XXX
 SG_ VCFRONT_a091_VEH_faultsAndExtras m91 : 16|1@1+ (1,0) [0|0] "" Vector__XXX
 SG_ VCFRONT_a092_VEH_restraintStatus m92 : 16|1@1+ (1,0) [0|0] "" Vector__XXX
 SG_ VCFRONT_a093_VEH_restraintStatus m93 : 16|1@1+ (1,0) [0|0] "" Vector__XXX
 SG_ VCFRONT_a094_VEH_sysStatus m94 : 16|1@1+ (1,0) [0|0] "" Vector__XXX
 SG_ VCFRONT_a095_PT_ptNm m95 : 16|1@1+ (1,0) [0|0] "" Vector__XXX
 SG_ VCFRONT_a096_VEH_status m96 : 16|1@1+ (1,0) [0|0] "" Vector__XXX
 SG_ VCFRONT_a097_VEH_HVStatus m97 : 16|1@1+ (1,0) [0|0] "" Vector__XXX
 SG_ VCFRONT_a098_CH_torque m98 : 16|1@1+ (1,0) [0|0] "" Vector__XXX
 SG_ VCFRONT_a099_VEH_oocStatus m99 : 16|1@1+ (1,0) [0|0] "" Vector__XXX
 SG_ VCFRONT_a100_VEH m100 : 16|1@1+ (1,0) [0|0] "" Vector__XXX
 SG_ VCFRONT_a101_VEH_state m101 : 16|1@1+ (1,0) [0|0] "" Vector__XXX
 SG_ VCFRONT_a102_VEH_faultsAndExtras m102 : 16|1@1+ (1,0) [0|0] "" Vector__XXX
 SG_ VCFRONT_a103_VEH_hvsNm m103 : 16|1@1+ (1,0) [0|0] "" Vector__XXX
 SG_ VCFRONT_a104_VEH_defogInfoMessage m104 : 16|1@1+ (1,0) [0|0] "" Vector__XXX
 SG_ VCFRONT_a105_VEH_states m105 : 16|1@1+ (1,0) [0|0] "" Vector__XXX
 SG_ VCFRONT_a106_VEH_dcdcStatus m106 : 16|1@1+ (1,0) [0|0] "" Vector__XXX
 SG_ VCFRONT_a107_VEH_hvsNm m107 : 16|1@1+ (1,0) [0|0] "" Vector__XXX
 SG_ VCFRONT_a108_VEH_hvStatus m108 : 16|1@1+ (1,0) [0|0] "" Vector__XXX
 SG_ VCFRONT_a109_PARTY_status m109 : 16|1@1+ (1,0) [0|0] "" Vector__XXX
 SG_ VCFRONT_a110_VEH_status m110 : 16|1@1+ (1,0) [0|0] "" Vector__XXX
 SG_ VCFRONT_a111_VEH_internalStatus m111 : 16|1@1+ (1,0) [0|0] "" Vector__XXX
 SG_ VCFRONT_a112_VEH_internalStatus m112 : 16|1@1+ (1,0) [0|0] "" Vector__XXX
 SG_ VCFRONT_a113_VEH_ethNm m113 : 16|1@1+ (1,0) [0|0] "" Vector__XXX
 SG_ VCFRONT_a114_PARTY_status m114 : 16|1@1+ (1,0) [0|0] "" Vector__XXX
 SG_ VCFRONT_a115_VEH_vehNm m115 : 16|1@1+ (1,0) [0|0] "" Vector__XXX
 SG_ VCFRONT_a116_PARTY_epbmStatus m116 : 16|1@1+ (1,0) [0|0] "" Vector__XXX
 SG_ VCFRONT_a117_BDY_epbmStatus m117 : 16|1@1+ (1,0) [0|0] "" Vector__XXX
 SG_ VCFRONT_a118_VEH_vehNm m118 : 16|1@1+ (1,0) [0|0] "" Vector__XXX
 SG_ VCFRONT_a119_VEH_steerAngle m119 : 16|1@1+ (1,0) [0|0] "" Vector__XXX
 SG_ VCFRONT_a120_PARTY_chassisCntl m120 : 16|1@1+ (1,0) [0|0] "" Vector__XXX
 SG_ VCFRONT_a121_overCurrentError m121 : 16|1@1+ (1,0) [0|0] "" Vector__XXX
 SG_ VCFRONT_a122_junctionTempWarning m122 : 16|1@1+ (1,0) [0|0] "" Vector__XXX
 SG_ VCFRONT_a123_overCurrentError m123 : 16|1@1+ (1,0) [0|0] "" Vector__XXX
 SG_ VCFRONT_a124_junctionTempWarning m124 : 16|1@1+ (1,0) [0|0] "" Vector__XXX
 SG_ VCFRONT_a125_overCurrentError m125 : 16|1@1+ (1,0) [0|0] "" Vector__XXX
 SG_ VCFRONT_a126_junctionTempWarning m126 : 16|1@1+ (1,0) [0|0] "" Vector__XXX
 SG_ VCFRONT_a127_vcleftEFuseCurrent m127 : 16|16@1+ (0.1,0) [0|0] "" Vector__XXX
 SG_ VCFRONT_a128_vcrightEFuseCurrent m128 : 16|16@1+ (0.1,0) [0|0] "" Vector__XXX
 SG_ VCFRONT_a129_pcsEFuseCurrent m129 : 16|16@1+ (0.1,0) [0|0] "" Vector__XXX

VAL_ 1298 TRCM_alertID 0 "ALERT_DO_NOT_USE_ZERO" 1 "a001_DriverDoorOpen" 2 "a002_DoorOpen" 3 "a003_TrunkOpen" 4 "a004_FrunkOpen" 5 "a005_HeadlightsOnDoorOpen" 6 "a006_RemoteServiceAlert" 7 "a007_SoftPackConfigMismatch" 8 "a008_TouchScreenError" 9 "a009_SquashfsError" 10 "a010_MapsMissing" 11 "a011_IncorrectMap" 12 "a012_NotOnPrivateProperty" 13 "a013_TPMSHardWarning" 14 "a014_TPMSSoftWarning" 15 "a015_TPMSOverPressureWarning" 16 "a016_TPMSTemperatureWarning" 17 "a017_TPMSSystemFault" 18 "a018_SlipStartOn" 19 "a019_ParkBrakeFault" 20 "a020_SteeringReduced" 21 "a021_RearSeatbeltUnbuckled" 22 "a022_ApeFusesEtc" 23 "a023_CellInternetCheckFailed" 24 "a024_WifiInternetCheckFailed" 25 "a025_WifiOnlineCheckFailed" 26 "a026_ModemResetLoopDetected" 27 "a027_AutoSteerMIA" 28 "a028_FrontTrunkPopupClosed" 29 "a029_ModemMIA" 30 "a030_ModemVMCrash" 31 "a031_BrakeFluidLow" 32 "a032_CellModemRecoveryResets" 33 "a033_ApTrialExpired" 34 "a034_WakeupProblem" 35 "a035_AudioWatchdogKernelError" 36 "a036_AudioWatchdogHfpError" 37 "a037_AudioWatchdogXrunStormError" 38 "a038_AudioWatchdogA2bI2cLockupError" 39 "a039_AudioA2bNeedRediscovery" 40 "a040_HomelinkTransmit" 41 "a041_AudioDmesgXrun" 42 "a042_AudioDmesgRtThrottling" 43 "a043_InvalidMapDataOverride" 44 "a044_AudioDmesgDspException" 45 "a045_ECallNeedsService" 46 "a046_BackupCameraStreamError" 47 "a047_CellRoamingDisallowed" 48 "a048_AudioPremiumAmpCheckFailed" 49 "a049_BrakeShiftRequired" 50 "a050_BackupCameraIPUTimeout" 51 "a051_BackupCameraFrameTimeout" 52 "a052_KernelPanicReported" 53 "a053_QtCarExitError" 54 "a054_AudioBoostPowerBad" 55 "a055_ManualECallDisabled" 56 "a056_ManualECallButtonDisconnected" 57 "a057_CellAntennaDisconnected" 58 "a058_GPSAntennaDisconnected" 59 "a059_ECallSpeakerDisconnected" 60 "a060_ECallMicDisconnected" 61 "a061_SIMTestFailed" 62 "a062_ENSTestFailed" 63 "a063_CellularTestFailed" 64 "a064_ModemFirmwareTestFailed" 65 "a065_WiFiRecoveryReset" 66 "a066_GpuHangDetected" 67 "a067_WarnOnI915" 68 "a068_VideoUnexpectedExit" 69 "a069_VideoUDPTimeout" 70 "a070_VideoPipelineWarning" 71 "a071_VideoPipelineError" 72 "a072_ECallAnalogMicFailed" 73 "a073_ECallDigitalMicFailed" 74 "a074_EMMCHangDetected" 75 "a075_BackupCameraInitError" 76 "a076_NumFalseManualECalls" 77 "a077_AudioA2bMicChannelSwap" 78 "a078_DashcamUsbDriveUnmountable" 79 "a079_DashcamUsbDriveFull" 80 "a080_DashcamUsbDriveSlow" 81 "a081_CellModemSearchExpired" 82 "a082_NumModemRebootStuckInECall" 83 "a083_ECallProxyWatchdogTriggered" 84 "a084_SerializerError" 85 "a085_DeserializerError" 86 "a086_TouchEnumerationError" 87 "a087_BmpReset" 88 "a088_CellRemovableSimMissing" 89 "a089_RadioSoftResetError" 90 "a090_RadioPingFailError" 91 "a091_VehicleLinkStall" 92 "a092_updateStarted" 93 "a093_updateEnded" 94 "a094_ModemPowerOnFailure" 95 "a095_CidStorageRunningLow" 96 "a096_VideodPipelineIssueDetected" 97 "a097_AudiodRestarted" 98 "a098_DiskCheckFailure" 99 "a099_eMMCStatusError" 100 "a100_eMMCFTLError" 101 "a101_wifiStackProblem" 102 "a102_A2bDiscoveryFailed" 103 "a103_UsbHubNotEnumerating" 104 "a104_DashcamUsbDriveMissing" 105 "a105_firmwareReinstallRequested" 106 "a106_rebootBackstopTriggered" 107 "a107_DashcamUsbDriveTooBigForVfatFsck" 108 "a108_DashcamUsbDriveGettingFull" 109 "a109_DashcamUsbDriveTooSmall" 110 "a110_DashcamUsbDriveCorrupt" 111 "a111_DashcamUsbDriveWrongPort" 112 "a112_badUSBDevice" 113 "a113_DashcamHasOnboardSentryClips" ;
VAL_ 1298 TRCM_alertState 0 "CLEARED" 1 "SET" ;
VAL_ 1298 TRCM_a031_uds_bytes_0 0 "0" 1 "1" 2 "2" 3 "3" 4 "4" 5 "5" 6 "6" 7 "7" 8 "8" 9 "9" 10 "10" 11 "11" 12 "12" 13 "13" 14 "14" 15 "15" 16 "16" 17 "17" 18 "18" 19 "19" 20 "20" 21 "21" 22 "22" 23 "23" 24 "24" 25 "25" 26 "26" 27 "27" 28 "28" 29 "29" 30 "30" 31 "31" ;
VAL_ 1298 TRCM_a037_nearDeployFront 0 "INACTIVE" 1 "ACTIVE" 3 "SNA" ;
VAL_ 1298 TRCM_a096_VEH_status 0 "DISABLED" 1 "ENABLED" 2 "TEMPORARY_FAILURE" 3 "SNA" ;
VAL_ 1298 TRCM_a101_VEH_state 0 "STANDBY" 1 "DRIVE" 2 "SUPPORT" 3 "CHARGE" 4 "FEIM" 5 "CLEAR_FAULT" 6 "FAULT" 7 "WELD" 8 "TEST" 9 "SNA" 10 "DIAG" ;
VAL_ 1298 TRCM_a109_PARTY_status 0 "DISABLED" 1 "ENABLED" 2 "TEMPORARY_FAILURE" 3 "SNA" ;
VAL_ 1298 TRCM_a114_PARTY_status 0 "DISABLED" 1 "ENABLED" 2 "TEMPORARY_FAILURE" 3 "SNA" ;
VAL_ 1298 TRCM_a037_nearDeployRear 0 "INACTIVE" 1 "ACTIVE" 3 "SNA" ;
VAL_ 1298 TRCM_a070_S_OK_C 31 "SNA" ;
VAL_ 1298 TRCM_a089_PARTY_status 0 "DISABLED" 1 "ENABLED" 2 "TEMPORARY_FAILURE" 3 "SNA" ;
VAL_ 1298 TRCM_a090_VEH_state 0 "STANDBY" 1 "DRIVE" 2 "SUPPORT" 3 "CHARGE" 4 "FEIM" 5 "CLEAR_FAULT" 6 "FAULT" 7 "WELD" 8 "TEST" 9 "SNA" 10 "DIAG" ;
VAL_ 1298 TRCM_a095_PT_status 0 "DISABLED" 1 "ENABLED" 2 "TEMPORARY_FAILURE" 3 "SNA" ;
VAL_ 1298 TRCM_a096_CH_status 0 "DISABLED" 1 "ENABLED" 2 "TEMPORARY_FAILURE" 3 "SNA" ;
VAL_ 1298 TRCM_a097_VEH_state 0 "STANDBY" 1 "DRIVE" 2 "SUPPORT" 3 "CHARGE" 4 "FEIM" 5 "CLEAR_FAULT" 6 "FAULT" 7 "WELD" 8 "TEST" 9 "SNA" 10 "DIAG" ;
VAL_ 1298 TRCM_a111_VEH_status 0 "DISABLED" 1 "ENABLED" 2 "TEMPORARY_FAILURE" 3 "SNA" ;
VAL_ 1298 TRCM_a112_VEH_status 0 "DISABLED" 1 "ENABLED" 2 "TEMPORARY_FAILURE" 3 "SNA" ;
VAL_ 1298 TRCM_a120_VEH_systemStatus 0 "UNKNOWN" 1 "RELEASED" 2 "PARKED" 3 "DYNAMIC" 4 "PARKING" 5 "RELEASING" 6 "FAULT" 7 "FAULT_SECURE" 8 "MISMATCH" ;
VAL_ 1298 TRCM_a135_S_OK_C 31 "SNA" ;
VAL_ 1298 TRCM_a037_nearDeployLeft 0 "INACTIVE" 1 "ACTIVE" 3 "SNA" ;
VAL_ 1298 TRCM_a086_VEH_status 0 "DISABLED" 1 "ENABLED" 2 "TEMPORARY_FAILURE" 3 "SNA" ;
VAL_ 1298 TRCM_a089_VEH_status 0 "DISABLED" 1 "ENABLED" 2 "TEMPORARY_FAILURE" 3 "SNA" ;
VAL_ 1298 TRCM_a091_VEH_state 0 "STANDBY" 1 "DRIVE" 2 "SUPPORT" 3 "CHARGE" 4 "FEIM" 5 "CLEAR_FAULT" 6 "FAULT" 7 "WELD" 8 "TEST" 9 "SNA" 10 "DIAG" ;
VAL_ 1298 TRCM_a098_VEH_status 0 "DISABLED" 1 "ENABLED" 2 "TEMPORARY_FAILURE" 3 "SNA" ;
VAL_ 1298 TRCM_a103_VEH_status 0 "DISABLED" 1 "ENABLED" 2 "TEMPORARY_FAILURE" 3 "SNA" ;
VAL_ 1298 TRCM_a107_VEH_status 0 "DISABLED" 1 "ENABLED" 2 "TEMPORARY_FAILURE" 3 "SNA" ;
VAL_ 1298 TRCM_a037_nearDeployRight 0 "INACTIVE" 1 "ACTIVE" 3 "SNA" ;
VAL_ 1298 TRCM_a087_VEH_status 0 "DISABLED" 1 "ENABLED" 2 "TEMPORARY_FAILURE" 3 "SNA" ;
VAL_ 1298 TRCM_a088_VEH_status 0 "DISABLED" 1 "ENABLED" 2 "TEMPORARY_FAILURE" 3 "SNA" ;
VAL_ 1298 TRCM_a118_VEH_status 0 "DISABLED" 1 "ENABLED" 2 "TEMPORARY_FAILURE" 3 "SNA" ;
VAL_ 1298 TRCM_a120_PARTY_systemStatus 0 "UNKNOWN" 1 "RELEASED" 2 "PARKED" 3 "DYNAMIC" 4 "PARKING" 5 "RELEASING" 6 "FAULT" 7 "FAULT_SECURE" 8 "MISMATCH" ;
VAL_ 1298 TRCM_a036_collisionSeverity 0 "PRETENSIONER" 1 "FIRST_STAGE" 2 "SECOND_STAGE" 3 "PEDPRO_EVENT" ;
VAL_ 1298 TRCM_a089_BDY_status 0 "DISABLED" 1 "ENABLED" 2 "TEMPORARY_FAILURE" 3 "SNA" ;
VAL_ 1298 TRCM_a103_PT_status 0 "DISABLED" 1 "ENABLED" 2 "TEMPORARY_FAILURE" 3 "SNA" ;
VAL_ 1298 TRCM_a108_VEH_status 0 "DISABLED" 1 "ENABLED" 2 "TEMPORARY_FAILURE" 3 "SNA" ;
VAL_ 1298 TRCM_a109_VEH_status 0 "DISABLED" 1 "ENABLED" 2 "TEMPORARY_FAILURE" 3 "SNA" ;
VAL_ 1298 TRCM_a087_PARTY_status 0 "DISABLED" 1 "ENABLED" 2 "TEMPORARY_FAILURE" 3 "SNA" ;
VAL_ 1298 TRCM_a088_PARTY_status 0 "DISABLED" 1 "ENABLED" 2 "TEMPORARY_FAILURE" 3 "SNA" ;
VAL_ 1298 TRCM_a089_CH_status 0 "DISABLED" 1 "ENABLED" 2 "TEMPORARY_FAILURE" 3 "SNA" ;
VAL_ 1298 TRCM_a086_VEH_systemStatus 0 "UNKNOWN" 1 "RELEASED" 2 "PARKED" 3 "DYNAMIC" 4 "PARKING" 5 "RELEASING" 6 "FAULT" 7 "FAULT_SECURE" 8 "MISMATCH" ;
VAL_ 1298 TRCM_a098_PARTY_status 0 "DISABLED" 1 "ENABLED" 2 "TEMPORARY_FAILURE" 3 "SNA" ;
VAL_ 1298 TRCM_a108_PARTY_status 0 "DISABLED" 1 "ENABLED" 2 "TEMPORARY_FAILURE" 3 "SNA" ;
VAL_ 1298 TRCM_a114_VEH_status 0 "DISABLED" 1 "ENABLED" 2 "TEMPORARY_FAILURE" 3 "SNA" ;
VAL_ 1298 TRCM_a107_PT_status 0 "DISABLED" 1 "ENABLED" 2 "TEMPORARY_FAILURE" 3 "SNA" ;
VAL_ 1298 TRCM_a078_value 4294934528 "SNA" ;
VAL_ 1298 TRCM_a149_value 4294934528 "SNA" ;
VAL_ 1298 TRCM_a154_value 4294934528 "SNA" ;
VAL_ 1298 TRCM_a159_value 4294934528 "SNA" ;
VAL_ 1298 TRCM_a164_value 4294934528 "SNA" ;
VAL_ 1298 TRCM_a169_value 4294934528 "SNA" ;
VAL_ 1298 TRCM_a174_value 4294934528 "SNA" ;
VAL_ 1298 TRCM_a179_value 4294934528 "SNA" ;
VAL_ 1298 TRCM_a204_value 4294934528 "SNA" ;
VAL_ 1298 TRCM_a209_value 4294934528 "SNA" ;
VAL_ 1298 TRCM_a276_watchdogState 0 "UNKNOWN" 1 "DEGRADED" 2 "CRITICAL" 3 "HEALTHY" 7 "SNA" ;
VAL_ 1298 TRCM_a104_CH_status 0 "DISABLED" 1 "ENABLED" 2 "TEMPORARY_FAILURE" 3 "SNA" ;
VAL_ 1298 TRCM_a112_PARTY_status 0 "DISABLED" 1 "ENABLED" 2 "TEMPORARY_FAILURE" 3 "SNA" ;
VAL_ 1298 TRCM_a118_VEH_systemStatus 0 "UNKNOWN" 1 "RELEASED" 2 "PARKED" 3 "DYNAMIC" 4 "PARKING" 5 "RELEASING" 6 "FAULT" 7 "FAULT_SECURE" 8 "MISMATCH" ;
VAL_ 1298 TRCM_a120_PARTY_status 0 "DISABLED" 1 "ENABLED" 2 "TEMPORARY_FAILURE" 3 "SNA" ;
VAL_ 1298 TRCM_a104_PARTY_status 0 "DISABLED" 1 "ENABLED" 2 "TEMPORARY_FAILURE" 3 "SNA" ;
VAL_ 1298 TRCM_a109_BDY_status 0 "DISABLED" 1 "ENABLED" 2 "TEMPORARY_FAILURE" 3 "SNA" ;
VAL_ 1298 TRCM_a110_CH_airbagCutoffStatus 0 "RCM_PASSENGER_AIRBAG_ENABLED" 1 "RCM_PASSENGER_AIRBAG_DISABLED" 3 "SNA" ;
VAL_ 1298 TRCM_a111_PARTY_status 0 "DISABLED" 1 "ENABLED" 2 "TEMPORARY_FAILURE" 3 "SNA" ;
VAL_ 1298 TRCM_a112_CH_status 0 "DISABLED" 1 "ENABLED" 2 "TEMPORARY_FAILURE" 3 "SNA" ;
VAL_ 1298 TRCM_a111_CH_status 0 "DISABLED" 1 "ENABLED" 2 "TEMPORARY_FAILURE" 3 "SNA" ;
VAL_ 1298 TRCM_a120_PT_systemStatus 0 "UNKNOWN" 1 "RELEASED" 2 "PARKED" 3 "DYNAMIC" 4 "PARKING" 5 "RELEASING" 6 "FAULT" 7 "FAULT_SECURE" 8 "MISMATCH" ;
VAL_ 1298 TRCM_a114_BDY_status 0 "DISABLED" 1 "ENABLED" 2 "TEMPORARY_FAILURE" 3 "SNA" ;
VAL_ 1298 TRCM_a116_VEH_status 0 "DISABLED" 1 "ENABLED" 2 "TEMPORARY_FAILURE" 3 "SNA" ;
VAL_ 1298 TRCM_a109_CH_status 0 "DISABLED" 1 "ENABLED" 2 "TEMPORARY_FAILURE" 3 "SNA" ;
VAL_ 1298 TRCM_a113_VEH_status 0 "DISABLED" 1 "ENABLED" 2 "TEMPORARY_FAILURE" 3 "SNA" ;
VAL_ 1298 TRCM_a104_VEH_status 0 "DISABLED" 1 "ENABLED" 2 "TEMPORARY_FAILURE" 3 "SNA" ;
VAL_ 1298 TRCM_a114_CH_status 0 "DISABLED" 1 "ENABLED" 2 "TEMPORARY_FAILURE" 3 "SNA" ;
VAL_ 1298 TRCM_a117_VEH_status 0 "DISABLED" 1 "ENABLED" 2 "TEMPORARY_FAILURE" 3 "SNA" ;
VAL_ 1298 TRCM_a104_BDY_status 0 "DISABLED" 1 "ENABLED" 2 "TEMPORARY_FAILURE" 3 "SNA" ;
VAL_ 1298 TRCM_a148_sensorType 0 "NONE" 1 "VALEO_HPFL" 2 "VALEO_HP" 3 "SNA" ;
VAL_ 1298 TRCM_a153_sensorType 0 "NONE" 1 "VALEO_HPFL" 2 "VALEO_HP" 3 "SNA" ;
VAL_ 1298 TRCM_a158_sensorType 0 "NONE" 1 "VALEO_HPFL" 2 "VALEO_HP" 3 "SNA" ;
VAL_ 1298 TRCM_a163_sensorType 0 "NONE" 1 "VALEO_HPFL" 2 "VALEO_HP" 3 "SNA" ;
VAL_ 1298 TRCM_a168_sensorType 0 "NONE" 1 "VALEO_HPFL" 2 "VALEO_HP" 3 "SNA" ;
VAL_ 1298 TRCM_a173_sensorType 0 "NONE" 1 "VALEO_HPFL" 2 "VALEO_HP" 3 "SNA" ;
VAL_ 1298 TRCM_a178_sensorType 0 "NONE" 1 "VALEO_HPFL" 2 "VALEO_HP" 3 "SNA" ;
VAL_ 1298 TRCM_a203_sensorType 0 "NONE" 1 "VALEO_HPFL" 2 "VALEO_HP" 3 "SNA" ;
VAL_ 1298 TRCM_a208_sensorType 0 "NONE" 1 "VALEO_HPFL" 2 "VALEO_HP" 3 "SNA" ;
VAL_ 1329 RADC_infoIndex 10 "Mux10" 11 "Mux11" 13 "Mux13" 19 "Mux19" 20 "Mux20" ;
VAL_ 1329 RADC_infoBuildType 0 "UNKNOWN_BUILD" 1 "PLATFORM_BUILD" 2 "LOCAL_BUILD" 3 "TRACEABLE_CI_BUILD" 4 "MFG_BUILD" ;
VAL_ 1329 RADC_infoMajorVersion 254 "LOCAL_BUILD" 255 "SNA" ;
VAL_ 1329 RADC_infoBranchOrigin 254 "LOCAL_BUILD" 255 "SNA" ;
VAL_ 1329 RADC_infoMaturity 254 "LOCAL_BUILD" 255 "SNA" ;
VAL_ 1329 RADC_infoHardwareRevision 252 "CONFIGURABLE_HWID_PLACEHOLDER" ;
VAL_ 1332 VCFRONT_alertID 0 "ALERT_DO_NOT_USE_ZERO" 1 "a001_DriverDoorOpen" 2 "a002_DoorOpen" 3 "a003_TrunkOpen" 4 "a004_FrunkOpen" 5 "a005_HeadlightsOnDoorOpen" 6 "a006_RemoteServiceAlert" 7 "a007_SoftPackConfigMismatch" 8 "a008_TouchScreenError" 9 "a009_SquashfsError" 10 "a010_MapsMissing" 11 "a011_IncorrectMap" 12 "a012_NotOnPrivateProperty" 13 "a013_TPMSHardWarning" 14 "a014_TPMSSoftWarning" 15 "a015_TPMSOverPressureWarning" 16 "a016_TPMSTemperatureWarning" 17 "a017_TPMSSystemFault" 18 "a018_SlipStartOn" 19 "a019_ParkBrakeFault" 20 "a020_SteeringReduced" 21 "a021_RearSeatbeltUnbuckled" 22 "a022_ApeFusesEtc" 23 "a023_CellInternetCheckFailed" 24 "a024_WifiInternetCheckFailed" 25 "a025_WifiOnlineCheckFailed" 26 "a026_ModemResetLoopDetected" 27 "a027_AutoSteerMIA" 28 "a028_FrontTrunkPopupClosed" 29 "a029_ModemMIA" 30 "a030_ModemVMCrash" 31 "a031_BrakeFluidLow" 32 "a032_CellModemRecoveryResets" 33 "a033_ApTrialExpired" 34 "a034_WakeupProblem" 35 "a035_AudioWatchdogKernelError" 36 "a036_AudioWatchdogHfpError" 37 "a037_AudioWatchdogXrunStormError" 38 "a038_AudioWatchdogA2bI2cLockupError" 39 "a039_AudioA2bNeedRediscovery" 40 "a040_HomelinkTransmit" 41 "a041_AudioDmesgXrun" 42 "a042_AudioDmesgRtThrottling" 43 "a043_InvalidMapDataOverride" 44 "a044_AudioDmesgDspException" 45 "a045_ECallNeedsService" 46 "a046_BackupCameraStreamError" 47 "a047_CellRoamingDisallowed" 48 "a048_AudioPremiumAmpCheckFailed" 49 "a049_BrakeShiftRequired" 50 "a050_BackupCameraIPUTimeout" 51 "a051_BackupCameraFrameTimeout" 52 "a052_KernelPanicReported" 53 "a053_QtCarExitError" 54 "a054_AudioBoostPowerBad" 55 "a055_ManualECallDisabled" 56 "a056_ManualECallButtonDisconnected" 57 "a057_CellAntennaDisconnected" 58 "a058_GPSAntennaDisconnected" 59 "a059_ECallSpeakerDisconnected" 60 "a060_ECallMicDisconnected" 61 "a061_SIMTestFailed" 62 "a062_ENSTestFailed" 63 "a063_CellularTestFailed" 64 "a064_ModemFirmwareTestFailed" 65 "a065_WiFiRecoveryReset" 66 "a066_GpuHangDetected" 67 "a067_WarnOnI915" 68 "a068_VideoUnexpectedExit" 69 "a069_VideoUDPTimeout" 70 "a070_VideoPipelineWarning" 71 "a071_VideoPipelineError" 72 "a072_ECallAnalogMicFailed" 73 "a073_ECallDigitalMicFailed" 74 "a074_EMMCHangDetected" 75 "a075_BackupCameraInitError" 76 "a076_NumFalseManualECalls" 77 "a077_AudioA2bMicChannelSwap" 78 "a078_DashcamUsbDriveUnmountable" 79 "a079_DashcamUsbDriveFull" 80 "a080_DashcamUsbDriveSlow" 81 "a081_CellModemSearchExpired" 82 "a082_NumModemRebootStuckInECall" 83 "a083_ECallProxyWatchdogTriggered" 84 "a084_SerializerError" 85 "a085_DeserializerError" 86 "a086_TouchEnumerationError" 87 "a087_BmpReset" 88 "a088_CellRemovableSimMissing" 89 "a089_RadioSoftResetError" 90 "a090_RadioPingFailError" 91 "a091_VehicleLinkStall" 92 "a092_updateStarted" 93 "a093_updateEnded" 94 "a094_ModemPowerOnFailure" 95 "a095_CidStorageRunningLow" 96 "a096_VideodPipelineIssueDetected" 97 "a097_AudiodRestarted" 98 "a098_DiskCheckFailure" 99 "a099_eMMCStatusError" 100 "a100_eMMCFTLError" 101 "a101_wifiStackProblem" 102 "a102_A2bDiscoveryFailed" 103 "a103_UsbHubNotEnumerating" 104 "a104_DashcamUsbDriveMissing" 105 "a105_firmwareReinstallRequested" 106 "a106_rebootBackstopTriggered" 107 "a107_DashcamUsbDriveTooBigForVfatFsck" 108 "a108_DashcamUsbDriveGettingFull" 109 "a109_DashcamUsbDriveTooSmall" 110 "a110_DashcamUsbDriveCorrupt" 111 "a111_DashcamUsbDriveWrongPort" 112 "a112_badUSBDevice" 113 "a113_DashcamHasOnboardSentryClips" ;
VAL_ 1332 VCFRONT_alertState 0 "CLEARED" 1 "SET" ;
VAL_ 1332 VCFRONT_a031_uds_bytes_0 0 "0" 1 "1" 2 "2" 3 "3" 4 "4" 5 "5" 6 "6" 7 "7" 8 "8" 9 "9" 10 "10" 11 "11" 12 "12" 13 "13" 14 "14" 15 "15" 16 "16" 17 "17" 18 "18" 19 "19" 20 "20" 21 "21" 22 "22" 23 "23" 24 "24" 25 "25" 26 "26" 27 "27" 28 "28" 29 "29" 30 "30" 31 "31" ;
VAL_ 1332 VCFRONT_a096_VEH_status 0 "DISABLED" 1 "ENABLED" 2 "TEMPORARY_FAILURE" 3 "SNA" ;
VAL_ 1332 VCFRONT_a101_VEH_state 0 "STANDBY" 1 "DRIVE" 2 "SUPPORT" 3 "CHARGE" 4 "FEIM" 5 "CLEAR_FAULT" 6 "FAULT" 7 "WELD" 8 "TEST" 9 "SNA" 10 "DIAG" ;
VAL_ 1332 VCFRONT_a109_PARTY_status 0 "DISABLED" 1 "ENABLED" 2 "TEMPORARY_FAILURE" 3 "SNA" ;
VAL_ 1332 VCFRONT_a110_VEH_status 0 "DISABLED" 1 "ENABLED" 2 "TEMPORARY_FAILURE" 3 "SNA" ;
VAL_ 1332 VCFRONT_a114_PARTY_status 0 "DISABLED" 1 "ENABLED" 2 "TEMPORARY_FAILURE" 3 "SNA" ;
